VERSION ""

NS_ :

BS_:

BU_: EBOOST_HS CGM_HS BSM_HS HCP_B_HS AVM_HS PFAF_HS LVMPC_HS DCDC_HS TRCM_HS AMP_HS VICM2_HS FICM_HS ARS_HS MCP_B_HS MCP_A_HS ICCM_OBD_HS SAS_HS ACCM_HS VLBS_HS EBCM_OBD_HS HCP_T_HS EDI_HS HPCC_HS VITM_OBD_HS VICM_HS HCP_HS APPS_HS ICCM_HS EOCM_F_HS GPCM_HS VCM_HS HMIM_HS VES_HS Dummy_HS MCP_C_HS ONSTAR_HS EPS_HS TestTool_HS MCP_HS BCP_HS ALC_HS AHL_AFL_HS SADS_HS EPB_HS FCM_HS TCCM_HS RDCM_HS PTO_HS EBCM_HS ACC_HS BCM_HS TCM_HS ECM_HS

BO_ 565 Performan_Mode_Cust_Setings_1_HS: 5 EBCM_HS
 SG_ PerfMdMainMenuType : 2|3@0+ (1,0) [0|7] ""  BCM_HS
 SG_ PSPMCA_PsngStPrfMd6Avl : 24|1@0+ (1,0) [0|1] ""  BCM_HS
 SG_ PSPMCA_PsngStPrfMd5Avl : 25|1@0+ (1,0) [0|1] ""  BCM_HS
 SG_ PSPMCA_PsngStPrfMd4Avl : 26|1@0+ (1,0) [0|1] ""  BCM_HS
 SG_ PSPMCA_PsngStPrfMd3Avl : 27|1@0+ (1,0) [0|1] ""  BCM_HS
 SG_ PSPMCA_PsngStPrfMd2Avl : 28|1@0+ (1,0) [0|1] ""  BCM_HS
 SG_ PSPMCA_PsngStPrfMd1Avl : 29|1@0+ (1,0) [0|1] ""  BCM_HS
 SG_ DSPMCA_DrvStyPrfMd7Avl : 32|1@0+ (1,0) [0|1] ""  BCM_HS
 SG_ DSPMCA_DrvStyPrfMd6Avl : 33|1@0+ (1,0) [0|1] ""  BCM_HS
 SG_ DSPMCA_DrvStyPrfMd5Avl : 34|1@0+ (1,0) [0|1] ""  BCM_HS
 SG_ DSPMCA_DrvStyPrfMd4Avl : 35|1@0+ (1,0) [0|1] ""  BCM_HS
 SG_ DSPMCA_DrvStyPrfMd3Avl : 36|1@0+ (1,0) [0|1] ""  BCM_HS
 SG_ DSPMCA_DrvStyPrfMd2Avl : 37|1@0+ (1,0) [0|1] ""  BCM_HS
 SG_ DSPMCA_DrvStyPrfMd1Avl : 38|1@0+ (1,0) [0|1] ""  BCM_HS
 SG_ DSPMCA_DrvrStPrfMd6Avl : 16|1@0+ (1,0) [0|1] ""  BCM_HS
 SG_ DSPMCA_DrvrStPrfMd5Avl : 17|1@0+ (1,0) [0|1] ""  BCM_HS
 SG_ DSPMCA_DrvrStPrfMd4Avl : 18|1@0+ (1,0) [0|1] ""  BCM_HS
 SG_ DSPMCA_DrvrStPrfMd3Avl : 19|1@0+ (1,0) [0|1] ""  BCM_HS
 SG_ DSPMCA_DrvrStPrfMd2Avl : 20|1@0+ (1,0) [0|1] ""  BCM_HS
 SG_ DSPMCA_DrvrStPrfMd1Avl : 21|1@0+ (1,0) [0|1] ""  BCM_HS
 SG_ ACCPMCA_ACCPrfMd6Avl : 8|1@0+ (1,0) [0|1] ""  BCM_HS
 SG_ ACCPMCA_ACCPrfMd5Avl : 9|1@0+ (1,0) [0|1] ""  BCM_HS
 SG_ ACCPMCA_ACCPrfMd4Avl : 10|1@0+ (1,0) [0|1] ""  BCM_HS
 SG_ ACCPMCA_ACCPrfMd3Avl : 11|1@0+ (1,0) [0|1] ""  BCM_HS
 SG_ ACCPMCA_ACCPrfMd2Avl : 12|1@0+ (1,0) [0|1] ""  BCM_HS
 SG_ ACCPMCA_ACCPrfMd1Avl : 13|1@0+ (1,0) [0|1] ""  BCM_HS

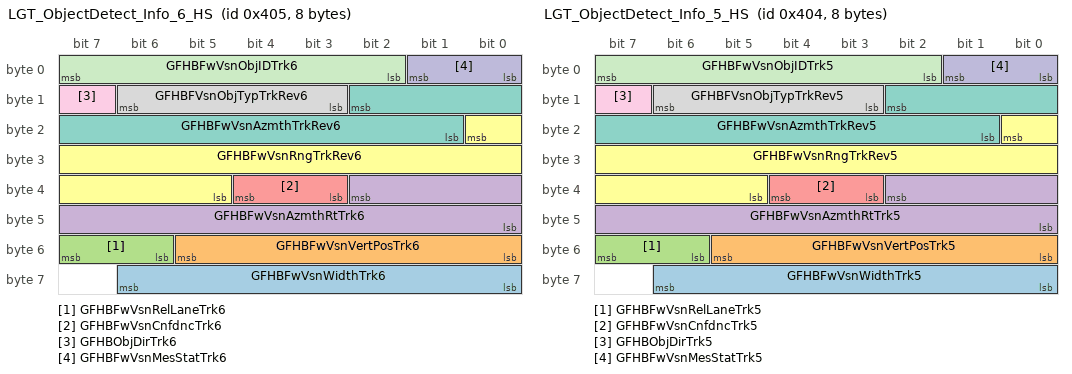
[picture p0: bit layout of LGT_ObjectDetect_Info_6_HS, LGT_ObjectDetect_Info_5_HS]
BO_ 1029 LGT_ObjectDetect_Info_6_HS: 8 EOCM_F_HS
 SG_ GFHBFwVsnWidthTrk6 : 62|7@0+ (0.1,0) [0|12.7] "deg"  AHL_AFL_HS
 SG_ GFHBFwVsnVertPosTrk6 : 53|6@0+ (0.25,-3) [-3|12.75] "deg"  AHL_AFL_HS
 SG_ GFHBFwVsnRelLaneTrk6 : 55|2@0+ (1,0) [0|3] ""  AHL_AFL_HS
 SG_ GFHBFwVsnAzmthRtTrk6 : 34|11@0- (0.125,0) [-128|127.875] "deg/s"  AHL_AFL_HS
 SG_ GFHBFwVsnCnfdncTrk6 : 36|2@0+ (1,0) [0|3] ""  AHL_AFL_HS
 SG_ GFHBFwVsnRngTrkRev6 : 16|12@0+ (0.2,0) [0|819] "m"  AHL_AFL_HS
 SG_ GFHBFwVsnAzmthTrkRev6 : 10|10@0- (0.05,0) [-25.6|25.55] "deg"  AHL_AFL_HS
 SG_ GFHBFVsnObjTypTrkRev6 : 14|4@0+ (1,0) [0|15] ""  AHL_AFL_HS
 SG_ GFHBObjDirTrk6 : 15|1@0+ (1,0) [0|1] ""  AHL_AFL_HS
 SG_ GFHBFwVsnMesStatTrk6 : 1|2@0+ (1,0) [0|3] ""  AHL_AFL_HS
 SG_ GFHBFwVsnObjIDTrk6 : 7|6@0+ (1,0) [0|63] ""  AHL_AFL_HS

BO_ 1028 LGT_ObjectDetect_Info_5_HS: 8 EOCM_F_HS
 SG_ GFHBFwVsnWidthTrk5 : 62|7@0+ (0.1,0) [0|12.7] "deg"  AHL_AFL_HS
 SG_ GFHBFwVsnVertPosTrk5 : 53|6@0+ (0.25,-3) [-3|12.75] "deg"  AHL_AFL_HS
 SG_ GFHBFwVsnRelLaneTrk5 : 55|2@0+ (1,0) [0|3] ""  AHL_AFL_HS
 SG_ GFHBFwVsnAzmthRtTrk5 : 34|11@0- (0.125,0) [-128|127.875] "deg/s"  AHL_AFL_HS
 SG_ GFHBFwVsnCnfdncTrk5 : 36|2@0+ (1,0) [0|3] ""  AHL_AFL_HS
 SG_ GFHBFwVsnRngTrkRev5 : 16|12@0+ (0.2,0) [0|819] "m"  AHL_AFL_HS
 SG_ GFHBFwVsnAzmthTrkRev5 : 10|10@0- (0.05,0) [-25.6|25.55] "deg"  AHL_AFL_HS
 SG_ GFHBFVsnObjTypTrkRev5 : 14|4@0+ (1,0) [0|15] ""  AHL_AFL_HS
 SG_ GFHBObjDirTrk5 : 15|1@0+ (1,0) [0|1] ""  AHL_AFL_HS
 SG_ GFHBFwVsnMesStatTrk5 : 1|2@0+ (1,0) [0|3] ""  AHL_AFL_HS
 SG_ GFHBFwVsnObjIDTrk5 : 7|6@0+ (1,0) [0|63] ""  AHL_AFL_HS

BO_ 500 PPEI_Drv_Pref_Mode_Switch_Status: 6 ECM_HS
 SG_ EnhDrvMdSwChUseAct : 40|1@0+ (1,0) [0|1] ""  EBCM_OBD_HS,EBCM_HS
 SG_ EnhDrvSelMdSwStat : 42|2@0+ (1,0) [0|3] ""  EBCM_OBD_HS,EBCM_HS
 SG_ DrvSelMd8Stat : 17|1@0+ (1,0) [0|1] ""  EBCM_OBD_HS,EBCM_HS,RDCM_HS,SADS_HS,BCM_HS
 SG_ DrvSelMd8ReqDnd : 16|1@0+ (1,0) [0|1] ""  RDCM_HS,BCM_HS
 SG_ DrvSelMd7Stat : 19|1@0+ (1,0) [0|1] ""  RDCM_HS,EBCM_OBD_HS,EBCM_HS,SADS_HS,BCM_HS
 SG_ DrvSelMd7ReqDnd : 18|1@0+ (1,0) [0|1] ""  RDCM_HS,BCM_HS
 SG_ DrvSelMd6Stat : 21|1@0+ (1,0) [0|1] ""  RDCM_HS,SADS_HS,EBCM_OBD_HS,EBCM_HS,BCM_HS
 SG_ DrvSelMd6ReqDnd : 20|1@0+ (1,0) [0|1] ""  RDCM_HS,BCM_HS
 SG_ DrvSelMd5Stat : 23|1@0+ (1,0) [0|1] ""  RDCM_HS,SADS_HS,EBCM_OBD_HS,EBCM_HS,BCM_HS
 SG_ DrvSelMd5ReqDnd : 22|1@0+ (1,0) [0|1] ""  RDCM_HS,BCM_HS
 SG_ DrvSelMd4Stat : 9|1@0+ (1,0) [0|1] ""  RDCM_HS,SADS_HS,EBCM_OBD_HS,EBCM_HS,BCM_HS
 SG_ DrvSelMd4ReqDnd : 8|1@0+ (1,0) [0|1] ""  RDCM_HS,BCM_HS
 SG_ DrvSelMd3Stat : 11|1@0+ (1,0) [0|1] ""  RDCM_HS,SADS_HS,EBCM_OBD_HS,EBCM_HS,BCM_HS
 SG_ DrvSelMd3ReqDnd : 10|1@0+ (1,0) [0|1] ""  RDCM_HS,BCM_HS
 SG_ DrvSelMd2Stat : 13|1@0+ (1,0) [0|1] ""  RDCM_HS,SADS_HS,EBCM_OBD_HS,EBCM_HS,BCM_HS
 SG_ DrvSelMd2ReqDnd : 12|1@0+ (1,0) [0|1] ""  RDCM_HS,BCM_HS
 SG_ DSMSS_DrvSelMd0Pn : 47|1@0+ (1,0) [0|1] ""  EBCM_OBD_HS,EBCM_HS,RDCM_HS,BCM_HS
 SG_ DSMSS_DrvSelMd8Pn : 32|1@0+ (1,0) [0|1] ""  EBCM_OBD_HS,EBCM_HS,RDCM_HS,BCM_HS
 SG_ DSMSS_DrvSelMd7Pn : 33|1@0+ (1,0) [0|1] ""  EBCM_OBD_HS,EBCM_HS,RDCM_HS,BCM_HS
 SG_ DSMSS_DrvSelMd6Pn : 34|1@0+ (1,0) [0|1] ""  EBCM_OBD_HS,EBCM_HS,RDCM_HS,BCM_HS
 SG_ DSMSS_DrvSelMd5Pn : 35|1@0+ (1,0) [0|1] ""  EBCM_OBD_HS,EBCM_HS,RDCM_HS,BCM_HS
 SG_ DSMSS_DrvSelMd4Pn : 36|1@0+ (1,0) [0|1] ""  EBCM_OBD_HS,EBCM_HS,RDCM_HS,BCM_HS
 SG_ DSMSS_DrvSelMd3Pn : 37|1@0+ (1,0) [0|1] ""  EBCM_OBD_HS,EBCM_HS,RDCM_HS,BCM_HS
 SG_ DSMSS_DrvSelMd2Pn : 38|1@0+ (1,0) [0|1] ""  EBCM_OBD_HS,EBCM_HS,RDCM_HS,BCM_HS
 SG_ DSMSS_DrvSelMd1Pn : 39|1@0+ (1,0) [0|1] ""  EBCM_OBD_HS,EBCM_HS,RDCM_HS,BCM_HS
 SG_ DSMSS_DrvSelMd8Un : 24|1@0+ (1,0) [0|1] ""  EBCM_OBD_HS,EBCM_HS,RDCM_HS,BCM_HS
 SG_ DSMSS_DrvSelMd7Un : 25|1@0+ (1,0) [0|1] ""  EBCM_OBD_HS,EBCM_HS,RDCM_HS,BCM_HS
 SG_ DSMSS_DrvSelMd6Un : 26|1@0+ (1,0) [0|1] ""  EBCM_OBD_HS,EBCM_HS,RDCM_HS,BCM_HS
 SG_ DSMSS_DrvSelMd5Un : 27|1@0+ (1,0) [0|1] ""  EBCM_OBD_HS,EBCM_HS,RDCM_HS,BCM_HS
 SG_ DSMSS_DrvSelMd4Un : 28|1@0+ (1,0) [0|1] ""  EBCM_OBD_HS,EBCM_HS,RDCM_HS,BCM_HS
 SG_ DSMSS_DrvSelMd3Un : 29|1@0+ (1,0) [0|1] ""  EBCM_OBD_HS,EBCM_HS,RDCM_HS,BCM_HS
 SG_ DSMSS_DrvSelMd2Un : 30|1@0+ (1,0) [0|1] ""  EBCM_OBD_HS,EBCM_HS,RDCM_HS,BCM_HS
 SG_ DSMSS_DrvSelMd1Un : 31|1@0+ (1,0) [0|1] ""  EBCM_OBD_HS,EBCM_HS,RDCM_HS,BCM_HS
 SG_ DrvSelMd1ReqDnd : 14|1@0+ (1,0) [0|1] ""  RDCM_HS,VICM_HS,BCM_HS
 SG_ DrvSelMd1Stat : 15|1@0+ (1,0) [0|1] ""  RDCM_HS,SADS_HS,EBCM_OBD_HS,EBCM_HS,BCM_HS

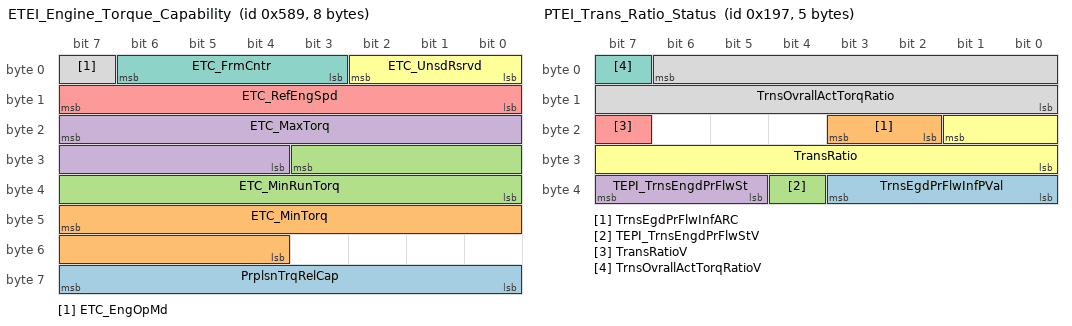
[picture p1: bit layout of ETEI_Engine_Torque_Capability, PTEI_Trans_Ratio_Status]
BO_ 1417 ETEI_Engine_Torque_Capability: 8 ECM_HS
 SG_ PrplsnTrqRelCap : 63|8@0+ (0.5,0) [0|127.5] "%"  TCM_HS
 SG_ ETC_MinTorq : 47|12@0+ (0.5,-848) [-848|1199.5] "Nm"  HCP_B_HS,HCP_T_HS,TCM_HS,HCP_HS,BCP_HS
 SG_ ETC_MinRunTorq : 27|12@0+ (0.5,-848) [-848|1199.5] "Nm"  HCP_B_HS,HCP_T_HS,TCM_HS,HCP_HS,BCP_HS
 SG_ ETC_MaxTorq : 23|12@0+ (0.5,-848) [-848|1199.5] "Nm"  HCP_B_HS,HCP_T_HS,TCM_HS,HCP_HS,BCP_HS
 SG_ ETC_RefEngSpd : 15|8@0+ (32,0) [0|8160] "rpm"  HCP_B_HS,HCP_T_HS,TCM_HS,HCP_HS,BCP_HS
 SG_ ETC_UnsdRsrvd : 2|3@0+ (1,0) [0|7] ""  HCP_B_HS,HCP_T_HS,TCM_HS,HCP_HS,BCP_HS
 SG_ ETC_FrmCntr : 6|4@0+ (1,0) [0|15] ""  HCP_B_HS,HCP_T_HS,TCM_HS,HCP_HS,BCP_HS
 SG_ ETC_EngOpMd : 7|1@0+ (1,0) [0|1] ""  HCP_B_HS,HCP_T_HS,TCM_HS,HCP_HS,BCP_HS

BO_ 407 PTEI_Trans_Ratio_Status: 5 TCM_HS
 SG_ TrnsEgdPrFlwInfPVal : 35|4@0+ (1,0) [0|15] ""  ICCM_HS
 SG_ TrnsEgdPrFlwInfARC : 19|2@0+ (1,0) [0|3] ""  ICCM_HS
 SG_ TEPI_TrnsEngdPrFlwStV : 36|1@0+ (1,0) [0|1] ""  ICCM_HS
 SG_ TEPI_TrnsEngdPrFlwSt : 39|3@0+ (1,0) [0|7] ""  ICCM_HS
 SG_ TransRatioV : 23|1@0+ (1,0) [0|1] ""  ECM_HS
 SG_ TransRatio : 17|10@0+ (0.03125,0) [0|31.96875] ""  ECM_HS
 SG_ TrnsOvrallActTorqRatioV : 7|1@0+ (1,0) [0|1] ""  ECM_HS
 SG_ TrnsOvrallActTorqRatio : 6|15@0- (0.00390625,0) [-64|63.99609375] ""  ECM_HS

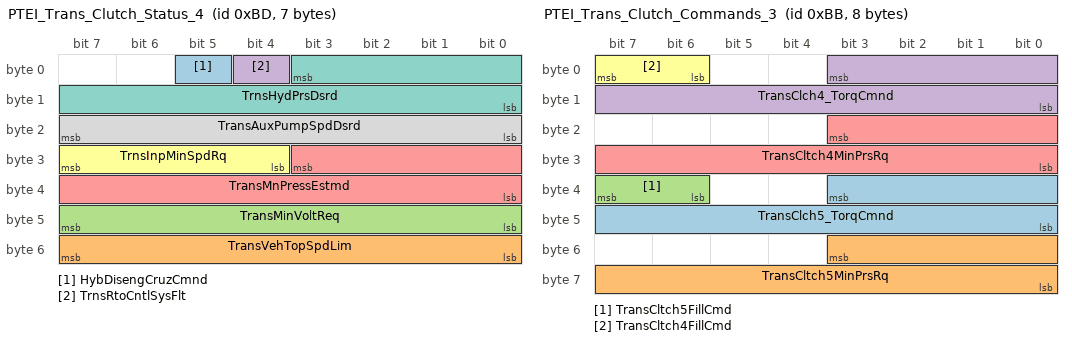
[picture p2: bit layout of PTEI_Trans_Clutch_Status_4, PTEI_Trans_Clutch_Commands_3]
BO_ 189 PTEI_Trans_Clutch_Status_4: 7 TCM_HS
 SG_ HybDisengCruzCmnd : 5|1@0+ (1,0) [0|1] ""  ECM_HS
 SG_ TransVehTopSpdLim : 55|8@0+ (2,0) [0|510] "km / h"  ECM_HS
 SG_ TransMinVoltReq : 47|8@0+ (0.07843,0) [0|19.99965] "volts"  ECM_HS
 SG_ TrnsRtoCntlSysFlt : 4|1@0+ (1,0) [0|1] ""  ECM_HS
 SG_ TransMnPressEstmd : 27|12@0+ (0.5,0) [0|2047.5] "kPa"  HCP_HS
 SG_ TrnsInpMinSpdRq : 31|4@0+ (1,0) [0|15] ""  HCP_HS
 SG_ TrnsHydPrsDsrd : 3|12@0+ (0.5,0) [0|2047.5] "kPa"  HCP_HS
 SG_ TransAuxPumpSpdDsrd : 23|8@0+ (0.392157,0) [0|100.000035] "%"  HCP_HS

BO_ 187 PTEI_Trans_Clutch_Commands_3: 8 HCP_HS
 SG_ TransClch5_TorqCmnd : 35|12@0+ (0.5,-5) [-5|2042.5] "Nm"  TCM_HS
 SG_ TransCltch5MinPrsRq : 51|12@0+ (0.5,0) [0|2047.5] "kPa"  TCM_HS
 SG_ TransCltch5FillCmd : 39|2@0+ (1,0) [0|3] ""  TCM_HS
 SG_ TransClch4_TorqCmnd : 3|12@0+ (0.5,-5) [-5|2042.5] "Nm"  TCM_HS
 SG_ TransCltch4MinPrsRq : 19|12@0+ (0.5,0) [0|2047.5] "kPa"  TCM_HS
 SG_ TransCltch4FillCmd : 7|2@0+ (1,0) [0|3] ""  TCM_HS

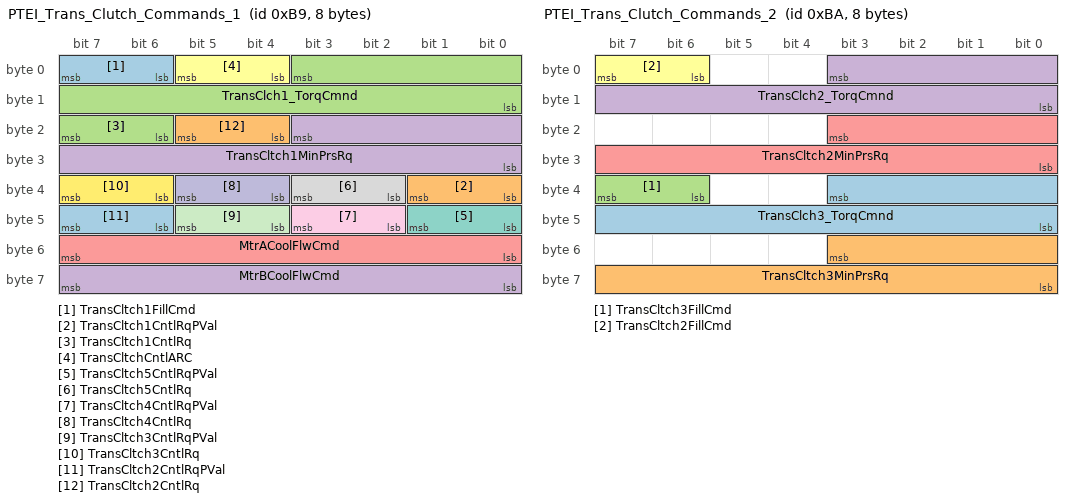
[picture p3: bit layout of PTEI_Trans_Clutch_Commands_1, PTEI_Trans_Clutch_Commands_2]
BO_ 185 PTEI_Trans_Clutch_Commands_1: 8 HCP_HS
 SG_ TransCltch1FillCmd : 7|2@0+ (1,0) [0|3] ""  TCM_HS
 SG_ TransCltch1CntlRqPVal : 33|2@0+ (1,0) [0|3] ""  TCM_HS
 SG_ TransCltch1CntlRq : 23|2@0+ (1,0) [0|3] ""  TCM_HS
 SG_ MtrBCoolFlwCmd : 63|8@0+ (0.05,0) [0|12.75] "l/min"  TCM_HS
 SG_ MtrACoolFlwCmd : 55|8@0+ (0.05,0) [0|12.75] "l/min"  TCM_HS
 SG_ TransCltchCntlARC : 5|2@0+ (1,0) [0|3] ""  TCM_HS
 SG_ TransCltch5CntlRqPVal : 41|2@0+ (1,0) [0|3] ""  TCM_HS
 SG_ TransCltch5CntlRq : 35|2@0+ (1,0) [0|3] ""  TCM_HS
 SG_ TransCltch4CntlRqPVal : 43|2@0+ (1,0) [0|3] ""  TCM_HS
 SG_ TransCltch4CntlRq : 37|2@0+ (1,0) [0|3] ""  TCM_HS
 SG_ TransCltch3CntlRqPVal : 45|2@0+ (1,0) [0|3] ""  TCM_HS
 SG_ TransCltch3CntlRq : 39|2@0+ (1,0) [0|3] ""  TCM_HS
 SG_ TransCltch2CntlRqPVal : 47|2@0+ (1,0) [0|3] ""  TCM_HS
 SG_ TransCltch2CntlRq : 21|2@0+ (1,0) [0|3] ""  TCM_HS
 SG_ TransClch1_TorqCmnd : 3|12@0+ (0.5,-5) [-5|2042.5] "Nm"  TCM_HS
 SG_ TransCltch1MinPrsRq : 19|12@0+ (0.5,0) [0|2047.5] "kPa"  TCM_HS

BO_ 186 PTEI_Trans_Clutch_Commands_2: 8 HCP_HS
 SG_ TransClch3_TorqCmnd : 35|12@0+ (0.5,-5) [-5|2042.5] "Nm"  TCM_HS
 SG_ TransCltch3MinPrsRq : 51|12@0+ (0.5,0) [0|2047.5] "kPa"  TCM_HS
 SG_ TransCltch3FillCmd : 39|2@0+ (1,0) [0|3] ""  TCM_HS
 SG_ TransClch2_TorqCmnd : 3|12@0+ (0.5,-5) [-5|2042.5] "Nm"  TCM_HS
 SG_ TransCltch2MinPrsRq : 19|12@0+ (0.5,0) [0|2047.5] "kPa"  TCM_HS
 SG_ TransCltch2FillCmd : 7|2@0+ (1,0) [0|3] ""  TCM_HS

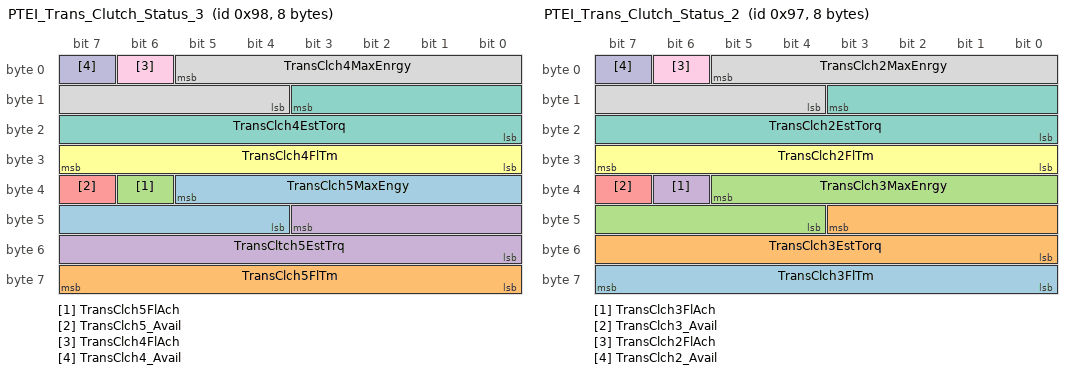
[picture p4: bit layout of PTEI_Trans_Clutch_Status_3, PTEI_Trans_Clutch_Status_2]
BO_ 152 PTEI_Trans_Clutch_Status_3: 8 TCM_HS
 SG_ TransClch5MaxEngy : 37|10@0+ (50,0) [0|51150] "J"  HCP_HS
 SG_ TransClch5FlTm : 63|8@0+ (0.0125,0) [0|3.1875] "s"  HCP_HS
 SG_ TransClch5FlAch : 38|1@0+ (1,0) [0|1] ""  HCP_HS
 SG_ TransCltch5EstTrq : 43|12@0+ (0.5,-5) [-5|2042.5] "Nm"  HCP_HS
 SG_ TransClch5_Avail : 39|1@0+ (1,0) [0|1] ""  HCP_HS
 SG_ TransClch4FlTm : 31|8@0+ (0.0125,0) [0|3.1875] "s"  HCP_HS
 SG_ TransClch4EstTorq : 11|12@0+ (0.5,-5) [-5|2042.5] "Nm"  HCP_HS
 SG_ TransClch4MaxEnrgy : 5|10@0+ (50,0) [0|51150] "J"  HCP_HS
 SG_ TransClch4FlAch : 6|1@0+ (1,0) [0|1] ""  HCP_HS
 SG_ TransClch4_Avail : 7|1@0+ (1,0) [0|1] ""  HCP_HS

BO_ 151 PTEI_Trans_Clutch_Status_2: 8 TCM_HS
 SG_ TransClch3FlTm : 63|8@0+ (0.0125,0) [0|3.1875] "s"  HCP_HS
 SG_ TransClch3EstTorq : 43|12@0+ (0.5,-5) [-5|2042.5] "Nm"  HCP_HS
 SG_ TransClch3MaxEnrgy : 37|10@0+ (50,0) [0|51150] "J"  HCP_HS
 SG_ TransClch3FlAch : 38|1@0+ (1,0) [0|1] ""  HCP_HS
 SG_ TransClch3_Avail : 39|1@0+ (1,0) [0|1] ""  HCP_HS
 SG_ TransClch2FlTm : 31|8@0+ (0.0125,0) [0|3.1875] "s"  HCP_HS
 SG_ TransClch2EstTorq : 11|12@0+ (0.5,-5) [-5|2042.5] "Nm"  HCP_HS
 SG_ TransClch2MaxEnrgy : 5|10@0+ (50,0) [0|51150] "J"  HCP_HS
 SG_ TransClch2FlAch : 6|1@0+ (1,0) [0|1] ""  HCP_HS
 SG_ TransClch2_Avail : 7|1@0+ (1,0) [0|1] ""  HCP_HS

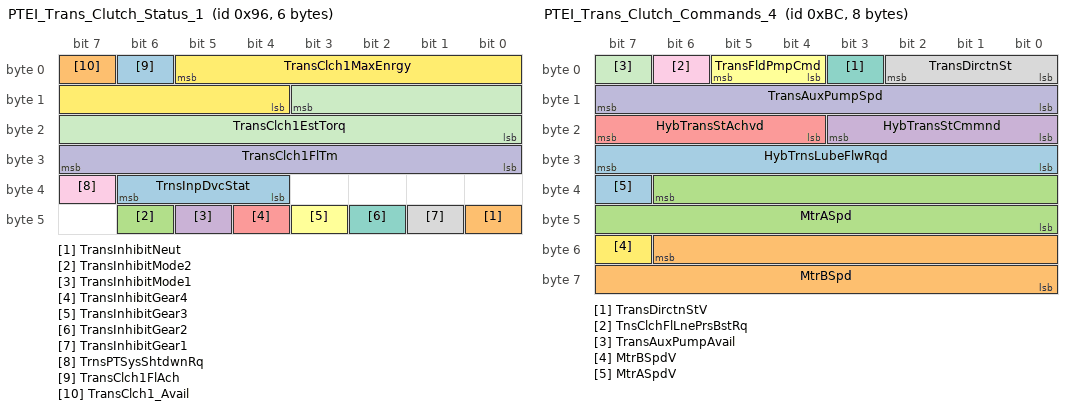
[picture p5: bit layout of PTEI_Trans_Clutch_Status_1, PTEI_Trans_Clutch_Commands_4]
BO_ 150 PTEI_Trans_Clutch_Status_1: 6 TCM_HS
 SG_ TrnsInpDvcStat : 38|3@0+ (1,0) [0|7] ""  HCP_HS
 SG_ TransInhibitNeut : 40|1@0+ (1,0) [0|1] ""  HCP_HS
 SG_ TransInhibitMode2 : 46|1@0+ (1,0) [0|1] ""  HCP_HS
 SG_ TransInhibitMode1 : 45|1@0+ (1,0) [0|1] ""  HCP_HS
 SG_ TransInhibitGear4 : 44|1@0+ (1,0) [0|1] ""  HCP_HS
 SG_ TransInhibitGear3 : 43|1@0+ (1,0) [0|1] ""  HCP_HS
 SG_ TransInhibitGear2 : 42|1@0+ (1,0) [0|1] ""  HCP_HS
 SG_ TransInhibitGear1 : 41|1@0+ (1,0) [0|1] ""  HCP_HS
 SG_ TrnsPTSysShtdwnRq : 39|1@0+ (1,0) [0|1] ""  HCP_HS
 SG_ TransClch1FlTm : 31|8@0+ (0.0125,0) [0|3.1875] "s"  HCP_HS
 SG_ TransClch1EstTorq : 11|12@0+ (0.5,-5) [-5|2042.5] "Nm"  HCP_HS
 SG_ TransClch1MaxEnrgy : 5|10@0+ (50,0) [0|51150] "J"  HCP_HS
 SG_ TransClch1FlAch : 6|1@0+ (1,0) [0|1] ""  HCP_HS
 SG_ TransClch1_Avail : 7|1@0+ (1,0) [0|1] ""  HCP_HS

BO_ 188 PTEI_Trans_Clutch_Commands_4: 8 HCP_HS
 SG_ HybTrnsLubeFlwRqd : 31|8@0+ (0.0625,0) [0|15.9375] "l/min"  TCM_HS
 SG_ MtrBSpd : 54|15@0- (1,0) [-16384|16383] "rpm"  TCM_HS
 SG_ MtrASpd : 38|15@0- (1,0) [-16384|16383] "rpm"  TCM_HS
 SG_ HybTransStCmmnd : 19|4@0+ (1,0) [0|15] ""  TCM_HS
 SG_ HybTransStAchvd : 23|4@0+ (1,0) [0|15] ""  TCM_HS
 SG_ TransFldPmpCmd : 5|2@0+ (1,0) [0|3] ""  TCM_HS
 SG_ TransDirctnStV : 3|1@0+ (1,0) [0|1] ""  TCM_HS,ECM_HS
 SG_ TransDirctnSt : 2|3@0+ (1,0) [0|7] ""  TCM_HS,ECM_HS
 SG_ TnsClchFlLnePrsBstRq : 6|1@0+ (1,0) [0|1] ""  TCM_HS
 SG_ TransAuxPumpSpd : 15|8@0+ (0.392157,0) [0|100.000035] "%"  TCM_HS
 SG_ TransAuxPumpAvail : 7|1@0+ (1,0) [0|1] ""  TCM_HS
 SG_ MtrBSpdV : 55|1@0+ (1,0) [0|1] ""  TCM_HS
 SG_ MtrASpdV : 39|1@0+ (1,0) [0|1] ""  TCM_HS

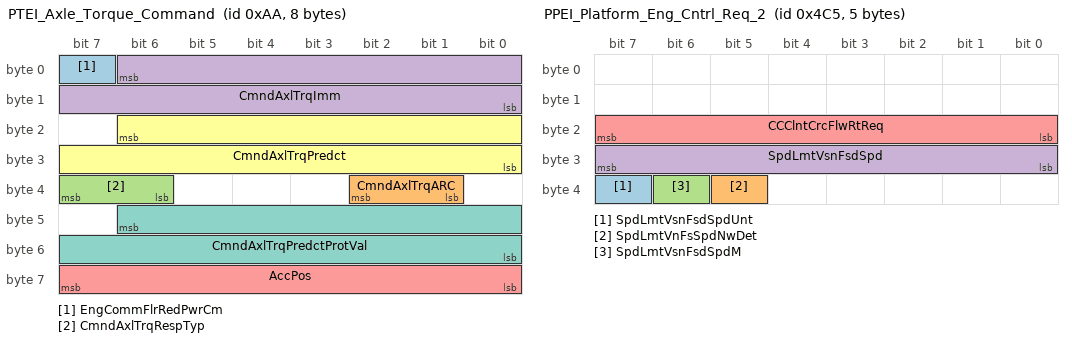
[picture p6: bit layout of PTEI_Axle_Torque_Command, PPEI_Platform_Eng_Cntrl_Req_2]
BO_ 170 PTEI_Axle_Torque_Command: 8 ECM_HS
 SG_ EngCommFlrRedPwrCm : 7|1@0+ (1,0) [0|1] ""  HCP_T_HS,HCP_HS
 SG_ CmndAxlTrqARC : 34|2@0+ (1,0) [0|3] ""  HCP_B_HS,HCP_T_HS,HCP_HS,EBCM_OBD_HS,EBCM_HS
 SG_ CmndAxlTrqRespTyp : 39|2@0+ (1,0) [0|3] ""  HCP_T_HS,HCP_HS
 SG_ CmndAxlTrqImm : 6|15@0+ (2,-22534) [-22534|43000] "Nm"  HCP_T_HS,HCP_HS
 SG_ AccPos : 63|8@0+ (0.392157,0) [0|100.000035] "%"  HCP_B_HS,HCP_T_HS,HCP_HS,TCM_HS
 SG_ CmndAxlTrqPredct : 22|15@0+ (2,-22534) [-22534|43000] "Nm"  HCP_B_HS,HCP_T_HS,EBCM_OBD_HS,EBCM_HS,HCP_HS
 SG_ CmndAxlTrqPredctProtVal : 46|15@0+ (1,0) [0|32767] ""  HCP_B_HS,HCP_T_HS,EBCM_OBD_HS,EBCM_HS,HCP_HS

BO_ 1221 PPEI_Platform_Eng_Cntrl_Req_2: 5 BCM_HS
 SG_ SpdLmtVsnFsdSpdUnt : 39|1@0+ (1,0) [0|1] ""  EOCM_F_HS,CGM_HS,ACC_HS,ECM_HS
 SG_ SpdLmtVnFsSpdNwDet : 37|1@0+ (1,0) [0|1] ""  EOCM_F_HS,CGM_HS,ACC_HS,ECM_HS
 SG_ SpdLmtVsnFsdSpdM : 38|1@0+ (1,0) [0|1] ""  EOCM_F_HS,CGM_HS,ACC_HS,ECM_HS
 SG_ SpdLmtVsnFsdSpd : 31|8@0+ (1,0) [0|255] ""  EOCM_F_HS,CGM_HS,ACC_HS,ECM_HS
 SG_ CCClntCrcFlwRtReq : 23|8@0+ (0.392157,0) [0|100.000035] "%"  CGM_HS,VICM2_HS,ECM_HS

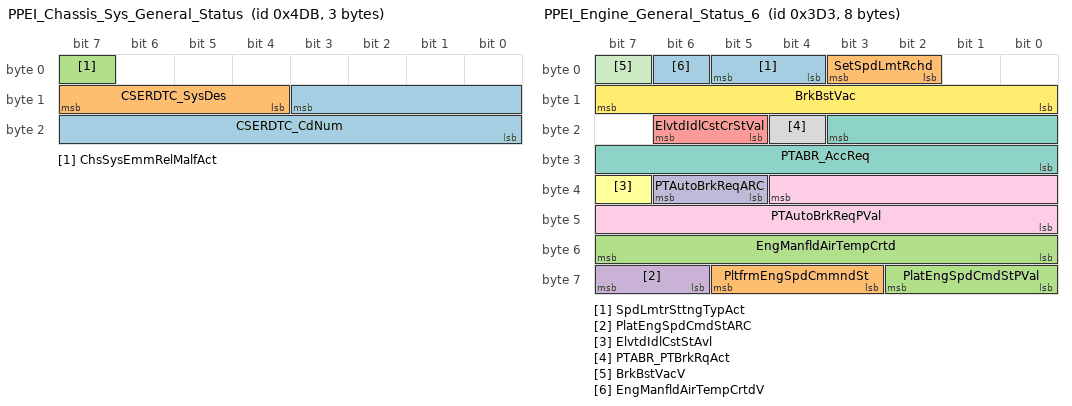
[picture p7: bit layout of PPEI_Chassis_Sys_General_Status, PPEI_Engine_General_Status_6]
BO_ 1243 PPEI_Chassis_Sys_General_Status: 3 ICCM_HS
 SG_ CSERDTC_CdNum : 11|12@0+ (1,0) [0|4095] ""  ECM_HS
 SG_ CSERDTC_SysDes : 15|4@0+ (1,0) [0|15] ""  ECM_HS
 SG_ ChsSysEmmRelMalfAct : 7|1@0+ (1,0) [0|1] ""  ECM_HS

BO_ 979 PPEI_Engine_General_Status_6: 8 ECM_HS
 SG_ SpdLmtrSttngTypAct : 5|2@0+ (1,0) [0|3] ""  BCM_HS
 SG_ SetSpdLmtRchd : 3|2@0+ (1,0) [0|3] ""  BCM_HS
 SG_ PlatEngSpdCmdStPVal : 58|3@0+ (1,0) [0|7] ""  PTO_HS
 SG_ PlatEngSpdCmdStARC : 63|2@0+ (1,0) [0|3] ""  PTO_HS
 SG_ ElvtdIdlCstCrStVal : 22|2@0+ (1,0) [0|3] ""  BCM_HS
 SG_ ElvtdIdlCstStAvl : 39|1@0+ (1,0) [0|1] ""  BCM_HS
 SG_ PTABR_AccReq : 19|12@0- (0.01,0) [-20.48|20.47] "m/s^2"  EBCM_OBD_HS,EBCM_HS
 SG_ PTABR_PTBrkRqAct : 20|1@0+ (1,0) [0|1] ""  EBCM_OBD_HS,EBCM_HS
 SG_ PTAutoBrkReqPVal : 36|13@0+ (1,0) [0|8191] ""  EBCM_OBD_HS,EBCM_HS
 SG_ PTAutoBrkReqARC : 38|2@0+ (1,0) [0|3] ""  EBCM_OBD_HS,EBCM_HS
 SG_ BrkBstVacV : 7|1@0+ (1,0) [0|1] ""  EBCM_OBD_HS,EBCM_HS
 SG_ BrkBstVac : 15|8@0+ (0.5,0) [0|127.5] "kPa"  EBCM_OBD_HS,EBCM_HS
 SG_ EngManfldAirTempCrtdV : 6|1@0+ (1,0) [0|1] ""  BCM_HS
 SG_ PltfrmEngSpdCmmndSt : 61|3@0+ (1,0) [0|7] ""  PTO_HS
 SG_ EngManfldAirTempCrtd : 55|8@0+ (1,-40) [-40|215] "deg C"  BCM_HS

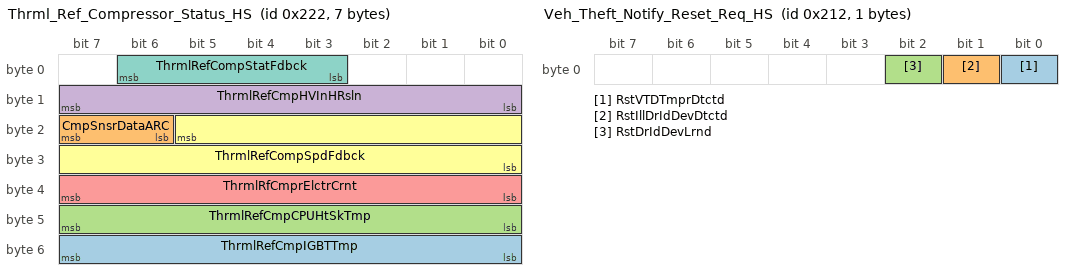
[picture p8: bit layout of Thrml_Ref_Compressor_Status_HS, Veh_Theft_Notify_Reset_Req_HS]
BO_ 546 Thrml_Ref_Compressor_Status_HS: 7 ACCM_HS
 SG_ ThrmlRefCmpIGBTTmp : 55|8@0+ (1,-40) [-40|215] "deg C"  BSM_HS,VICM_HS
 SG_ CmpSnsrDataARC : 23|2@0+ (1,0) [0|3] "N/A"  BSM_HS,VICM_HS
 SG_ ThrmlRefCmpCPUHtSkTmp : 47|8@0+ (1,-40) [-40|215] "deg C"  BSM_HS,VICM_HS
 SG_ ThrmlRefCmpHVInHRsln : 15|8@0+ (2.5,0) [0|637.5] "V"  BSM_HS,VICM_HS
 SG_ ThrmlRfCmprElctrCrnt : 39|8@0+ (0.2,0) [0|51] "A"  BSM_HS,VICM_HS
 SG_ ThrmlRefCompSpdFdbck : 21|14@0+ (1,0) [0|16383] "rpm"  BSM_HS,VICM_HS
 SG_ ThrmlRefCompStatFdbck : 6|4@0+ (1,0) [0|15] " "  BSM_HS,VICM_HS

BO_ 530 Veh_Theft_Notify_Reset_Req_HS: 1 VLBS_HS
 SG_ RstVTDTmprDtctd : 0|1@0+ (1,0) [0|1] ""  BCM_HS
 SG_ RstIllDrIdDevDtctd : 1|1@0+ (1,0) [0|1] ""  BCM_HS
 SG_ RstDrIdDevLrnd : 2|1@0+ (1,0) [0|1] ""  BCM_HS

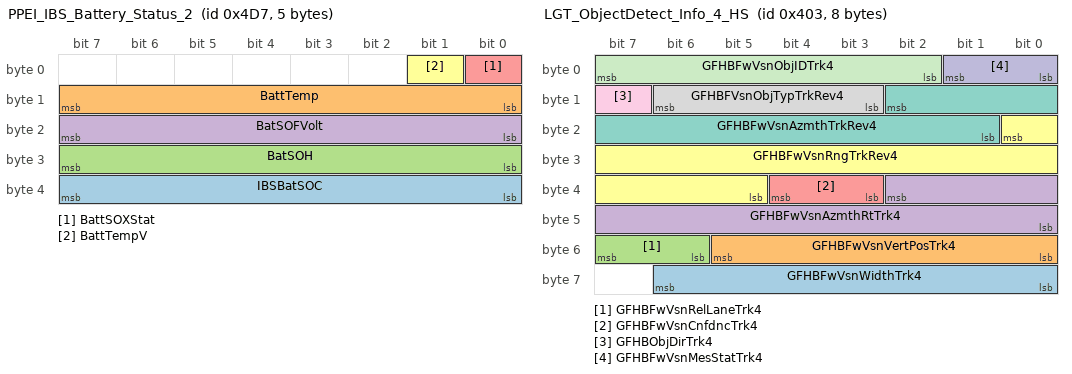
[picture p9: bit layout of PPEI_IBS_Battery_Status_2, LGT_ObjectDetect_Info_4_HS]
BO_ 1239 PPEI_IBS_Battery_Status_2: 5 BCM_HS
 SG_ IBSBatSOC : 39|8@0+ (0.392157,0) [0|100.000035] "%"  ECM_HS
 SG_ BattTemp : 15|8@0+ (1,-40) [-40|215] "deg C"  ECM_HS
 SG_ BatSOH : 31|8@0+ (0.392157,0) [0|100.000035] "%"  ECM_HS
 SG_ BatSOFVolt : 23|8@0+ (0.05,0) [0|12.75] "volts"  ECM_HS
 SG_ BattSOXStat : 0|1@0+ (1,0) [0|1] ""  ECM_HS
 SG_ BattTempV : 1|1@0+ (1,0) [0|1] ""  ECM_HS

BO_ 1610 USDT_Resp_From_SAS_HS: 8 SAS_HS
 SG_ DgnInf : 7|64@0+ (1,0) [0|1.84467440737096E+019] ""  CGM_HS,ONSTAR_HS,TestTool_HS

BO_ 1027 LGT_ObjectDetect_Info_4_HS: 8 EOCM_F_HS
 SG_ GFHBFwVsnWidthTrk4 : 62|7@0+ (0.1,0) [0|12.7] "deg"  AHL_AFL_HS
 SG_ GFHBFwVsnVertPosTrk4 : 53|6@0+ (0.25,-3) [-3|12.75] "deg"  AHL_AFL_HS
 SG_ GFHBFwVsnRelLaneTrk4 : 55|2@0+ (1,0) [0|3] ""  AHL_AFL_HS
 SG_ GFHBFwVsnAzmthRtTrk4 : 34|11@0- (0.125,0) [-128|127.875] "deg/s"  AHL_AFL_HS
 SG_ GFHBFwVsnCnfdncTrk4 : 36|2@0+ (1,0) [0|3] ""  AHL_AFL_HS
 SG_ GFHBFwVsnRngTrkRev4 : 16|12@0+ (0.2,0) [0|819] "m"  AHL_AFL_HS
 SG_ GFHBFwVsnAzmthTrkRev4 : 10|10@0- (0.05,0) [-25.6|25.55] "deg"  AHL_AFL_HS
 SG_ GFHBFVsnObjTypTrkRev4 : 14|4@0+ (1,0) [0|15] ""  AHL_AFL_HS
 SG_ GFHBObjDirTrk4 : 15|1@0+ (1,0) [0|1] ""  AHL_AFL_HS
 SG_ GFHBFwVsnMesStatTrk4 : 1|2@0+ (1,0) [0|3] ""  AHL_AFL_HS
 SG_ GFHBFwVsnObjIDTrk4 : 7|6@0+ (1,0) [0|63] ""  AHL_AFL_HS

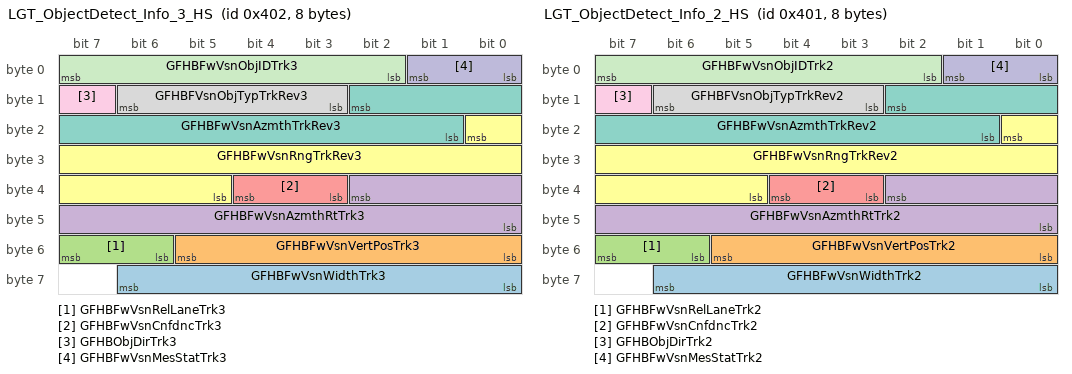
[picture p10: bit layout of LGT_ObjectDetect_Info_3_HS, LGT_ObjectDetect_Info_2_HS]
BO_ 1026 LGT_ObjectDetect_Info_3_HS: 8 EOCM_F_HS
 SG_ GFHBFwVsnWidthTrk3 : 62|7@0+ (0.1,0) [0|12.7] "deg"  AHL_AFL_HS
 SG_ GFHBFwVsnVertPosTrk3 : 53|6@0+ (0.25,-3) [-3|12.75] "deg"  AHL_AFL_HS
 SG_ GFHBFwVsnRelLaneTrk3 : 55|2@0+ (1,0) [0|3] ""  AHL_AFL_HS
 SG_ GFHBFwVsnAzmthRtTrk3 : 34|11@0- (0.125,0) [-128|127.875] "deg/s"  AHL_AFL_HS
 SG_ GFHBFwVsnCnfdncTrk3 : 36|2@0+ (1,0) [0|3] ""  AHL_AFL_HS
 SG_ GFHBFwVsnRngTrkRev3 : 16|12@0+ (0.2,0) [0|819] "m"  AHL_AFL_HS
 SG_ GFHBFwVsnAzmthTrkRev3 : 10|10@0- (0.05,0) [-25.6|25.55] "deg"  AHL_AFL_HS
 SG_ GFHBFVsnObjTypTrkRev3 : 14|4@0+ (1,0) [0|15] ""  AHL_AFL_HS
 SG_ GFHBObjDirTrk3 : 15|1@0+ (1,0) [0|1] ""  AHL_AFL_HS
 SG_ GFHBFwVsnMesStatTrk3 : 1|2@0+ (1,0) [0|3] ""  AHL_AFL_HS
 SG_ GFHBFwVsnObjIDTrk3 : 7|6@0+ (1,0) [0|63] ""  AHL_AFL_HS

BO_ 1025 LGT_ObjectDetect_Info_2_HS: 8 EOCM_F_HS
 SG_ GFHBFwVsnWidthTrk2 : 62|7@0+ (0.1,0) [0|12.7] "deg"  AHL_AFL_HS
 SG_ GFHBFwVsnVertPosTrk2 : 53|6@0+ (0.25,-3) [-3|12.75] "deg"  AHL_AFL_HS
 SG_ GFHBFwVsnRelLaneTrk2 : 55|2@0+ (1,0) [0|3] ""  AHL_AFL_HS
 SG_ GFHBFwVsnAzmthRtTrk2 : 34|11@0- (0.125,0) [-128|127.875] "deg/s"  AHL_AFL_HS
 SG_ GFHBFwVsnCnfdncTrk2 : 36|2@0+ (1,0) [0|3] ""  AHL_AFL_HS
 SG_ GFHBFwVsnRngTrkRev2 : 16|12@0+ (0.2,0) [0|819] "m"  AHL_AFL_HS
 SG_ GFHBFwVsnAzmthTrkRev2 : 10|10@0- (0.05,0) [-25.6|25.55] "deg"  AHL_AFL_HS
 SG_ GFHBFVsnObjTypTrkRev2 : 14|4@0+ (1,0) [0|15] ""  AHL_AFL_HS
 SG_ GFHBObjDirTrk2 : 15|1@0+ (1,0) [0|1] ""  AHL_AFL_HS
 SG_ GFHBFwVsnMesStatTrk2 : 1|2@0+ (1,0) [0|3] ""  AHL_AFL_HS
 SG_ GFHBFwVsnObjIDTrk2 : 7|6@0+ (1,0) [0|63] ""  AHL_AFL_HS

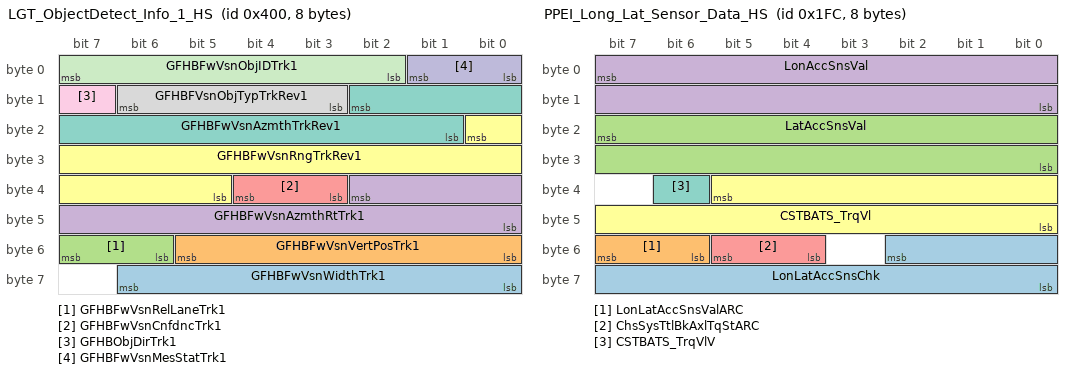
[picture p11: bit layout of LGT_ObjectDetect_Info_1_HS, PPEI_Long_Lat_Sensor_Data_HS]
BO_ 1024 LGT_ObjectDetect_Info_1_HS: 8 EOCM_F_HS
 SG_ GFHBFwVsnWidthTrk1 : 62|7@0+ (0.1,0) [0|12.7] "deg"  AHL_AFL_HS
 SG_ GFHBFwVsnVertPosTrk1 : 53|6@0+ (0.25,-3) [-3|12.75] "deg"  AHL_AFL_HS
 SG_ GFHBFwVsnRelLaneTrk1 : 55|2@0+ (1,0) [0|3] ""  AHL_AFL_HS
 SG_ GFHBFwVsnAzmthRtTrk1 : 34|11@0- (0.125,0) [-128|127.875] "deg/s"  AHL_AFL_HS
 SG_ GFHBFwVsnCnfdncTrk1 : 36|2@0+ (1,0) [0|3] ""  AHL_AFL_HS
 SG_ GFHBFwVsnRngTrkRev1 : 16|12@0+ (0.2,0) [0|819] "m"  AHL_AFL_HS
 SG_ GFHBFwVsnAzmthTrkRev1 : 10|10@0- (0.05,0) [-25.6|25.55] "deg"  AHL_AFL_HS
 SG_ GFHBFVsnObjTypTrkRev1 : 14|4@0+ (1,0) [0|15] ""  AHL_AFL_HS
 SG_ GFHBObjDirTrk1 : 15|1@0+ (1,0) [0|1] ""  AHL_AFL_HS
 SG_ GFHBFwVsnMesStatTrk1 : 1|2@0+ (1,0) [0|3] ""  AHL_AFL_HS
 SG_ GFHBFwVsnObjIDTrk1 : 7|6@0+ (1,0) [0|63] ""  AHL_AFL_HS

BO_ 508 PPEI_Long_Lat_Sensor_Data_HS: 8 EBCM_HS
 SG_ LonLatAccSnsChk : 50|11@0+ (1,0) [0|2047] ""  ECM_HS,ICCM_OBD_HS,ICCM_HS,TCM_HS
 SG_ LonLatAccSnsValARC : 55|2@0+ (1,0) [0|3] ""  ECM_HS,ICCM_OBD_HS,ICCM_HS,TCM_HS
 SG_ LatAccSnsVal : 23|16@0- (0.00012207,0) [-3.99998976|3.99986769] "g's"  ECM_HS,ICCM_OBD_HS,ICCM_HS,TCM_HS
 SG_ LonAccSnsVal : 7|16@0- (0.00012207,0) [-3.99998976|3.99986769] "g's"  ECM_HS,ICCM_OBD_HS,ICCM_HS,TCM_HS
 SG_ ChsSysTtlBkAxlTqStARC : 53|2@0+ (1,0) [0|3] ""  ECM_HS
 SG_ CSTBATS_TrqVl : 37|14@0+ (2,0) [0|32766] "Nm"  HCP_B_HS,SADS_HS,ECM_HS,ICCM_OBD_HS,ICCM_HS,HCP_T_HS,TCM_HS
 SG_ CSTBATS_TrqVlV : 38|1@0+ (1,0) [0|1] ""  HCP_B_HS,SADS_HS,ECM_HS,ICCM_OBD_HS,ICCM_HS,HCP_T_HS,TCM_HS

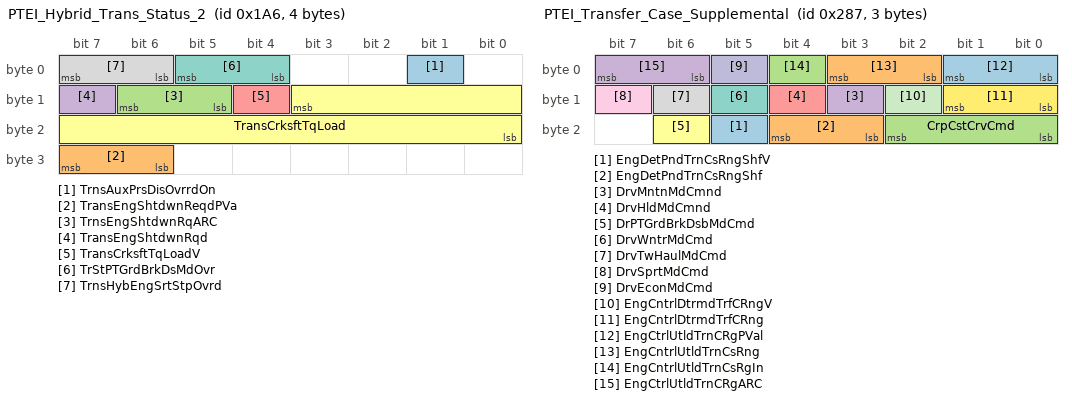
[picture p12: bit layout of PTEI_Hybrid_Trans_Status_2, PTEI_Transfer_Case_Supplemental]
BO_ 422 PTEI_Hybrid_Trans_Status_2: 4 TCM_HS
 SG_ TrnsAuxPrsDisOvrrdOn : 1|1@0+ (1,0) [0|1] ""  HCP_B_HS,ECM_HS
 SG_ TransEngShtdwnReqdPVa : 31|2@0+ (1,0) [0|3] ""  ECM_HS
 SG_ TrnsEngShtdwnRqARC : 14|2@0+ (1,0) [0|3] ""  ECM_HS
 SG_ TransEngShtdwnRqd : 15|1@0+ (1,0) [0|1] ""  ECM_HS
 SG_ TransCrksftTqLoadV : 12|1@0+ (1,0) [0|1] ""  ECM_HS
 SG_ TransCrksftTqLoad : 11|12@0+ (0.5,-848) [-848|1199.5] "Nm"  ECM_HS
 SG_ TrStPTGrdBrkDsMdOvr : 5|2@0+ (1,0) [0|3] ""  ECM_HS
 SG_ TrnsHybEngSrtStpOvrd : 7|2@0+ (1,0) [0|3] ""  HCP_B_HS,ECM_HS,BCP_HS

BO_ 647 PTEI_Transfer_Case_Supplemental: 3 ECM_HS
 SG_ EngDetPndTrnCsRngShfV : 21|1@0+ (1,0) [0|1] ""  TCM_HS
 SG_ EngDetPndTrnCsRngShf : 20|2@0+ (1,0) [0|3] ""  TCM_HS
 SG_ CrpCstCrvCmd : 18|3@0+ (1,0) [0|7] ""  TCM_HS,HCP_T_HS
 SG_ DrvMntnMdCmnd : 11|1@0+ (1,0) [0|1] ""  HCP_T_HS,HCP_HS
 SG_ DrvHldMdCmnd : 12|1@0+ (1,0) [0|1] ""  HCP_T_HS,HCP_HS
 SG_ DrPTGrdBrkDsbMdCmd : 22|1@0+ (1,0) [0|1] ""  HCP_T_HS,TCM_HS,HCP_HS
 SG_ DrvWntrMdCmd : 13|1@0+ (1,0) [0|1] ""  TCM_HS
 SG_ DrvTwHaulMdCmd : 14|1@0+ (1,0) [0|1] ""  HCP_T_HS,HCP_HS,TCM_HS,HCP_B_HS
 SG_ DrvSprtMdCmd : 15|1@0+ (1,0) [0|1] ""  HCP_T_HS,TCM_HS,HCP_HS
 SG_ DrvEconMdCmd : 5|1@0+ (1,0) [0|1] ""  TCM_HS
 SG_ EngCntrlDtrmdTrfCRngV : 10|1@0+ (1,0) [0|1] ""  ICCM_OBD_HS,ICCM_HS,TCM_HS,FICM_HS
 SG_ EngCntrlDtrmdTrfCRng : 9|2@0+ (1,0) [0|3] ""  ICCM_OBD_HS,ICCM_HS,TCM_HS,FICM_HS
 SG_ EngCtrlUtldTrnCRgPVal : 1|2@0+ (1,0) [0|3] ""  HCP_T_HS,EBCM_OBD_HS,EBCM_HS,HCP_HS
 SG_ EngCntrlUtldTrnCsRng : 3|2@0+ (1,0) [0|3] ""  HCP_T_HS,EBCM_OBD_HS,EBCM_HS,BCP_HS,HCP_HS
 SG_ EngCntrlUtldTrnCsRgIn : 4|1@0+ (1,0) [0|1] ""  HCP_T_HS,EBCM_OBD_HS,EBCM_HS,HCP_HS
 SG_ EngCtrlUtldTrnCRgARC : 7|2@0+ (1,0) [0|3] ""  HCP_T_HS,EBCM_OBD_HS,EBCM_HS,HCP_HS

BO_ 368 Environment_Id_Resp_5_HS: 3 ONSTAR_HS
 SG_ EnvIdRspSt5 : 17|2@0+ (1,0) [0|3] ""  BCM_HS
 SG_ EnvIdRsp5 : 7|16@0+ (1,0) [0|65535] ""  BCM_HS

BO_TX_BU_ 565 : EBCM_OBD_HS,EBCM_HS;
BO_TX_BU_ 1029 : FCM_HS,EOCM_F_HS;
BO_TX_BU_ 1028 : FCM_HS,EOCM_F_HS;
BO_TX_BU_ 189 : HCP_T_HS,TCM_HS;
BO_TX_BU_ 1243 : ICCM_OBD_HS,ICCM_HS;
BO_TX_BU_ 530 : CGM_HS,VLBS_HS;
BO_TX_BU_ 1027 : FCM_HS,EOCM_F_HS;
BO_TX_BU_ 1026 : FCM_HS,EOCM_F_HS;
BO_TX_BU_ 1025 : FCM_HS,EOCM_F_HS;
BO_TX_BU_ 1024 : FCM_HS,EOCM_F_HS;
BO_TX_BU_ 508 : EBCM_OBD_HS,EBCM_HS;
BO_TX_BU_ 368 : CGM_HS,VLBS_HS,ONSTAR_HS;
CM_ SG_ 979 BrkBstVac "0 kPA represents the sensor reading atmospheric pressure";
CM_ SG_ 1239 BatSOH "State of Health = the aging state of the Battery";
BA_DEF_ SG_  "VNSigSLHS_VNReq" ENUM  "No","Yes";
BA_DEF_ SG_  "VNSigSLHSSharedDiagnostic" ENUM  "No","Yes";
BA_DEF_ SG_  "SignalType" STRING ;
BA_DEF_ SG_  "PacketOrder" INT 0 65535;
BA_DEF_ SG_  "SignalLongName" STRING ;
BA_DEF_ SG_  "GenSigStartValue" INT 0 65535;
BA_DEF_ SG_  "VNSigAllNodes" ENUM  "No","Yes";
BA_DEF_ SG_  "GenSigDeltaValue" INT 0 0;
BA_DEF_ SG_  "GenSigSendType" ENUM  "not used","not used","not used","not used","not used","not used","not used","NoSigSendType","not used","not used","OnAnyChange","OnChangeIfActive","OnDelta";
BA_DEF_ SG_  "GenSigSendOnInit" ENUM  "Not Initialized","Application","Handler";
BA_DEF_ BO_  "AppGenMsgCycleTime" INT 0 0;
BA_DEF_ BO_  "TpTxIndex" INT 0 99;
BA_DEF_ BO_  "GenMsgILSupport" ENUM  "No","Yes";
BA_DEF_ BO_  "TpApplType" STRING ;
BA_DEF_ BO_  "Prio" INT 0 7;
BA_DEF_ BO_  "MessageSubnet" ENUM  "LS","MS","HS","CE","PE","HV","FO","S1","HE","LE","HE2";
BA_DEF_ BO_  "DiagState" ENUM  "No","Yes";
BA_DEF_ BO_  "GenMsgStartDelayTime" INT 0 100000;
BA_DEF_ BO_  "GenMsgDelayTime" INT 0 100000;
BA_DEF_ BO_  "GenMsgCycleTime" INT 0 100000;
BA_DEF_ BO_  "GenMsgSendType" ENUM  "cyclicX","spontanX","cyclicIfActiveX","spontanWithDelay","cyclicAndSpontanX","cyclicAndSpontanWithDelay","spontanWithRepitition","cyclicIfActiveAndSpontanWD";
BA_DEF_ BO_  "DiagResponse" ENUM  "No","Yes";
BA_DEF_ BO_  "DiagRequest" ENUM  "No","Yes";
BA_DEF_ BO_  "NmMessage" ENUM  "No","Yes";
BA_DEF_REL_ BU_SG_REL_  "GenSigSuprvRespComment" STRING ;
BA_DEF_REL_ BU_SG_REL_  "GenSigVBitResp" ENUM  "No","Yes";
BA_DEF_REL_ BU_SG_REL_  "GenSigVBitRespComment" STRING ;
BA_DEF_REL_ BU_SG_REL_  "GenSigVDAFailComment" STRING ;
BA_DEF_REL_ BU_SG_REL_  "GenSigVDAFailResp" ENUM  "No","Yes";
BA_DEF_REL_ BU_SG_REL_  "GenSigRxStartValue" STRING ;
BA_DEF_REL_ BU_SG_REL_  "GenSigSuprvRespSubValue" INT 0 65535;
BA_DEF_REL_ BU_SG_REL_  "GenSigSuprvResp" ENUM  "None","Notify App","Substitute Default";
BA_DEF_REL_ BU_SG_REL_  "GenSigTimeoutMsg" HEX -2147483648 268435455;
BA_DEF_REL_ BU_SG_REL_  "GenSigTimeoutTime" INT 0 15000;
BA_DEF_DEF_  "VNSigSLHS_VNReq" "No";
BA_DEF_DEF_  "VNSigSLHSSharedDiagnostic" "No";
BA_DEF_DEF_  "SignalType" "";
BA_DEF_DEF_  "PacketOrder" 0;
BA_DEF_DEF_  "SignalLongName" "";
BA_DEF_DEF_  "GenSigStartValue" 0;
BA_DEF_DEF_  "VNSigAllNodes" "No";
BA_DEF_DEF_  "GenSigDeltaValue" 0;
BA_DEF_DEF_  "GenSigSendType" "NoSigSendType";
BA_DEF_DEF_  "GenSigSendOnInit" "Not Initialized";
BA_DEF_DEF_  "AppGenMsgCycleTime" 0;
BA_DEF_DEF_  "TpTxIndex" 0;
BA_DEF_DEF_  "GenMsgILSupport" "Yes";
BA_DEF_DEF_  "TpApplType" "";
BA_DEF_DEF_  "Prio" 4;
BA_DEF_DEF_  "MessageSubnet" "FO";
BA_DEF_DEF_  "DiagState" "No";
BA_DEF_DEF_  "GenMsgStartDelayTime" 0;
BA_DEF_DEF_  "GenMsgDelayTime" 0;
BA_DEF_DEF_  "GenMsgCycleTime" 0;
BA_DEF_DEF_  "GenMsgSendType" "spontanX";
BA_DEF_DEF_  "DiagResponse" "No";
BA_DEF_DEF_  "DiagRequest" "No";
BA_DEF_DEF_  "NmMessage" "No";
BA_DEF_DEF_REL_ "GenSigSuprvRespComment" "";
BA_DEF_DEF_REL_ "GenSigVBitResp" "No";
BA_DEF_DEF_REL_ "GenSigVBitRespComment" "";
BA_DEF_DEF_REL_ "GenSigVDAFailComment" "";
BA_DEF_DEF_REL_ "GenSigVDAFailResp" "No";
BA_DEF_DEF_REL_ "GenSigRxStartValue" "";
BA_DEF_DEF_REL_ "GenSigSuprvRespSubValue" 0;
BA_DEF_DEF_REL_ "GenSigSuprvResp" "None";
BA_DEF_DEF_REL_ "GenSigTimeoutMsg" 0;
BA_DEF_DEF_REL_ "GenSigTimeoutTime" 0;
BA_ "Prio" BO_ 565 0;
BA_ "MessageSubnet" BO_ 565 2;
BA_ "GenMsgCycleTime" BO_ 565 2000;
BA_ "GenMsgSendType" BO_ 565 0;
BA_ "Prio" BO_ 1029 0;
BA_ "MessageSubnet" BO_ 1029 2;
BA_ "GenMsgCycleTime" BO_ 1029 100;
BA_ "GenMsgSendType" BO_ 1029 0;
BA_ "Prio" BO_ 1028 0;
BA_ "MessageSubnet" BO_ 1028 2;
BA_ "GenMsgCycleTime" BO_ 1028 100;
BA_ "GenMsgSendType" BO_ 1028 0;
BA_ "Prio" BO_ 500 0;
BA_ "MessageSubnet" BO_ 500 2;
BA_ "GenMsgCycleTime" BO_ 500 25;
BA_ "GenMsgSendType" BO_ 500 0;
BA_ "Prio" BO_ 1417 0;
BA_ "MessageSubnet" BO_ 1417 2;
BA_ "GenMsgCycleTime" BO_ 1417 500;
BA_ "GenMsgSendType" BO_ 1417 0;
BA_ "Prio" BO_ 407 0;
BA_ "MessageSubnet" BO_ 407 2;
BA_ "GenMsgCycleTime" BO_ 407 25;
BA_ "GenMsgSendType" BO_ 407 0;
BA_ "Prio" BO_ 189 0;
BA_ "MessageSubnet" BO_ 189 2;
BA_ "GenMsgCycleTime" BO_ 189 25;
BA_ "GenMsgSendType" BO_ 189 0;
BA_ "Prio" BO_ 187 0;
BA_ "MessageSubnet" BO_ 187 2;
BA_ "GenMsgCycleTime" BO_ 187 25;
BA_ "GenMsgSendType" BO_ 187 0;
BA_ "Prio" BO_ 185 0;
BA_ "MessageSubnet" BO_ 185 2;
BA_ "GenMsgCycleTime" BO_ 185 25;
BA_ "GenMsgSendType" BO_ 185 0;
BA_ "Prio" BO_ 186 0;
BA_ "MessageSubnet" BO_ 186 2;
BA_ "GenMsgCycleTime" BO_ 186 25;
BA_ "GenMsgSendType" BO_ 186 0;
BA_ "Prio" BO_ 152 0;
BA_ "MessageSubnet" BO_ 152 2;
BA_ "GenMsgCycleTime" BO_ 152 12;
BA_ "GenMsgSendType" BO_ 152 0;
BA_ "Prio" BO_ 151 0;
BA_ "MessageSubnet" BO_ 151 2;
BA_ "GenMsgCycleTime" BO_ 151 12;
BA_ "GenMsgSendType" BO_ 151 0;
BA_ "Prio" BO_ 150 0;
BA_ "MessageSubnet" BO_ 150 2;
BA_ "GenMsgCycleTime" BO_ 150 12;
BA_ "GenMsgSendType" BO_ 150 0;
BA_ "Prio" BO_ 188 0;
BA_ "MessageSubnet" BO_ 188 2;
BA_ "GenMsgCycleTime" BO_ 188 12;
BA_ "GenMsgSendType" BO_ 188 0;
BA_ "Prio" BO_ 170 0;
BA_ "MessageSubnet" BO_ 170 2;
BA_ "GenMsgCycleTime" BO_ 170 12;
BA_ "GenMsgSendType" BO_ 170 0;
BA_ "Prio" BO_ 1221 0;
BA_ "MessageSubnet" BO_ 1221 2;
BA_ "GenMsgStartDelayTime" BO_ 1221 10;
BA_ "GenMsgCycleTime" BO_ 1221 500;
BA_ "GenMsgSendType" BO_ 1221 0;
BA_ "Prio" BO_ 1243 0;
BA_ "MessageSubnet" BO_ 1243 2;
BA_ "GenMsgCycleTime" BO_ 1243 500;
BA_ "GenMsgSendType" BO_ 1243 0;
BA_ "Prio" BO_ 979 0;
BA_ "MessageSubnet" BO_ 979 2;
BA_ "GenMsgCycleTime" BO_ 979 100;
BA_ "GenMsgSendType" BO_ 979 0;
BA_ "Prio" BO_ 546 0;
BA_ "MessageSubnet" BO_ 546 2;
BA_ "GenMsgCycleTime" BO_ 546 100;
BA_ "GenMsgSendType" BO_ 546 0;
BA_ "Prio" BO_ 530 0;
BA_ "MessageSubnet" BO_ 530 2;
BA_ "GenMsgCycleTime" BO_ 530 1000;
BA_ "GenMsgSendType" BO_ 530 0;
BA_ "Prio" BO_ 1239 0;
BA_ "MessageSubnet" BO_ 1239 2;
BA_ "GenMsgStartDelayTime" BO_ 1239 20;
BA_ "GenMsgCycleTime" BO_ 1239 500;
BA_ "GenMsgSendType" BO_ 1239 0;
BA_ "Prio" BO_ 1610 0;
BA_ "MessageSubnet" BO_ 1610 2;
BA_ "DiagResponse" BO_ 1610 1;
BA_ "Prio" BO_ 1027 0;
BA_ "MessageSubnet" BO_ 1027 2;
BA_ "GenMsgCycleTime" BO_ 1027 100;
BA_ "GenMsgSendType" BO_ 1027 0;
BA_ "Prio" BO_ 1026 0;
BA_ "MessageSubnet" BO_ 1026 2;
BA_ "GenMsgCycleTime" BO_ 1026 100;
BA_ "GenMsgSendType" BO_ 1026 0;
BA_ "Prio" BO_ 1025 0;
BA_ "MessageSubnet" BO_ 1025 2;
BA_ "GenMsgCycleTime" BO_ 1025 100;
BA_ "GenMsgSendType" BO_ 1025 0;
BA_ "Prio" BO_ 1024 0;
BA_ "MessageSubnet" BO_ 1024 2;
BA_ "GenMsgCycleTime" BO_ 1024 100;
BA_ "GenMsgSendType" BO_ 1024 0;
BA_ "Prio" BO_ 508 0;
BA_ "MessageSubnet" BO_ 508 2;
BA_ "GenMsgCycleTime" BO_ 508 50;
BA_ "GenMsgSendType" BO_ 508 0;
BA_ "Prio" BO_ 422 0;
BA_ "MessageSubnet" BO_ 422 2;
BA_ "GenMsgCycleTime" BO_ 422 25;
BA_ "GenMsgSendType" BO_ 422 0;
BA_ "Prio" BO_ 647 0;
BA_ "MessageSubnet" BO_ 647 2;
BA_ "GenMsgCycleTime" BO_ 647 25;
BA_ "GenMsgSendType" BO_ 647 0;
BA_ "Prio" BO_ 368 0;
BA_ "MessageSubnet" BO_ 368 2;
BA_ "GenMsgCycleTime" BO_ 368 100;
BA_ "GenMsgSendType" BO_ 368 0;
BA_ "SignalType" SG_ 565 PerfMdMainMenuType "ENM";
BA_ "SignalLongName" SG_ 565 PerfMdMainMenuType "Performance Mode Main Menu Type";
BA_ "VNSigAllNodes" SG_ 565 PerfMdMainMenuType 1;
BA_ "SignalType" SG_ 565 PSPMCA_PsngStPrfMd6Avl "BLN";
BA_ "PacketOrder" SG_ 565 PSPMCA_PsngStPrfMd6Avl 6;
BA_ "SignalLongName" SG_ 565 PSPMCA_PsngStPrfMd6Avl "Passenger Seat Performance Mode Customization Available : Passenger Seat Performance Mode 6 Available";
BA_ "VNSigAllNodes" SG_ 565 PSPMCA_PsngStPrfMd6Avl 1;
BA_ "SignalType" SG_ 565 PSPMCA_PsngStPrfMd5Avl "BLN";
BA_ "PacketOrder" SG_ 565 PSPMCA_PsngStPrfMd5Avl 5;
BA_ "SignalLongName" SG_ 565 PSPMCA_PsngStPrfMd5Avl "Passenger Seat Performance Mode Customization Available : Passenger Seat Performance Mode 5 Available";
BA_ "VNSigAllNodes" SG_ 565 PSPMCA_PsngStPrfMd5Avl 1;
BA_ "SignalType" SG_ 565 PSPMCA_PsngStPrfMd4Avl "BLN";
BA_ "PacketOrder" SG_ 565 PSPMCA_PsngStPrfMd4Avl 4;
BA_ "SignalLongName" SG_ 565 PSPMCA_PsngStPrfMd4Avl "Passenger Seat Performance Mode Customization Available : Passenger Seat Performance Mode 4 Available";
BA_ "VNSigAllNodes" SG_ 565 PSPMCA_PsngStPrfMd4Avl 1;
BA_ "SignalType" SG_ 565 PSPMCA_PsngStPrfMd3Avl "BLN";
BA_ "PacketOrder" SG_ 565 PSPMCA_PsngStPrfMd3Avl 3;
BA_ "SignalLongName" SG_ 565 PSPMCA_PsngStPrfMd3Avl "Passenger Seat Performance Mode Customization Available : Passenger Seat Performance Mode 3 Available";
BA_ "VNSigAllNodes" SG_ 565 PSPMCA_PsngStPrfMd3Avl 1;
BA_ "SignalType" SG_ 565 PSPMCA_PsngStPrfMd2Avl "BLN";
BA_ "PacketOrder" SG_ 565 PSPMCA_PsngStPrfMd2Avl 2;
BA_ "SignalLongName" SG_ 565 PSPMCA_PsngStPrfMd2Avl "Passenger Seat Performance Mode Customization Available : Passenger Seat Performance Mode 2 Available";
BA_ "VNSigAllNodes" SG_ 565 PSPMCA_PsngStPrfMd2Avl 1;
BA_ "SignalType" SG_ 565 PSPMCA_PsngStPrfMd1Avl "BLN";
BA_ "PacketOrder" SG_ 565 PSPMCA_PsngStPrfMd1Avl 1;
BA_ "SignalLongName" SG_ 565 PSPMCA_PsngStPrfMd1Avl "Passenger Seat Performance Mode Customization Available : Passenger Seat Performance Mode 1 Available";
BA_ "VNSigAllNodes" SG_ 565 PSPMCA_PsngStPrfMd1Avl 1;
BA_ "SignalType" SG_ 565 DSPMCA_DrvStyPrfMd7Avl "BLN";
BA_ "PacketOrder" SG_ 565 DSPMCA_DrvStyPrfMd7Avl 7;
BA_ "SignalLongName" SG_ 565 DSPMCA_DrvStyPrfMd7Avl "Driving Style Performance Mode Customization Available : Driving Style Performance Mode 7 Available";
BA_ "VNSigAllNodes" SG_ 565 DSPMCA_DrvStyPrfMd7Avl 1;
BA_ "SignalType" SG_ 565 DSPMCA_DrvStyPrfMd6Avl "BLN";
BA_ "PacketOrder" SG_ 565 DSPMCA_DrvStyPrfMd6Avl 6;
BA_ "SignalLongName" SG_ 565 DSPMCA_DrvStyPrfMd6Avl "Driving Style Performance Mode Customization Available : Driving Style Performance Mode 6 Available";
BA_ "VNSigAllNodes" SG_ 565 DSPMCA_DrvStyPrfMd6Avl 1;
BA_ "SignalType" SG_ 565 DSPMCA_DrvStyPrfMd5Avl "BLN";
BA_ "PacketOrder" SG_ 565 DSPMCA_DrvStyPrfMd5Avl 5;
BA_ "SignalLongName" SG_ 565 DSPMCA_DrvStyPrfMd5Avl "Driving Style Performance Mode Customization Available : Driving Style Performance Mode 5 Available";
BA_ "VNSigAllNodes" SG_ 565 DSPMCA_DrvStyPrfMd5Avl 1;
BA_ "SignalType" SG_ 565 DSPMCA_DrvStyPrfMd4Avl "BLN";
BA_ "PacketOrder" SG_ 565 DSPMCA_DrvStyPrfMd4Avl 4;
BA_ "SignalLongName" SG_ 565 DSPMCA_DrvStyPrfMd4Avl "Driving Style Performance Mode Customization Available : Driving Style Performance Mode 4 Available";
BA_ "VNSigAllNodes" SG_ 565 DSPMCA_DrvStyPrfMd4Avl 1;
BA_ "SignalType" SG_ 565 DSPMCA_DrvStyPrfMd3Avl "BLN";
BA_ "PacketOrder" SG_ 565 DSPMCA_DrvStyPrfMd3Avl 3;
BA_ "SignalLongName" SG_ 565 DSPMCA_DrvStyPrfMd3Avl "Driving Style Performance Mode Customization Available : Driving Style Performance Mode 3 Available";
BA_ "VNSigAllNodes" SG_ 565 DSPMCA_DrvStyPrfMd3Avl 1;
BA_ "SignalType" SG_ 565 DSPMCA_DrvStyPrfMd2Avl "BLN";
BA_ "PacketOrder" SG_ 565 DSPMCA_DrvStyPrfMd2Avl 2;
BA_ "SignalLongName" SG_ 565 DSPMCA_DrvStyPrfMd2Avl "Driving Style Performance Mode Customization Available : Driving Style Performance Mode 2 Available";
BA_ "VNSigAllNodes" SG_ 565 DSPMCA_DrvStyPrfMd2Avl 1;
BA_ "SignalType" SG_ 565 DSPMCA_DrvStyPrfMd1Avl "BLN";
BA_ "PacketOrder" SG_ 565 DSPMCA_DrvStyPrfMd1Avl 1;
BA_ "SignalLongName" SG_ 565 DSPMCA_DrvStyPrfMd1Avl "Driving Style Performance Mode Customization Available : Driving Style Performance Mode 1 Available";
BA_ "VNSigAllNodes" SG_ 565 DSPMCA_DrvStyPrfMd1Avl 1;
BA_ "SignalType" SG_ 565 DSPMCA_DrvrStPrfMd6Avl "BLN";
BA_ "PacketOrder" SG_ 565 DSPMCA_DrvrStPrfMd6Avl 6;
BA_ "SignalLongName" SG_ 565 DSPMCA_DrvrStPrfMd6Avl "Driver Seat Performance Mode Customization Available : Driver Seat Performance Mode 6 Available";
BA_ "VNSigAllNodes" SG_ 565 DSPMCA_DrvrStPrfMd6Avl 1;
BA_ "SignalType" SG_ 565 DSPMCA_DrvrStPrfMd5Avl "BLN";
BA_ "PacketOrder" SG_ 565 DSPMCA_DrvrStPrfMd5Avl 5;
BA_ "SignalLongName" SG_ 565 DSPMCA_DrvrStPrfMd5Avl "Driver Seat Performance Mode Customization Available : Driver Seat Performance Mode 5 Available";
BA_ "VNSigAllNodes" SG_ 565 DSPMCA_DrvrStPrfMd5Avl 1;
BA_ "SignalType" SG_ 565 DSPMCA_DrvrStPrfMd4Avl "BLN";
BA_ "PacketOrder" SG_ 565 DSPMCA_DrvrStPrfMd4Avl 4;
BA_ "SignalLongName" SG_ 565 DSPMCA_DrvrStPrfMd4Avl "Driver Seat Performance Mode Customization Available : Driver Seat Performance Mode 4 Available";
BA_ "VNSigAllNodes" SG_ 565 DSPMCA_DrvrStPrfMd4Avl 1;
BA_ "SignalType" SG_ 565 DSPMCA_DrvrStPrfMd3Avl "BLN";
BA_ "PacketOrder" SG_ 565 DSPMCA_DrvrStPrfMd3Avl 3;
BA_ "SignalLongName" SG_ 565 DSPMCA_DrvrStPrfMd3Avl "Driver Seat Performance Mode Customization Available : Driver Seat Performance Mode 3 Available";
BA_ "VNSigAllNodes" SG_ 565 DSPMCA_DrvrStPrfMd3Avl 1;
BA_ "SignalType" SG_ 565 DSPMCA_DrvrStPrfMd2Avl "BLN";
BA_ "PacketOrder" SG_ 565 DSPMCA_DrvrStPrfMd2Avl 2;
BA_ "SignalLongName" SG_ 565 DSPMCA_DrvrStPrfMd2Avl "Driver Seat Performance Mode Customization Available : Driver Seat Performance Mode 2 Available";
BA_ "VNSigAllNodes" SG_ 565 DSPMCA_DrvrStPrfMd2Avl 1;
BA_ "SignalType" SG_ 565 DSPMCA_DrvrStPrfMd1Avl "BLN";
BA_ "PacketOrder" SG_ 565 DSPMCA_DrvrStPrfMd1Avl 1;
BA_ "SignalLongName" SG_ 565 DSPMCA_DrvrStPrfMd1Avl "Driver Seat Performance Mode Customization Available : Driver Seat Performance Mode 1 Available";
BA_ "VNSigAllNodes" SG_ 565 DSPMCA_DrvrStPrfMd1Avl 1;
BA_ "SignalType" SG_ 565 ACCPMCA_ACCPrfMd6Avl "BLN";
BA_ "PacketOrder" SG_ 565 ACCPMCA_ACCPrfMd6Avl 6;
BA_ "SignalLongName" SG_ 565 ACCPMCA_ACCPrfMd6Avl "Adaptive Cruise Control Performance Mode Customization Available : Adaptive Cruise Control Performance Mode 6 Available";
BA_ "VNSigAllNodes" SG_ 565 ACCPMCA_ACCPrfMd6Avl 1;
BA_ "SignalType" SG_ 565 ACCPMCA_ACCPrfMd5Avl "BLN";
BA_ "PacketOrder" SG_ 565 ACCPMCA_ACCPrfMd5Avl 5;
BA_ "SignalLongName" SG_ 565 ACCPMCA_ACCPrfMd5Avl "Adaptive Cruise Control Performance Mode Customization Available : Adaptive Cruise Control Performance Mode 5 Available";
BA_ "VNSigAllNodes" SG_ 565 ACCPMCA_ACCPrfMd5Avl 1;
BA_ "SignalType" SG_ 565 ACCPMCA_ACCPrfMd4Avl "BLN";
BA_ "PacketOrder" SG_ 565 ACCPMCA_ACCPrfMd4Avl 4;
BA_ "SignalLongName" SG_ 565 ACCPMCA_ACCPrfMd4Avl "Adaptive Cruise Control Performance Mode Customization Available : Adaptive Cruise Control Performance Mode 4 Available";
BA_ "VNSigAllNodes" SG_ 565 ACCPMCA_ACCPrfMd4Avl 1;
BA_ "SignalType" SG_ 565 ACCPMCA_ACCPrfMd3Avl "BLN";
BA_ "PacketOrder" SG_ 565 ACCPMCA_ACCPrfMd3Avl 3;
BA_ "SignalLongName" SG_ 565 ACCPMCA_ACCPrfMd3Avl "Adaptive Cruise Control Performance Mode Customization Available : Adaptive Cruise Control Performance Mode 3 Available";
BA_ "VNSigAllNodes" SG_ 565 ACCPMCA_ACCPrfMd3Avl 1;
BA_ "SignalType" SG_ 565 ACCPMCA_ACCPrfMd2Avl "BLN";
BA_ "PacketOrder" SG_ 565 ACCPMCA_ACCPrfMd2Avl 2;
BA_ "SignalLongName" SG_ 565 ACCPMCA_ACCPrfMd2Avl "Adaptive Cruise Control Performance Mode Customization Available : Adaptive Cruise Control Performance Mode 2 Available";
BA_ "VNSigAllNodes" SG_ 565 ACCPMCA_ACCPrfMd2Avl 1;
BA_ "SignalType" SG_ 565 ACCPMCA_ACCPrfMd1Avl "BLN";
BA_ "PacketOrder" SG_ 565 ACCPMCA_ACCPrfMd1Avl 1;
BA_ "SignalLongName" SG_ 565 ACCPMCA_ACCPrfMd1Avl "Adaptive Cruise Control Performance Mode Customization Available : Adaptive Cruise Control Performance Mode 1 Available";
BA_ "VNSigAllNodes" SG_ 565 ACCPMCA_ACCPrfMd1Avl 1;
BA_ "SignalType" SG_ 1029 GFHBFwVsnWidthTrk6 "UNM";
BA_ "SignalLongName" SG_ 1029 GFHBFwVsnWidthTrk6 "GFHB Forward Vision Width Track 6";
BA_ "VNSigAllNodes" SG_ 1029 GFHBFwVsnWidthTrk6 1;
BA_ "SignalType" SG_ 1029 GFHBFwVsnVertPosTrk6 "UNM";
BA_ "SignalLongName" SG_ 1029 GFHBFwVsnVertPosTrk6 "GFHB Forward Vision Vertical Position Track 6";
BA_ "VNSigAllNodes" SG_ 1029 GFHBFwVsnVertPosTrk6 1;
BA_ "SignalType" SG_ 1029 GFHBFwVsnRelLaneTrk6 "ENM";
BA_ "SignalLongName" SG_ 1029 GFHBFwVsnRelLaneTrk6 "GFHB Forward Vision Relative Lane Track 6";
BA_ "VNSigAllNodes" SG_ 1029 GFHBFwVsnRelLaneTrk6 1;
BA_ "SignalType" SG_ 1029 GFHBFwVsnAzmthRtTrk6 "SNM";
BA_ "SignalLongName" SG_ 1029 GFHBFwVsnAzmthRtTrk6 "GFHB Forward Vision Azimuth Rate Track 6";
BA_ "VNSigAllNodes" SG_ 1029 GFHBFwVsnAzmthRtTrk6 1;
BA_ "SignalType" SG_ 1029 GFHBFwVsnCnfdncTrk6 "ENM";
BA_ "SignalLongName" SG_ 1029 GFHBFwVsnCnfdncTrk6 "GFHB Forward Vision Confidence Track 6";
BA_ "VNSigAllNodes" SG_ 1029 GFHBFwVsnCnfdncTrk6 1;
BA_ "SignalType" SG_ 1029 GFHBFwVsnRngTrkRev6 "UNM";
BA_ "SignalLongName" SG_ 1029 GFHBFwVsnRngTrkRev6 "GFHB Forward Vision Range Track Revised 6";
BA_ "VNSigAllNodes" SG_ 1029 GFHBFwVsnRngTrkRev6 1;
BA_ "SignalType" SG_ 1029 GFHBFwVsnAzmthTrkRev6 "SNM";
BA_ "SignalLongName" SG_ 1029 GFHBFwVsnAzmthTrkRev6 "GFHB Forward Vision Azimuth Track Revised 6";
BA_ "VNSigAllNodes" SG_ 1029 GFHBFwVsnAzmthTrkRev6 1;
BA_ "SignalType" SG_ 1029 GFHBFVsnObjTypTrkRev6 "ENM";
BA_ "SignalLongName" SG_ 1029 GFHBFVsnObjTypTrkRev6 "GFHB Forward Vision Object Type Track Revised 6";
BA_ "VNSigAllNodes" SG_ 1029 GFHBFVsnObjTypTrkRev6 1;
BA_ "SignalType" SG_ 1029 GFHBObjDirTrk6 "ENM";
BA_ "SignalLongName" SG_ 1029 GFHBObjDirTrk6 "GFHB Object Direction Track 6";
BA_ "VNSigAllNodes" SG_ 1029 GFHBObjDirTrk6 1;
BA_ "SignalType" SG_ 1029 GFHBFwVsnMesStatTrk6 "ENM";
BA_ "SignalLongName" SG_ 1029 GFHBFwVsnMesStatTrk6 "GFHB Forward Vision Measurement Status Track 6";
BA_ "VNSigAllNodes" SG_ 1029 GFHBFwVsnMesStatTrk6 1;
BA_ "SignalType" SG_ 1029 GFHBFwVsnObjIDTrk6 "UNM";
BA_ "SignalLongName" SG_ 1029 GFHBFwVsnObjIDTrk6 "GFHB Forward Vision Object ID Track 6";
BA_ "VNSigAllNodes" SG_ 1029 GFHBFwVsnObjIDTrk6 1;
BA_ "SignalType" SG_ 1028 GFHBFwVsnWidthTrk5 "UNM";
BA_ "SignalLongName" SG_ 1028 GFHBFwVsnWidthTrk5 "GFHB Forward Vision Width Track 5";
BA_ "VNSigAllNodes" SG_ 1028 GFHBFwVsnWidthTrk5 1;
BA_ "SignalType" SG_ 1028 GFHBFwVsnVertPosTrk5 "UNM";
BA_ "SignalLongName" SG_ 1028 GFHBFwVsnVertPosTrk5 "GFHB Forward Vision Vertical Position Track 5";
BA_ "VNSigAllNodes" SG_ 1028 GFHBFwVsnVertPosTrk5 1;
BA_ "SignalType" SG_ 1028 GFHBFwVsnRelLaneTrk5 "ENM";
BA_ "SignalLongName" SG_ 1028 GFHBFwVsnRelLaneTrk5 "GFHB Forward Vision Relative Lane Track 5";
BA_ "VNSigAllNodes" SG_ 1028 GFHBFwVsnRelLaneTrk5 1;
BA_ "SignalType" SG_ 1028 GFHBFwVsnAzmthRtTrk5 "SNM";
BA_ "SignalLongName" SG_ 1028 GFHBFwVsnAzmthRtTrk5 "GFHB Forward Vision Azimuth Rate Track 5";
BA_ "VNSigAllNodes" SG_ 1028 GFHBFwVsnAzmthRtTrk5 1;
BA_ "SignalType" SG_ 1028 GFHBFwVsnCnfdncTrk5 "ENM";
BA_ "SignalLongName" SG_ 1028 GFHBFwVsnCnfdncTrk5 "GFHB Forward Vision Confidence Track 5";
BA_ "VNSigAllNodes" SG_ 1028 GFHBFwVsnCnfdncTrk5 1;
BA_ "SignalType" SG_ 1028 GFHBFwVsnRngTrkRev5 "UNM";
BA_ "SignalLongName" SG_ 1028 GFHBFwVsnRngTrkRev5 "GFHB Forward Vision Range Track Revised 5";
BA_ "VNSigAllNodes" SG_ 1028 GFHBFwVsnRngTrkRev5 1;
BA_ "SignalType" SG_ 1028 GFHBFwVsnAzmthTrkRev5 "SNM";
BA_ "SignalLongName" SG_ 1028 GFHBFwVsnAzmthTrkRev5 "GFHB Forward Vision Azimuth Track Revised 5";
BA_ "VNSigAllNodes" SG_ 1028 GFHBFwVsnAzmthTrkRev5 1;
BA_ "SignalType" SG_ 1028 GFHBFVsnObjTypTrkRev5 "ENM";
BA_ "SignalLongName" SG_ 1028 GFHBFVsnObjTypTrkRev5 "GFHB Forward Vision Object Type Track Revised 5";
BA_ "VNSigAllNodes" SG_ 1028 GFHBFVsnObjTypTrkRev5 1;
BA_ "SignalType" SG_ 1028 GFHBObjDirTrk5 "ENM";
BA_ "SignalLongName" SG_ 1028 GFHBObjDirTrk5 "GFHB Object Direction Track 5";
BA_ "VNSigAllNodes" SG_ 1028 GFHBObjDirTrk5 1;
BA_ "SignalType" SG_ 1028 GFHBFwVsnMesStatTrk5 "ENM";
BA_ "SignalLongName" SG_ 1028 GFHBFwVsnMesStatTrk5 "GFHB Forward Vision Measurement Status Track 5";
BA_ "VNSigAllNodes" SG_ 1028 GFHBFwVsnMesStatTrk5 1;
BA_ "SignalType" SG_ 1028 GFHBFwVsnObjIDTrk5 "UNM";
BA_ "SignalLongName" SG_ 1028 GFHBFwVsnObjIDTrk5 "GFHB Forward Vision Object ID Track 5";
BA_ "VNSigAllNodes" SG_ 1028 GFHBFwVsnObjIDTrk5 1;
BA_ "SignalType" SG_ 500 EnhDrvMdSwChUseAct "BLN";
BA_ "SignalLongName" SG_ 500 EnhDrvMdSwChUseAct "Enhanced Driver Selected Mode Switch Chassis Use Active";
BA_ "VNSigAllNodes" SG_ 500 EnhDrvMdSwChUseAct 1;
BA_ "SignalType" SG_ 500 EnhDrvSelMdSwStat "ENM";
BA_ "SignalLongName" SG_ 500 EnhDrvSelMdSwStat "Enhanced Driver Selected Mode Switch Status";
BA_ "VNSigAllNodes" SG_ 500 EnhDrvSelMdSwStat 1;
BA_ "GenSigSendType" SG_ 500 DrvSelMd8Stat 10;
BA_ "SignalType" SG_ 500 DrvSelMd8Stat "ENM";
BA_ "SignalLongName" SG_ 500 DrvSelMd8Stat "Driver Selected Mode 8 Status";
BA_ "VNSigAllNodes" SG_ 500 DrvSelMd8Stat 1;
BA_ "GenSigSendType" SG_ 500 DrvSelMd8ReqDnd 10;
BA_ "SignalType" SG_ 500 DrvSelMd8ReqDnd "BLN";
BA_ "SignalLongName" SG_ 500 DrvSelMd8ReqDnd "Driver Selected Mode 8 Request Denied";
BA_ "VNSigAllNodes" SG_ 500 DrvSelMd8ReqDnd 1;
BA_ "GenSigSendType" SG_ 500 DrvSelMd7Stat 10;
BA_ "SignalType" SG_ 500 DrvSelMd7Stat "ENM";
BA_ "SignalLongName" SG_ 500 DrvSelMd7Stat "Driver Selected Mode 7 Status";
BA_ "VNSigAllNodes" SG_ 500 DrvSelMd7Stat 1;
BA_ "GenSigSendType" SG_ 500 DrvSelMd7ReqDnd 10;
BA_ "SignalType" SG_ 500 DrvSelMd7ReqDnd "BLN";
BA_ "SignalLongName" SG_ 500 DrvSelMd7ReqDnd "Driver Selected Mode 7 Request Denied";
BA_ "VNSigAllNodes" SG_ 500 DrvSelMd7ReqDnd 1;
BA_ "GenSigSendType" SG_ 500 DrvSelMd6Stat 10;
BA_ "SignalType" SG_ 500 DrvSelMd6Stat "ENM";
BA_ "SignalLongName" SG_ 500 DrvSelMd6Stat "Driver Selected Mode 6 Status";
BA_ "VNSigAllNodes" SG_ 500 DrvSelMd6Stat 1;
BA_ "GenSigSendType" SG_ 500 DrvSelMd6ReqDnd 10;
BA_ "SignalType" SG_ 500 DrvSelMd6ReqDnd "BLN";
BA_ "SignalLongName" SG_ 500 DrvSelMd6ReqDnd "Driver Selected Mode 6 Request Denied";
BA_ "VNSigAllNodes" SG_ 500 DrvSelMd6ReqDnd 1;
BA_ "GenSigSendType" SG_ 500 DrvSelMd5Stat 10;
BA_ "SignalType" SG_ 500 DrvSelMd5Stat "ENM";
BA_ "SignalLongName" SG_ 500 DrvSelMd5Stat "Driver Selected Mode 5 Status";
BA_ "VNSigAllNodes" SG_ 500 DrvSelMd5Stat 1;
BA_ "GenSigSendType" SG_ 500 DrvSelMd5ReqDnd 10;
BA_ "SignalType" SG_ 500 DrvSelMd5ReqDnd "BLN";
BA_ "SignalLongName" SG_ 500 DrvSelMd5ReqDnd "Driver Selected Mode 5 Request Denied";
BA_ "VNSigAllNodes" SG_ 500 DrvSelMd5ReqDnd 1;
BA_ "GenSigSendType" SG_ 500 DrvSelMd4Stat 10;
BA_ "SignalType" SG_ 500 DrvSelMd4Stat "ENM";
BA_ "SignalLongName" SG_ 500 DrvSelMd4Stat "Driver Selected Mode 4 Status";
BA_ "VNSigAllNodes" SG_ 500 DrvSelMd4Stat 1;
BA_ "GenSigSendType" SG_ 500 DrvSelMd4ReqDnd 10;
BA_ "SignalType" SG_ 500 DrvSelMd4ReqDnd "BLN";
BA_ "SignalLongName" SG_ 500 DrvSelMd4ReqDnd "Driver Selected Mode 4 Request Denied";
BA_ "VNSigAllNodes" SG_ 500 DrvSelMd4ReqDnd 1;
BA_ "GenSigSendType" SG_ 500 DrvSelMd3Stat 10;
BA_ "SignalType" SG_ 500 DrvSelMd3Stat "ENM";
BA_ "SignalLongName" SG_ 500 DrvSelMd3Stat "Driver Selected Mode 3 Status";
BA_ "VNSigAllNodes" SG_ 500 DrvSelMd3Stat 1;
BA_ "GenSigSendType" SG_ 500 DrvSelMd3ReqDnd 10;
BA_ "SignalType" SG_ 500 DrvSelMd3ReqDnd "BLN";
BA_ "SignalLongName" SG_ 500 DrvSelMd3ReqDnd "Driver Selected Mode 3 Request Denied";
BA_ "VNSigAllNodes" SG_ 500 DrvSelMd3ReqDnd 1;
BA_ "GenSigSendType" SG_ 500 DrvSelMd2Stat 10;
BA_ "SignalType" SG_ 500 DrvSelMd2Stat "ENM";
BA_ "SignalLongName" SG_ 500 DrvSelMd2Stat "Driver Selected Mode 2 Status";
BA_ "VNSigAllNodes" SG_ 500 DrvSelMd2Stat 1;
BA_ "GenSigSendType" SG_ 500 DrvSelMd2ReqDnd 10;
BA_ "SignalType" SG_ 500 DrvSelMd2ReqDnd "BLN";
BA_ "SignalLongName" SG_ 500 DrvSelMd2ReqDnd "Driver Selected Mode 2 Request Denied";
BA_ "VNSigAllNodes" SG_ 500 DrvSelMd2ReqDnd 1;
BA_ "GenSigSendType" SG_ 500 DSMSS_DrvSelMd0Pn 10;
BA_ "SignalType" SG_ 500 DSMSS_DrvSelMd0Pn "BLN";
BA_ "PacketOrder" SG_ 500 DSMSS_DrvSelMd0Pn 17;
BA_ "SignalLongName" SG_ 500 DSMSS_DrvSelMd0Pn "Driver Selected Mode Selection Status : Driver Selected Mode 0 Pending";
BA_ "VNSigAllNodes" SG_ 500 DSMSS_DrvSelMd0Pn 1;
BA_ "GenSigSendType" SG_ 500 DSMSS_DrvSelMd8Pn 10;
BA_ "SignalType" SG_ 500 DSMSS_DrvSelMd8Pn "BLN";
BA_ "PacketOrder" SG_ 500 DSMSS_DrvSelMd8Pn 16;
BA_ "SignalLongName" SG_ 500 DSMSS_DrvSelMd8Pn "Driver Selected Mode Selection Status : Driver Selected Mode 8 Pending";
BA_ "VNSigAllNodes" SG_ 500 DSMSS_DrvSelMd8Pn 1;
BA_ "GenSigSendType" SG_ 500 DSMSS_DrvSelMd7Pn 10;
BA_ "SignalType" SG_ 500 DSMSS_DrvSelMd7Pn "BLN";
BA_ "PacketOrder" SG_ 500 DSMSS_DrvSelMd7Pn 15;
BA_ "SignalLongName" SG_ 500 DSMSS_DrvSelMd7Pn "Driver Selected Mode Selection Status : Driver Selected Mode 7 Pending";
BA_ "VNSigAllNodes" SG_ 500 DSMSS_DrvSelMd7Pn 1;
BA_ "GenSigSendType" SG_ 500 DSMSS_DrvSelMd6Pn 10;
BA_ "SignalType" SG_ 500 DSMSS_DrvSelMd6Pn "BLN";
BA_ "PacketOrder" SG_ 500 DSMSS_DrvSelMd6Pn 14;
BA_ "SignalLongName" SG_ 500 DSMSS_DrvSelMd6Pn "Driver Selected Mode Selection Status : Driver Selected Mode 6 Pending";
BA_ "VNSigAllNodes" SG_ 500 DSMSS_DrvSelMd6Pn 1;
BA_ "GenSigSendType" SG_ 500 DSMSS_DrvSelMd5Pn 10;
BA_ "SignalType" SG_ 500 DSMSS_DrvSelMd5Pn "BLN";
BA_ "PacketOrder" SG_ 500 DSMSS_DrvSelMd5Pn 13;
BA_ "SignalLongName" SG_ 500 DSMSS_DrvSelMd5Pn "Driver Selected Mode Selection Status : Driver Selected Mode 5 Pending";
BA_ "VNSigAllNodes" SG_ 500 DSMSS_DrvSelMd5Pn 1;
BA_ "GenSigSendType" SG_ 500 DSMSS_DrvSelMd4Pn 10;
BA_ "SignalType" SG_ 500 DSMSS_DrvSelMd4Pn "BLN";
BA_ "PacketOrder" SG_ 500 DSMSS_DrvSelMd4Pn 12;
BA_ "SignalLongName" SG_ 500 DSMSS_DrvSelMd4Pn "Driver Selected Mode Selection Status : Driver Selected Mode 4 Pending";
BA_ "VNSigAllNodes" SG_ 500 DSMSS_DrvSelMd4Pn 1;
BA_ "GenSigSendType" SG_ 500 DSMSS_DrvSelMd3Pn 10;
BA_ "SignalType" SG_ 500 DSMSS_DrvSelMd3Pn "BLN";
BA_ "PacketOrder" SG_ 500 DSMSS_DrvSelMd3Pn 11;
BA_ "SignalLongName" SG_ 500 DSMSS_DrvSelMd3Pn "Driver Selected Mode Selection Status : Driver Selected Mode 3 Pending";
BA_ "VNSigAllNodes" SG_ 500 DSMSS_DrvSelMd3Pn 1;
BA_ "GenSigSendType" SG_ 500 DSMSS_DrvSelMd2Pn 10;
BA_ "SignalType" SG_ 500 DSMSS_DrvSelMd2Pn "BLN";
BA_ "PacketOrder" SG_ 500 DSMSS_DrvSelMd2Pn 10;
BA_ "SignalLongName" SG_ 500 DSMSS_DrvSelMd2Pn "Driver Selected Mode Selection Status : Driver Selected Mode 2 Pending";
BA_ "VNSigAllNodes" SG_ 500 DSMSS_DrvSelMd2Pn 1;
BA_ "GenSigSendType" SG_ 500 DSMSS_DrvSelMd1Pn 10;
BA_ "SignalType" SG_ 500 DSMSS_DrvSelMd1Pn "BLN";
BA_ "PacketOrder" SG_ 500 DSMSS_DrvSelMd1Pn 9;
BA_ "SignalLongName" SG_ 500 DSMSS_DrvSelMd1Pn "Driver Selected Mode Selection Status : Driver Selected Mode 1 Pending";
BA_ "VNSigAllNodes" SG_ 500 DSMSS_DrvSelMd1Pn 1;
BA_ "GenSigSendType" SG_ 500 DSMSS_DrvSelMd8Un 10;
BA_ "SignalType" SG_ 500 DSMSS_DrvSelMd8Un "BLN";
BA_ "PacketOrder" SG_ 500 DSMSS_DrvSelMd8Un 8;
BA_ "SignalLongName" SG_ 500 DSMSS_DrvSelMd8Un "Driver Selected Mode Selection Status : Driver Selected Mode 8 Unavailable";
BA_ "VNSigAllNodes" SG_ 500 DSMSS_DrvSelMd8Un 1;
BA_ "GenSigSendType" SG_ 500 DSMSS_DrvSelMd7Un 10;
BA_ "SignalType" SG_ 500 DSMSS_DrvSelMd7Un "BLN";
BA_ "PacketOrder" SG_ 500 DSMSS_DrvSelMd7Un 7;
BA_ "SignalLongName" SG_ 500 DSMSS_DrvSelMd7Un "Driver Selected Mode Selection Status : Driver Selected Mode 7 Unavailable";
BA_ "VNSigAllNodes" SG_ 500 DSMSS_DrvSelMd7Un 1;
BA_ "GenSigSendType" SG_ 500 DSMSS_DrvSelMd6Un 10;
BA_ "SignalType" SG_ 500 DSMSS_DrvSelMd6Un "BLN";
BA_ "PacketOrder" SG_ 500 DSMSS_DrvSelMd6Un 6;
BA_ "SignalLongName" SG_ 500 DSMSS_DrvSelMd6Un "Driver Selected Mode Selection Status : Driver Selected Mode 6 Unavailable";
BA_ "VNSigAllNodes" SG_ 500 DSMSS_DrvSelMd6Un 1;
BA_ "GenSigSendType" SG_ 500 DSMSS_DrvSelMd5Un 10;
BA_ "SignalType" SG_ 500 DSMSS_DrvSelMd5Un "BLN";
BA_ "PacketOrder" SG_ 500 DSMSS_DrvSelMd5Un 5;
BA_ "SignalLongName" SG_ 500 DSMSS_DrvSelMd5Un "Driver Selected Mode Selection Status : Driver Selected Mode 5 Unavailable";
BA_ "VNSigAllNodes" SG_ 500 DSMSS_DrvSelMd5Un 1;
BA_ "GenSigSendType" SG_ 500 DSMSS_DrvSelMd4Un 10;
BA_ "SignalType" SG_ 500 DSMSS_DrvSelMd4Un "BLN";
BA_ "PacketOrder" SG_ 500 DSMSS_DrvSelMd4Un 4;
BA_ "SignalLongName" SG_ 500 DSMSS_DrvSelMd4Un "Driver Selected Mode Selection Status : Driver Selected Mode 4 Unavailable";
BA_ "VNSigAllNodes" SG_ 500 DSMSS_DrvSelMd4Un 1;
BA_ "GenSigSendType" SG_ 500 DSMSS_DrvSelMd3Un 10;
BA_ "SignalType" SG_ 500 DSMSS_DrvSelMd3Un "BLN";
BA_ "PacketOrder" SG_ 500 DSMSS_DrvSelMd3Un 3;
BA_ "SignalLongName" SG_ 500 DSMSS_DrvSelMd3Un "Driver Selected Mode Selection Status : Driver Selected Mode 3 Unavailable";
BA_ "VNSigAllNodes" SG_ 500 DSMSS_DrvSelMd3Un 1;
BA_ "GenSigSendType" SG_ 500 DSMSS_DrvSelMd2Un 10;
BA_ "SignalType" SG_ 500 DSMSS_DrvSelMd2Un "BLN";
BA_ "PacketOrder" SG_ 500 DSMSS_DrvSelMd2Un 2;
BA_ "SignalLongName" SG_ 500 DSMSS_DrvSelMd2Un "Driver Selected Mode Selection Status : Driver Selected Mode 2 Unavailable";
BA_ "VNSigAllNodes" SG_ 500 DSMSS_DrvSelMd2Un 1;
BA_ "GenSigSendType" SG_ 500 DSMSS_DrvSelMd1Un 10;
BA_ "SignalType" SG_ 500 DSMSS_DrvSelMd1Un "BLN";
BA_ "PacketOrder" SG_ 500 DSMSS_DrvSelMd1Un 1;
BA_ "SignalLongName" SG_ 500 DSMSS_DrvSelMd1Un "Driver Selected Mode Selection Status : Driver Selected Mode 1 Unavailable";
BA_ "VNSigAllNodes" SG_ 500 DSMSS_DrvSelMd1Un 1;
BA_ "GenSigSendType" SG_ 500 DrvSelMd1ReqDnd 10;
BA_ "SignalType" SG_ 500 DrvSelMd1ReqDnd "BLN";
BA_ "SignalLongName" SG_ 500 DrvSelMd1ReqDnd "Driver Selected Mode 1 Request Denied";
BA_ "VNSigAllNodes" SG_ 500 DrvSelMd1ReqDnd 1;
BA_ "GenSigSendType" SG_ 500 DrvSelMd1Stat 10;
BA_ "SignalType" SG_ 500 DrvSelMd1Stat "ENM";
BA_ "SignalLongName" SG_ 500 DrvSelMd1Stat "Driver Selected Mode 1 Status";
BA_ "VNSigAllNodes" SG_ 500 DrvSelMd1Stat 1;
BA_ "SignalType" SG_ 1417 PrplsnTrqRelCap "UNM";
BA_ "SignalLongName" SG_ 1417 PrplsnTrqRelCap "Propulsion Torque Relative Capability";
BA_ "VNSigAllNodes" SG_ 1417 PrplsnTrqRelCap 1;
BA_ "SignalType" SG_ 1417 ETC_MinTorq "UNM";
BA_ "PacketOrder" SG_ 1417 ETC_MinTorq 7;
BA_ "SignalLongName" SG_ 1417 ETC_MinTorq "Engine Torque Capability : Minimum Torque";
BA_ "VNSigAllNodes" SG_ 1417 ETC_MinTorq 1;
BA_ "SignalType" SG_ 1417 ETC_MinRunTorq "UNM";
BA_ "PacketOrder" SG_ 1417 ETC_MinRunTorq 6;
BA_ "SignalLongName" SG_ 1417 ETC_MinRunTorq "Engine Torque Capability : Minimum Run Torque";
BA_ "VNSigAllNodes" SG_ 1417 ETC_MinRunTorq 1;
BA_ "SignalType" SG_ 1417 ETC_MaxTorq "UNM";
BA_ "PacketOrder" SG_ 1417 ETC_MaxTorq 5;
BA_ "SignalLongName" SG_ 1417 ETC_MaxTorq "Engine Torque Capability : Maximum Torque";
BA_ "VNSigAllNodes" SG_ 1417 ETC_MaxTorq 1;
BA_ "SignalType" SG_ 1417 ETC_RefEngSpd "UNM";
BA_ "PacketOrder" SG_ 1417 ETC_RefEngSpd 4;
BA_ "SignalLongName" SG_ 1417 ETC_RefEngSpd "Engine Torque Capability : Reference Engine Speed";
BA_ "VNSigAllNodes" SG_ 1417 ETC_RefEngSpd 1;
BA_ "SignalType" SG_ 1417 ETC_UnsdRsrvd "UNM";
BA_ "PacketOrder" SG_ 1417 ETC_UnsdRsrvd 3;
BA_ "SignalLongName" SG_ 1417 ETC_UnsdRsrvd "Engine Torque Capability : Unused and Reserved";
BA_ "VNSigAllNodes" SG_ 1417 ETC_UnsdRsrvd 1;
BA_ "SignalType" SG_ 1417 ETC_FrmCntr "UNM";
BA_ "PacketOrder" SG_ 1417 ETC_FrmCntr 2;
BA_ "SignalLongName" SG_ 1417 ETC_FrmCntr "Engine Torque Capability : Frame Counter";
BA_ "VNSigAllNodes" SG_ 1417 ETC_FrmCntr 1;
BA_ "SignalType" SG_ 1417 ETC_EngOpMd "ENM";
BA_ "PacketOrder" SG_ 1417 ETC_EngOpMd 1;
BA_ "SignalLongName" SG_ 1417 ETC_EngOpMd "Engine Torque Capability : Engine Operating Mode";
BA_ "VNSigAllNodes" SG_ 1417 ETC_EngOpMd 1;
BA_ "SignalType" SG_ 407 TrnsEgdPrFlwInfPVal "UNM";
BA_ "SignalLongName" SG_ 407 TrnsEgdPrFlwInfPVal "Transmission Engaged Powerflow Information Protection Value";
BA_ "VNSigAllNodes" SG_ 407 TrnsEgdPrFlwInfPVal 1;
BA_ "SignalType" SG_ 407 TrnsEgdPrFlwInfARC "UNM";
BA_ "SignalLongName" SG_ 407 TrnsEgdPrFlwInfARC "Transmission Engaged Powerflow Information Alive Rolling Count";
BA_ "VNSigAllNodes" SG_ 407 TrnsEgdPrFlwInfARC 1;
BA_ "PacketOrder" SG_ 407 TEPI_TrnsEngdPrFlwStV 2;
BA_ "SignalType" SG_ 407 TEPI_TrnsEngdPrFlwStV "ENM";
BA_ "SignalLongName" SG_ 407 TEPI_TrnsEngdPrFlwStV "Transmission Engaged Powerflow Information : Transmission Engaged Powerflow State Validity";
BA_ "VNSigAllNodes" SG_ 407 TEPI_TrnsEngdPrFlwStV 1;
BA_ "PacketOrder" SG_ 407 TEPI_TrnsEngdPrFlwSt 1;
BA_ "SignalType" SG_ 407 TEPI_TrnsEngdPrFlwSt "ENM";
BA_ "SignalLongName" SG_ 407 TEPI_TrnsEngdPrFlwSt "Transmission Engaged Powerflow Information : Transmission Engaged Powerflow State";
BA_ "VNSigAllNodes" SG_ 407 TEPI_TrnsEngdPrFlwSt 1;
BA_ "SignalType" SG_ 407 TransRatioV "ENM";
BA_ "SignalLongName" SG_ 407 TransRatioV "Transmission Ratio Validity";
BA_ "VNSigAllNodes" SG_ 407 TransRatioV 1;
BA_ "SignalType" SG_ 407 TransRatio "UNM";
BA_ "SignalLongName" SG_ 407 TransRatio "Transmission Ratio";
BA_ "VNSigAllNodes" SG_ 407 TransRatio 1;
BA_ "SignalType" SG_ 407 TrnsOvrallActTorqRatioV "ENM";
BA_ "SignalLongName" SG_ 407 TrnsOvrallActTorqRatioV "Transmission Overall Actual Torque Ratio Validity";
BA_ "VNSigAllNodes" SG_ 407 TrnsOvrallActTorqRatioV 1;
BA_ "SignalType" SG_ 407 TrnsOvrallActTorqRatio "SNM";
BA_ "SignalLongName" SG_ 407 TrnsOvrallActTorqRatio "Transmission Overall Actual Torque Ratio";
BA_ "VNSigAllNodes" SG_ 407 TrnsOvrallActTorqRatio 1;
BA_ "SignalType" SG_ 189 HybDisengCruzCmnd "BLN";
BA_ "SignalLongName" SG_ 189 HybDisengCruzCmnd "Hybrid Disengage Cruise Commanded";
BA_ "VNSigAllNodes" SG_ 189 HybDisengCruzCmnd 1;
BA_ "SignalType" SG_ 189 TransVehTopSpdLim "UNM";
BA_ "SignalLongName" SG_ 189 TransVehTopSpdLim "Transmission Vehicle Top Speed Limit Value";
BA_ "GenSigStartValue" SG_ 189 TransVehTopSpdLim 255;
BA_ "VNSigAllNodes" SG_ 189 TransVehTopSpdLim 1;
BA_ "SignalType" SG_ 189 TransMinVoltReq "UNM";
BA_ "SignalLongName" SG_ 189 TransMinVoltReq "Transmission Minimum Voltage Request";
BA_ "VNSigAllNodes" SG_ 189 TransMinVoltReq 1;
BA_ "SignalType" SG_ 189 TrnsRtoCntlSysFlt "BLN";
BA_ "SignalLongName" SG_ 189 TrnsRtoCntlSysFlt "Transmission Ratio Control System Fault";
BA_ "VNSigAllNodes" SG_ 189 TrnsRtoCntlSysFlt 1;
BA_ "SignalType" SG_ 189 TransMnPressEstmd "UNM";
BA_ "SignalLongName" SG_ 189 TransMnPressEstmd "Transmission Main Pressure Estimated";
BA_ "VNSigAllNodes" SG_ 189 TransMnPressEstmd 1;
BA_ "SignalType" SG_ 189 TrnsInpMinSpdRq "ENM";
BA_ "SignalLongName" SG_ 189 TrnsInpMinSpdRq "Transmission Input Minimum Speed Request";
BA_ "VNSigAllNodes" SG_ 189 TrnsInpMinSpdRq 1;
BA_ "SignalType" SG_ 189 TrnsHydPrsDsrd "UNM";
BA_ "SignalLongName" SG_ 189 TrnsHydPrsDsrd "Transmission Hydraulic Pressure Desired";
BA_ "VNSigAllNodes" SG_ 189 TrnsHydPrsDsrd 1;
BA_ "SignalType" SG_ 189 TransAuxPumpSpdDsrd "UNM";
BA_ "SignalLongName" SG_ 189 TransAuxPumpSpdDsrd "Transmission Auxiliary Pump Speed Desired";
BA_ "VNSigAllNodes" SG_ 189 TransAuxPumpSpdDsrd 1;
BA_ "SignalType" SG_ 187 TransClch5_TorqCmnd "UNM";
BA_ "SignalLongName" SG_ 187 TransClch5_TorqCmnd "Transmission Clutch 5 Torque Command";
BA_ "VNSigAllNodes" SG_ 187 TransClch5_TorqCmnd 1;
BA_ "SignalType" SG_ 187 TransCltch5MinPrsRq "UNM";
BA_ "SignalLongName" SG_ 187 TransCltch5MinPrsRq "Transmission Clutch 5 Minimum Pressure Required";
BA_ "VNSigAllNodes" SG_ 187 TransCltch5MinPrsRq 1;
BA_ "SignalType" SG_ 187 TransCltch5FillCmd "ENM";
BA_ "SignalLongName" SG_ 187 TransCltch5FillCmd "Transmission Clutch 5 Fill Commanded";
BA_ "VNSigAllNodes" SG_ 187 TransCltch5FillCmd 1;
BA_ "SignalType" SG_ 187 TransClch4_TorqCmnd "UNM";
BA_ "SignalLongName" SG_ 187 TransClch4_TorqCmnd "Transmission Clutch 4 Torque Command";
BA_ "VNSigAllNodes" SG_ 187 TransClch4_TorqCmnd 1;
BA_ "SignalType" SG_ 187 TransCltch4MinPrsRq "UNM";
BA_ "SignalLongName" SG_ 187 TransCltch4MinPrsRq "Transmission Clutch 4 Minimum Pressure Required";
BA_ "VNSigAllNodes" SG_ 187 TransCltch4MinPrsRq 1;
BA_ "SignalType" SG_ 187 TransCltch4FillCmd "ENM";
BA_ "SignalLongName" SG_ 187 TransCltch4FillCmd "Transmission Clutch 4 Fill Commanded";
BA_ "VNSigAllNodes" SG_ 187 TransCltch4FillCmd 1;
BA_ "SignalType" SG_ 185 TransCltch1FillCmd "ENM";
BA_ "SignalLongName" SG_ 185 TransCltch1FillCmd "Transmission Clutch 1 Fill Commanded";
BA_ "VNSigAllNodes" SG_ 185 TransCltch1FillCmd 1;
BA_ "SignalType" SG_ 185 TransCltch1CntlRqPVal "UNM";
BA_ "SignalLongName" SG_ 185 TransCltch1CntlRqPVal "Transmission Clutch 1 Control Requested Protection Value";
BA_ "VNSigAllNodes" SG_ 185 TransCltch1CntlRqPVal 1;
BA_ "SignalType" SG_ 185 TransCltch1CntlRq "ENM";
BA_ "SignalLongName" SG_ 185 TransCltch1CntlRq "Transmission Clutch 1 Control Requested";
BA_ "VNSigAllNodes" SG_ 185 TransCltch1CntlRq 1;
BA_ "SignalType" SG_ 185 MtrBCoolFlwCmd "UNM";
BA_ "SignalLongName" SG_ 185 MtrBCoolFlwCmd "Motor B Cooling Flow Command";
BA_ "VNSigAllNodes" SG_ 185 MtrBCoolFlwCmd 1;
BA_ "SignalType" SG_ 185 MtrACoolFlwCmd "UNM";
BA_ "SignalLongName" SG_ 185 MtrACoolFlwCmd "Motor A Cooling Flow Command";
BA_ "VNSigAllNodes" SG_ 185 MtrACoolFlwCmd 1;
BA_ "SignalType" SG_ 185 TransCltchCntlARC "UNM";
BA_ "SignalLongName" SG_ 185 TransCltchCntlARC "Transmission Clutch Control Alive Rolling Count";
BA_ "VNSigAllNodes" SG_ 185 TransCltchCntlARC 1;
BA_ "SignalType" SG_ 185 TransCltch5CntlRqPVal "UNM";
BA_ "SignalLongName" SG_ 185 TransCltch5CntlRqPVal "Transmission Clutch 5 Control Requested Protection Value";
BA_ "VNSigAllNodes" SG_ 185 TransCltch5CntlRqPVal 1;
BA_ "SignalType" SG_ 185 TransCltch5CntlRq "ENM";
BA_ "SignalLongName" SG_ 185 TransCltch5CntlRq "Transmission Clutch 5 Control Requested";
BA_ "VNSigAllNodes" SG_ 185 TransCltch5CntlRq 1;
BA_ "SignalType" SG_ 185 TransCltch4CntlRqPVal "UNM";
BA_ "SignalLongName" SG_ 185 TransCltch4CntlRqPVal "Transmission Clutch 4 Control Requested Protection Value";
BA_ "VNSigAllNodes" SG_ 185 TransCltch4CntlRqPVal 1;
BA_ "SignalType" SG_ 185 TransCltch4CntlRq "ENM";
BA_ "SignalLongName" SG_ 185 TransCltch4CntlRq "Transmission Clutch 4 Control Requested";
BA_ "VNSigAllNodes" SG_ 185 TransCltch4CntlRq 1;
BA_ "SignalType" SG_ 185 TransCltch3CntlRqPVal "UNM";
BA_ "SignalLongName" SG_ 185 TransCltch3CntlRqPVal "Transmission Clutch 3 Control Requested Protection Value";
BA_ "VNSigAllNodes" SG_ 185 TransCltch3CntlRqPVal 1;
BA_ "SignalType" SG_ 185 TransCltch3CntlRq "ENM";
BA_ "SignalLongName" SG_ 185 TransCltch3CntlRq "Transmission Clutch 3 Control Requested";
BA_ "VNSigAllNodes" SG_ 185 TransCltch3CntlRq 1;
BA_ "SignalType" SG_ 185 TransCltch2CntlRqPVal "UNM";
BA_ "SignalLongName" SG_ 185 TransCltch2CntlRqPVal "Transmission Clutch 2 Control Requested Protection Value";
BA_ "VNSigAllNodes" SG_ 185 TransCltch2CntlRqPVal 1;
BA_ "SignalType" SG_ 185 TransCltch2CntlRq "ENM";
BA_ "SignalLongName" SG_ 185 TransCltch2CntlRq "Transmission Clutch 2 Control Requested";
BA_ "VNSigAllNodes" SG_ 185 TransCltch2CntlRq 1;
BA_ "SignalType" SG_ 185 TransClch1_TorqCmnd "UNM";
BA_ "SignalLongName" SG_ 185 TransClch1_TorqCmnd "Transmission Clutch 1 Torque Command";
BA_ "VNSigAllNodes" SG_ 185 TransClch1_TorqCmnd 1;
BA_ "SignalType" SG_ 185 TransCltch1MinPrsRq "UNM";
BA_ "SignalLongName" SG_ 185 TransCltch1MinPrsRq "Transmission Clutch 1 Minimum Pressure Required";
BA_ "VNSigAllNodes" SG_ 185 TransCltch1MinPrsRq 1;
BA_ "SignalType" SG_ 186 TransClch3_TorqCmnd "UNM";
BA_ "SignalLongName" SG_ 186 TransClch3_TorqCmnd "Transmission Clutch 3 Torque Command";
BA_ "VNSigAllNodes" SG_ 186 TransClch3_TorqCmnd 1;
BA_ "SignalType" SG_ 186 TransCltch3MinPrsRq "UNM";
BA_ "SignalLongName" SG_ 186 TransCltch3MinPrsRq "Transmission Clutch 3 Minimum Pressure Required";
BA_ "VNSigAllNodes" SG_ 186 TransCltch3MinPrsRq 1;
BA_ "SignalType" SG_ 186 TransCltch3FillCmd "ENM";
BA_ "SignalLongName" SG_ 186 TransCltch3FillCmd "Transmission Clutch 3 Fill Commanded";
BA_ "VNSigAllNodes" SG_ 186 TransCltch3FillCmd 1;
BA_ "SignalType" SG_ 186 TransClch2_TorqCmnd "UNM";
BA_ "SignalLongName" SG_ 186 TransClch2_TorqCmnd "Transmission Clutch 2 Torque Command";
BA_ "VNSigAllNodes" SG_ 186 TransClch2_TorqCmnd 1;
BA_ "SignalType" SG_ 186 TransCltch2MinPrsRq "UNM";
BA_ "SignalLongName" SG_ 186 TransCltch2MinPrsRq "Transmission Clutch 2 Minimum Pressure Required";
BA_ "VNSigAllNodes" SG_ 186 TransCltch2MinPrsRq 1;
BA_ "SignalType" SG_ 186 TransCltch2FillCmd "ENM";
BA_ "SignalLongName" SG_ 186 TransCltch2FillCmd "Transmission Clutch 2 Fill Commanded";
BA_ "VNSigAllNodes" SG_ 186 TransCltch2FillCmd 1;
BA_ "SignalType" SG_ 152 TransClch5MaxEngy "UNM";
BA_ "SignalLongName" SG_ 152 TransClch5MaxEngy "Transmission Clutch 5 Maximum Energy";
BA_ "VNSigAllNodes" SG_ 152 TransClch5MaxEngy 1;
BA_ "SignalType" SG_ 152 TransClch5FlTm "UNM";
BA_ "SignalLongName" SG_ 152 TransClch5FlTm "Transmission Clutch 5 Fill Time";
BA_ "VNSigAllNodes" SG_ 152 TransClch5FlTm 1;
BA_ "SignalType" SG_ 152 TransClch5FlAch "BLN";
BA_ "SignalLongName" SG_ 152 TransClch5FlAch "Transmission Clutch 5 Fill Achieved";
BA_ "VNSigAllNodes" SG_ 152 TransClch5FlAch 1;
BA_ "SignalType" SG_ 152 TransCltch5EstTrq "UNM";
BA_ "SignalLongName" SG_ 152 TransCltch5EstTrq "Transmission Clutch 5 Estimated Torque";
BA_ "VNSigAllNodes" SG_ 152 TransCltch5EstTrq 1;
BA_ "SignalType" SG_ 152 TransClch5_Avail "BLN";
BA_ "SignalLongName" SG_ 152 TransClch5_Avail "Transmission Clutch 5 Available";
BA_ "VNSigAllNodes" SG_ 152 TransClch5_Avail 1;
BA_ "SignalType" SG_ 152 TransClch4FlTm "UNM";
BA_ "SignalLongName" SG_ 152 TransClch4FlTm "Transmission Clutch 4 Fill Time";
BA_ "VNSigAllNodes" SG_ 152 TransClch4FlTm 1;
BA_ "SignalType" SG_ 152 TransClch4EstTorq "UNM";
BA_ "SignalLongName" SG_ 152 TransClch4EstTorq "Transmission Clutch 4 Estimated Torque";
BA_ "VNSigAllNodes" SG_ 152 TransClch4EstTorq 1;
BA_ "SignalType" SG_ 152 TransClch4MaxEnrgy "UNM";
BA_ "SignalLongName" SG_ 152 TransClch4MaxEnrgy "Transmission Clutch 4 Maximum Energy";
BA_ "VNSigAllNodes" SG_ 152 TransClch4MaxEnrgy 1;
BA_ "SignalType" SG_ 152 TransClch4FlAch "BLN";
BA_ "SignalLongName" SG_ 152 TransClch4FlAch "Transmission Clutch 4 Fill Achieved";
BA_ "VNSigAllNodes" SG_ 152 TransClch4FlAch 1;
BA_ "SignalType" SG_ 152 TransClch4_Avail "BLN";
BA_ "SignalLongName" SG_ 152 TransClch4_Avail "Transmission Clutch 4 Available";
BA_ "VNSigAllNodes" SG_ 152 TransClch4_Avail 1;
BA_ "SignalType" SG_ 151 TransClch3FlTm "UNM";
BA_ "SignalLongName" SG_ 151 TransClch3FlTm "Transmission Clutch 3 Fill Time";
BA_ "VNSigAllNodes" SG_ 151 TransClch3FlTm 1;
BA_ "SignalType" SG_ 151 TransClch3EstTorq "UNM";
BA_ "SignalLongName" SG_ 151 TransClch3EstTorq "Transmission Clutch 3 Estimated Torque";
BA_ "VNSigAllNodes" SG_ 151 TransClch3EstTorq 1;
BA_ "SignalType" SG_ 151 TransClch3MaxEnrgy "UNM";
BA_ "SignalLongName" SG_ 151 TransClch3MaxEnrgy "Transmission Clutch 3 Maximum Energy";
BA_ "VNSigAllNodes" SG_ 151 TransClch3MaxEnrgy 1;
BA_ "SignalType" SG_ 151 TransClch3FlAch "BLN";
BA_ "SignalLongName" SG_ 151 TransClch3FlAch "Transmission Clutch 3 Fill Achieved";
BA_ "VNSigAllNodes" SG_ 151 TransClch3FlAch 1;
BA_ "SignalType" SG_ 151 TransClch3_Avail "BLN";
BA_ "SignalLongName" SG_ 151 TransClch3_Avail "Transmission Clutch 3 Available";
BA_ "VNSigAllNodes" SG_ 151 TransClch3_Avail 1;
BA_ "SignalType" SG_ 151 TransClch2FlTm "UNM";
BA_ "SignalLongName" SG_ 151 TransClch2FlTm "Transmission Clutch 2 Fill Time";
BA_ "VNSigAllNodes" SG_ 151 TransClch2FlTm 1;
BA_ "SignalType" SG_ 151 TransClch2EstTorq "UNM";
BA_ "SignalLongName" SG_ 151 TransClch2EstTorq "Transmission Clutch 2 Estimated Torque";
BA_ "VNSigAllNodes" SG_ 151 TransClch2EstTorq 1;
BA_ "SignalType" SG_ 151 TransClch2MaxEnrgy "UNM";
BA_ "SignalLongName" SG_ 151 TransClch2MaxEnrgy "Transmission Clutch 2 Maximum Energy";
BA_ "VNSigAllNodes" SG_ 151 TransClch2MaxEnrgy 1;
BA_ "SignalType" SG_ 151 TransClch2FlAch "BLN";
BA_ "SignalLongName" SG_ 151 TransClch2FlAch "Transmission Clutch 2 Fill Achieved";
BA_ "VNSigAllNodes" SG_ 151 TransClch2FlAch 1;
BA_ "SignalType" SG_ 151 TransClch2_Avail "BLN";
BA_ "SignalLongName" SG_ 151 TransClch2_Avail "Transmission Clutch 2 Available";
BA_ "VNSigAllNodes" SG_ 151 TransClch2_Avail 1;
BA_ "SignalType" SG_ 150 TrnsInpDvcStat "ENM";
BA_ "SignalLongName" SG_ 150 TrnsInpDvcStat "Transmission Input Device Status";
BA_ "VNSigAllNodes" SG_ 150 TrnsInpDvcStat 1;
BA_ "SignalType" SG_ 150 TransInhibitNeut "BLN";
BA_ "SignalLongName" SG_ 150 TransInhibitNeut "Transmission Default Action Inhibit Neutral";
BA_ "VNSigAllNodes" SG_ 150 TransInhibitNeut 1;
BA_ "SignalType" SG_ 150 TransInhibitMode2 "BLN";
BA_ "SignalLongName" SG_ 150 TransInhibitMode2 "Transmission Default Action Inhibit Mode 2";
BA_ "VNSigAllNodes" SG_ 150 TransInhibitMode2 1;
BA_ "SignalType" SG_ 150 TransInhibitMode1 "BLN";
BA_ "SignalLongName" SG_ 150 TransInhibitMode1 "Transmission Default Action Inhibit Mode 1";
BA_ "VNSigAllNodes" SG_ 150 TransInhibitMode1 1;
BA_ "SignalType" SG_ 150 TransInhibitGear4 "BLN";
BA_ "SignalLongName" SG_ 150 TransInhibitGear4 "Transmission Default Action Inhibit Gear 4";
BA_ "VNSigAllNodes" SG_ 150 TransInhibitGear4 1;
BA_ "SignalType" SG_ 150 TransInhibitGear3 "BLN";
BA_ "SignalLongName" SG_ 150 TransInhibitGear3 "Transmission Default Action Inhibit Gear 3";
BA_ "VNSigAllNodes" SG_ 150 TransInhibitGear3 1;
BA_ "SignalType" SG_ 150 TransInhibitGear2 "BLN";
BA_ "SignalLongName" SG_ 150 TransInhibitGear2 "Transmission Default Action Inhibit Gear 2";
BA_ "VNSigAllNodes" SG_ 150 TransInhibitGear2 1;
BA_ "SignalType" SG_ 150 TransInhibitGear1 "BLN";
BA_ "SignalLongName" SG_ 150 TransInhibitGear1 "Transmission Default Action Inhibit Gear 1";
BA_ "VNSigAllNodes" SG_ 150 TransInhibitGear1 1;
BA_ "SignalType" SG_ 150 TrnsPTSysShtdwnRq "BLN";
BA_ "SignalLongName" SG_ 150 TrnsPTSysShtdwnRq "Transmission Powertrain System Shutdown Requested";
BA_ "VNSigAllNodes" SG_ 150 TrnsPTSysShtdwnRq 1;
BA_ "SignalType" SG_ 150 TransClch1FlTm "UNM";
BA_ "SignalLongName" SG_ 150 TransClch1FlTm "Transmission Clutch 1 Fill Time";
BA_ "VNSigAllNodes" SG_ 150 TransClch1FlTm 1;
BA_ "SignalType" SG_ 150 TransClch1EstTorq "UNM";
BA_ "SignalLongName" SG_ 150 TransClch1EstTorq "Transmission Clutch 1 Estimated Torque";
BA_ "VNSigAllNodes" SG_ 150 TransClch1EstTorq 1;
BA_ "SignalType" SG_ 150 TransClch1MaxEnrgy "UNM";
BA_ "SignalLongName" SG_ 150 TransClch1MaxEnrgy "Transmission Clutch 1 Maximum Energy";
BA_ "VNSigAllNodes" SG_ 150 TransClch1MaxEnrgy 1;
BA_ "SignalType" SG_ 150 TransClch1FlAch "BLN";
BA_ "SignalLongName" SG_ 150 TransClch1FlAch "Transmission Clutch 1 Fill Achieved";
BA_ "VNSigAllNodes" SG_ 150 TransClch1FlAch 1;
BA_ "SignalType" SG_ 150 TransClch1_Avail "BLN";
BA_ "SignalLongName" SG_ 150 TransClch1_Avail "Transmission Clutch 1 Available";
BA_ "VNSigAllNodes" SG_ 150 TransClch1_Avail 1;
BA_ "SignalType" SG_ 188 HybTrnsLubeFlwRqd "UNM";
BA_ "SignalLongName" SG_ 188 HybTrnsLubeFlwRqd "Hybrid Transmission Lube Flow Requested";
BA_ "VNSigAllNodes" SG_ 188 HybTrnsLubeFlwRqd 1;
BA_ "SignalType" SG_ 188 MtrBSpd "SNM";
BA_ "SignalLongName" SG_ 188 MtrBSpd "Motor B Speed";
BA_ "VNSigAllNodes" SG_ 188 MtrBSpd 1;
BA_ "SignalType" SG_ 188 MtrASpd "SNM";
BA_ "SignalLongName" SG_ 188 MtrASpd "Motor A Speed";
BA_ "VNSigAllNodes" SG_ 188 MtrASpd 1;
BA_ "SignalType" SG_ 188 HybTransStCmmnd "ENM";
BA_ "SignalLongName" SG_ 188 HybTransStCmmnd "Hybrid Transmission State Commanded";
BA_ "VNSigAllNodes" SG_ 188 HybTransStCmmnd 1;
BA_ "SignalType" SG_ 188 HybTransStAchvd "ENM";
BA_ "SignalLongName" SG_ 188 HybTransStAchvd "Hybrid Transmission State Achieved";
BA_ "VNSigAllNodes" SG_ 188 HybTransStAchvd 1;
BA_ "SignalType" SG_ 188 TransFldPmpCmd "ENM";
BA_ "SignalLongName" SG_ 188 TransFldPmpCmd "Transmission Fluid Pump Command";
BA_ "VNSigAllNodes" SG_ 188 TransFldPmpCmd 1;
BA_ "SignalType" SG_ 188 TransDirctnStV "ENM";
BA_ "SignalLongName" SG_ 188 TransDirctnStV "Transmission Direction State Validity";
BA_ "VNSigAllNodes" SG_ 188 TransDirctnStV 1;
BA_ "SignalType" SG_ 188 TransDirctnSt "ENM";
BA_ "SignalLongName" SG_ 188 TransDirctnSt "Transmission Direction State";
BA_ "VNSigAllNodes" SG_ 188 TransDirctnSt 1;
BA_ "SignalType" SG_ 188 TnsClchFlLnePrsBstRq "BLN";
BA_ "SignalLongName" SG_ 188 TnsClchFlLnePrsBstRq "Transmission Clutch Fill Line Pressure Boost Requested";
BA_ "VNSigAllNodes" SG_ 188 TnsClchFlLnePrsBstRq 1;
BA_ "SignalType" SG_ 188 TransAuxPumpSpd "UNM";
BA_ "SignalLongName" SG_ 188 TransAuxPumpSpd "Transmission Auxiliary Pump Speed";
BA_ "VNSigAllNodes" SG_ 188 TransAuxPumpSpd 1;
BA_ "SignalType" SG_ 188 TransAuxPumpAvail "BLN";
BA_ "SignalLongName" SG_ 188 TransAuxPumpAvail "Transmission Auxiliary Pump Available";
BA_ "VNSigAllNodes" SG_ 188 TransAuxPumpAvail 1;
BA_ "SignalType" SG_ 188 MtrBSpdV "ENM";
BA_ "SignalLongName" SG_ 188 MtrBSpdV "Motor B Speed Validity";
BA_ "VNSigAllNodes" SG_ 188 MtrBSpdV 1;
BA_ "SignalType" SG_ 188 MtrASpdV "ENM";
BA_ "SignalLongName" SG_ 188 MtrASpdV "Motor A Speed Validity";
BA_ "VNSigAllNodes" SG_ 188 MtrASpdV 1;
BA_ "SignalType" SG_ 170 EngCommFlrRedPwrCm "BLN";
BA_ "SignalLongName" SG_ 170 EngCommFlrRedPwrCm "Engine Communication Failure Reduced Power Commanded";
BA_ "VNSigAllNodes" SG_ 170 EngCommFlrRedPwrCm 1;
BA_ "SignalType" SG_ 170 CmndAxlTrqARC "UNM";
BA_ "SignalLongName" SG_ 170 CmndAxlTrqARC "Commanded Axle Torque Alive Rolling Count";
BA_ "VNSigAllNodes" SG_ 170 CmndAxlTrqARC 1;
BA_ "SignalType" SG_ 170 CmndAxlTrqRespTyp "ENM";
BA_ "SignalLongName" SG_ 170 CmndAxlTrqRespTyp "Commanded Axle Torque Response Type";
BA_ "VNSigAllNodes" SG_ 170 CmndAxlTrqRespTyp 1;
BA_ "SignalType" SG_ 170 CmndAxlTrqImm "UNM";
BA_ "SignalLongName" SG_ 170 CmndAxlTrqImm "Commanded Axle Torque Immediate";
BA_ "VNSigAllNodes" SG_ 170 CmndAxlTrqImm 1;
BA_ "SignalType" SG_ 170 AccPos "UNM";
BA_ "SignalLongName" SG_ 170 AccPos "Accelerator Effective Position";
BA_ "VNSigAllNodes" SG_ 170 AccPos 1;
BA_ "SignalType" SG_ 170 CmndAxlTrqPredct "UNM";
BA_ "SignalLongName" SG_ 170 CmndAxlTrqPredct "Commanded Axle Torque Predicted";
BA_ "VNSigAllNodes" SG_ 170 CmndAxlTrqPredct 1;
BA_ "SignalType" SG_ 170 CmndAxlTrqPredctProtVal "UNM";
BA_ "SignalLongName" SG_ 170 CmndAxlTrqPredctProtVal "Commanded Axle Torque Predicted Protection Value";
BA_ "VNSigAllNodes" SG_ 170 CmndAxlTrqPredctProtVal 1;
BA_ "SignalType" SG_ 1221 SpdLmtVsnFsdSpdUnt "ENM";
BA_ "SignalLongName" SG_ 1221 SpdLmtVsnFsdSpdUnt "Speed Limit Vision Fused Speed Unit";
BA_ "VNSigAllNodes" SG_ 1221 SpdLmtVsnFsdSpdUnt 1;
BA_ "SignalType" SG_ 1221 SpdLmtVnFsSpdNwDet "BLN";
BA_ "SignalLongName" SG_ 1221 SpdLmtVnFsSpdNwDet "Speed Limit Vision Fused Speed New Detected";
BA_ "VNSigAllNodes" SG_ 1221 SpdLmtVnFsSpdNwDet 1;
BA_ "SignalType" SG_ 1221 SpdLmtVsnFsdSpdM "ENM";
BA_ "SignalLongName" SG_ 1221 SpdLmtVsnFsdSpdM "Speed Limit Vision Fused Speed Mask";
BA_ "VNSigAllNodes" SG_ 1221 SpdLmtVsnFsdSpdM 1;
BA_ "SignalType" SG_ 1221 SpdLmtVsnFsdSpd "UNM";
BA_ "SignalLongName" SG_ 1221 SpdLmtVsnFsdSpd "Speed Limit Vision Fused Speed";
BA_ "VNSigAllNodes" SG_ 1221 SpdLmtVsnFsdSpd 1;
BA_ "SignalType" SG_ 1221 CCClntCrcFlwRtReq "UNM";
BA_ "SignalLongName" SG_ 1221 CCClntCrcFlwRtReq "Climate Control Coolant Circulation Flow Rate Request";
BA_ "VNSigAllNodes" SG_ 1221 CCClntCrcFlwRtReq 1;
BA_ "SignalType" SG_ 1243 CSERDTC_CdNum "UNM";
BA_ "PacketOrder" SG_ 1243 CSERDTC_CdNum 2;
BA_ "SignalLongName" SG_ 1243 CSERDTC_CdNum "Chassis System Emissions Related DTC : Code Number";
BA_ "VNSigAllNodes" SG_ 1243 CSERDTC_CdNum 1;
BA_ "SignalType" SG_ 1243 CSERDTC_SysDes "ENM";
BA_ "PacketOrder" SG_ 1243 CSERDTC_SysDes 1;
BA_ "SignalLongName" SG_ 1243 CSERDTC_SysDes "Chassis System Emissions Related DTC : System Designator";
BA_ "VNSigAllNodes" SG_ 1243 CSERDTC_SysDes 1;
BA_ "SignalType" SG_ 1243 ChsSysEmmRelMalfAct "BLN";
BA_ "SignalLongName" SG_ 1243 ChsSysEmmRelMalfAct "Chassis System Emissions Related Malfunction Active";
BA_ "VNSigAllNodes" SG_ 1243 ChsSysEmmRelMalfAct 1;
BA_ "SignalType" SG_ 979 SpdLmtrSttngTypAct "ENM";
BA_ "SignalLongName" SG_ 979 SpdLmtrSttngTypAct "Speed Limiter Setting Type Active";
BA_ "VNSigAllNodes" SG_ 979 SpdLmtrSttngTypAct 1;
BA_ "SignalType" SG_ 979 SetSpdLmtRchd "ENM";
BA_ "SignalLongName" SG_ 979 SetSpdLmtRchd "Set Speed Limit Reached";
BA_ "VNSigAllNodes" SG_ 979 SetSpdLmtRchd 1;
BA_ "SignalType" SG_ 979 PlatEngSpdCmdStPVal "UNM";
BA_ "SignalLongName" SG_ 979 PlatEngSpdCmdStPVal "Platform Engine Speed Command Status Protection Value";
BA_ "VNSigAllNodes" SG_ 979 PlatEngSpdCmdStPVal 1;
BA_ "SignalType" SG_ 979 PlatEngSpdCmdStARC "UNM";
BA_ "SignalLongName" SG_ 979 PlatEngSpdCmdStARC "Platform Engine Speed Command Status Alive Rolling Count";
BA_ "VNSigAllNodes" SG_ 979 PlatEngSpdCmdStARC 1;
BA_ "SignalType" SG_ 979 ElvtdIdlCstCrStVal "ENM";
BA_ "SignalLongName" SG_ 979 ElvtdIdlCstCrStVal "Elevated Idle Customization Current Setting Value";
BA_ "VNSigAllNodes" SG_ 979 ElvtdIdlCstCrStVal 1;
BA_ "SignalType" SG_ 979 ElvtdIdlCstStAvl "BLN";
BA_ "SignalLongName" SG_ 979 ElvtdIdlCstStAvl "Elevated Idle Customization Setting Available";
BA_ "VNSigAllNodes" SG_ 979 ElvtdIdlCstStAvl 1;
BA_ "SignalType" SG_ 979 PTABR_AccReq "SNM";
BA_ "PacketOrder" SG_ 979 PTABR_AccReq 2;
BA_ "SignalLongName" SG_ 979 PTABR_AccReq "Powertrain Automatic Braking Request : Acceleration Request";
BA_ "VNSigAllNodes" SG_ 979 PTABR_AccReq 1;
BA_ "SignalType" SG_ 979 PTABR_PTBrkRqAct "BLN";
BA_ "PacketOrder" SG_ 979 PTABR_PTBrkRqAct 1;
BA_ "SignalLongName" SG_ 979 PTABR_PTBrkRqAct "Powertrain Automatic Braking Request : Powertrain Brake Request Active";
BA_ "VNSigAllNodes" SG_ 979 PTABR_PTBrkRqAct 1;
BA_ "SignalType" SG_ 979 PTAutoBrkReqPVal "UNM";
BA_ "SignalLongName" SG_ 979 PTAutoBrkReqPVal "Powertrain Automatic Braking Request Protection Value";
BA_ "VNSigAllNodes" SG_ 979 PTAutoBrkReqPVal 1;
BA_ "SignalType" SG_ 979 PTAutoBrkReqARC "UNM";
BA_ "SignalLongName" SG_ 979 PTAutoBrkReqARC "Powertrain Automatic Braking Request Alive Rolling Count";
BA_ "VNSigAllNodes" SG_ 979 PTAutoBrkReqARC 1;
BA_ "SignalType" SG_ 979 BrkBstVacV "ENM";
BA_ "SignalLongName" SG_ 979 BrkBstVacV "Brake Boost Vacuum Validity";
BA_ "VNSigAllNodes" SG_ 979 BrkBstVacV 1;
BA_ "SignalType" SG_ 979 BrkBstVac "UNM";
BA_ "SignalLongName" SG_ 979 BrkBstVac "Brake Boost Vacuum";
BA_ "VNSigAllNodes" SG_ 979 BrkBstVac 1;
BA_ "SignalType" SG_ 979 EngManfldAirTempCrtdV "ENM";
BA_ "SignalLongName" SG_ 979 EngManfldAirTempCrtdV "Engine Manifold Air Temperature Corrected Validity";
BA_ "VNSigAllNodes" SG_ 979 EngManfldAirTempCrtdV 1;
BA_ "SignalType" SG_ 979 PltfrmEngSpdCmmndSt "ENM";
BA_ "SignalLongName" SG_ 979 PltfrmEngSpdCmmndSt "Platform Engine Speed Command Status";
BA_ "VNSigAllNodes" SG_ 979 PltfrmEngSpdCmmndSt 1;
BA_ "SignalType" SG_ 979 EngManfldAirTempCrtd "UNM";
BA_ "SignalLongName" SG_ 979 EngManfldAirTempCrtd "Engine Manifold Air Temperature Corrected";
BA_ "VNSigAllNodes" SG_ 979 EngManfldAirTempCrtd 1;
BA_ "SignalType" SG_ 546 ThrmlRefCmpIGBTTmp "UNM";
BA_ "SignalLongName" SG_ 546 ThrmlRefCmpIGBTTmp "Thermal Refrigerant Compressor Insulated Gate Bipolar Transistor Temperature";
BA_ "VNSigAllNodes" SG_ 546 ThrmlRefCmpIGBTTmp 1;
BA_ "SignalType" SG_ 546 CmpSnsrDataARC "UNM";
BA_ "SignalLongName" SG_ 546 CmpSnsrDataARC "Compressor Sensor Data Alive Rolling Count";
BA_ "VNSigAllNodes" SG_ 546 CmpSnsrDataARC 1;
BA_ "SignalType" SG_ 546 ThrmlRefCmpCPUHtSkTmp "UNM";
BA_ "SignalLongName" SG_ 546 ThrmlRefCmpCPUHtSkTmp "Thermal Refrigerant Compressor Central Processing Unit Heat Sink Temperature";
BA_ "VNSigAllNodes" SG_ 546 ThrmlRefCmpCPUHtSkTmp 1;
BA_ "SignalType" SG_ 546 ThrmlRefCmpHVInHRsln "UNM";
BA_ "SignalLongName" SG_ 546 ThrmlRefCmpHVInHRsln "Thermal Refrigerant Compressor High Voltage Input High Resolution";
BA_ "VNSigAllNodes" SG_ 546 ThrmlRefCmpHVInHRsln 1;
BA_ "SignalType" SG_ 546 ThrmlRfCmprElctrCrnt "UNM";
BA_ "SignalLongName" SG_ 546 ThrmlRfCmprElctrCrnt "Thermal Refrigerant Compressor Electrical Current";
BA_ "VNSigAllNodes" SG_ 546 ThrmlRfCmprElctrCrnt 1;
BA_ "SignalType" SG_ 546 ThrmlRefCompSpdFdbck "UNM";
BA_ "SignalLongName" SG_ 546 ThrmlRefCompSpdFdbck "Thermal Refrigerant Compressor Speed Feedback";
BA_ "VNSigAllNodes" SG_ 546 ThrmlRefCompSpdFdbck 1;
BA_ "SignalType" SG_ 546 ThrmlRefCompStatFdbck "ENM";
BA_ "SignalLongName" SG_ 546 ThrmlRefCompStatFdbck "Thermal Refrigerant Compressor Status Feedback";
BA_ "VNSigAllNodes" SG_ 546 ThrmlRefCompStatFdbck 1;
BA_ "SignalType" SG_ 530 RstVTDTmprDtctd "ENM";
BA_ "SignalLongName" SG_ 530 RstVTDTmprDtctd "Reset Vehicle Theft Deterrent Tamper Detected";
BA_ "VNSigAllNodes" SG_ 530 RstVTDTmprDtctd 1;
BA_ "SignalType" SG_ 530 RstIllDrIdDevDtctd "ENM";
BA_ "SignalLongName" SG_ 530 RstIllDrIdDevDtctd "Reset Illegitimate Driver Identification Device Detected";
BA_ "VNSigAllNodes" SG_ 530 RstIllDrIdDevDtctd 1;
BA_ "SignalType" SG_ 530 RstDrIdDevLrnd "ENM";
BA_ "SignalLongName" SG_ 530 RstDrIdDevLrnd "Reset Driver Identification Device Learned";
BA_ "VNSigAllNodes" SG_ 530 RstDrIdDevLrnd 1;
BA_ "SignalType" SG_ 1239 IBSBatSOC "UNM";
BA_ "SignalLongName" SG_ 1239 IBSBatSOC "Intelligent Battery Sensor Battery State of Charge";
BA_ "GenSigStartValue" SG_ 1239 IBSBatSOC 196;
BA_ "VNSigAllNodes" SG_ 1239 IBSBatSOC 1;
BA_ "SignalType" SG_ 1239 BattTemp "UNM";
BA_ "SignalLongName" SG_ 1239 BattTemp "Battery Temperature";
BA_ "GenSigStartValue" SG_ 1239 BattTemp 65;
BA_ "VNSigAllNodes" SG_ 1239 BattTemp 1;
BA_ "SignalType" SG_ 1239 BatSOH "UNM";
BA_ "SignalLongName" SG_ 1239 BatSOH "Battery State Of Health";
BA_ "GenSigStartValue" SG_ 1239 BatSOH 203.999928600025;
BA_ "VNSigAllNodes" SG_ 1239 BatSOH 1;
BA_ "SignalType" SG_ 1239 BatSOFVolt "UNM";
BA_ "SignalLongName" SG_ 1239 BatSOFVolt "Battery State Of Function Voltage";
BA_ "GenSigStartValue" SG_ 1239 BatSOFVolt 200;
BA_ "VNSigAllNodes" SG_ 1239 BatSOFVolt 1;
BA_ "SignalType" SG_ 1239 BattSOXStat "ENM";
BA_ "SignalLongName" SG_ 1239 BattSOXStat "Battery SOX Status";
BA_ "VNSigAllNodes" SG_ 1239 BattSOXStat 1;
BA_ "SignalType" SG_ 1239 BattTempV "ENM";
BA_ "SignalLongName" SG_ 1239 BattTempV "Battery Temperature Validity";
BA_ "VNSigAllNodes" SG_ 1239 BattTempV 1;
BA_ "VNSigSLHSSharedDiagnostic" SG_ 1610 DgnInf 1;
BA_ "SignalType" SG_ 1610 DgnInf "UNM";
BA_ "SignalLongName" SG_ 1610 DgnInf "Diagnostic Information";
BA_ "VNSigAllNodes" SG_ 1610 DgnInf 1;
BA_ "SignalType" SG_ 1027 GFHBFwVsnWidthTrk4 "UNM";
BA_ "SignalLongName" SG_ 1027 GFHBFwVsnWidthTrk4 "GFHB Forward Vision Width Track 4";
BA_ "VNSigAllNodes" SG_ 1027 GFHBFwVsnWidthTrk4 1;
BA_ "SignalType" SG_ 1027 GFHBFwVsnVertPosTrk4 "UNM";
BA_ "SignalLongName" SG_ 1027 GFHBFwVsnVertPosTrk4 "GFHB Forward Vision Vertical Position Track 4";
BA_ "VNSigAllNodes" SG_ 1027 GFHBFwVsnVertPosTrk4 1;
BA_ "SignalType" SG_ 1027 GFHBFwVsnRelLaneTrk4 "ENM";
BA_ "SignalLongName" SG_ 1027 GFHBFwVsnRelLaneTrk4 "GFHB Forward Vision Relative Lane Track 4";
BA_ "VNSigAllNodes" SG_ 1027 GFHBFwVsnRelLaneTrk4 1;
BA_ "SignalType" SG_ 1027 GFHBFwVsnAzmthRtTrk4 "SNM";
BA_ "SignalLongName" SG_ 1027 GFHBFwVsnAzmthRtTrk4 "GFHB Forward Vision Azimuth Rate Track 4";
BA_ "VNSigAllNodes" SG_ 1027 GFHBFwVsnAzmthRtTrk4 1;
BA_ "SignalType" SG_ 1027 GFHBFwVsnCnfdncTrk4 "ENM";
BA_ "SignalLongName" SG_ 1027 GFHBFwVsnCnfdncTrk4 "GFHB Forward Vision Confidence Track 4";
BA_ "VNSigAllNodes" SG_ 1027 GFHBFwVsnCnfdncTrk4 1;
BA_ "SignalType" SG_ 1027 GFHBFwVsnRngTrkRev4 "UNM";
BA_ "SignalLongName" SG_ 1027 GFHBFwVsnRngTrkRev4 "GFHB Forward Vision Range Track Revised 4";
BA_ "VNSigAllNodes" SG_ 1027 GFHBFwVsnRngTrkRev4 1;
BA_ "SignalType" SG_ 1027 GFHBFwVsnAzmthTrkRev4 "SNM";
BA_ "SignalLongName" SG_ 1027 GFHBFwVsnAzmthTrkRev4 "GFHB Forward Vision Azimuth Track Revised 4";
BA_ "VNSigAllNodes" SG_ 1027 GFHBFwVsnAzmthTrkRev4 1;
BA_ "SignalType" SG_ 1027 GFHBFVsnObjTypTrkRev4 "ENM";
BA_ "SignalLongName" SG_ 1027 GFHBFVsnObjTypTrkRev4 "GFHB Forward Vision Object Type Track Revised 4";
BA_ "VNSigAllNodes" SG_ 1027 GFHBFVsnObjTypTrkRev4 1;
BA_ "SignalType" SG_ 1027 GFHBObjDirTrk4 "ENM";
BA_ "SignalLongName" SG_ 1027 GFHBObjDirTrk4 "GFHB Object Direction Track 4";
BA_ "VNSigAllNodes" SG_ 1027 GFHBObjDirTrk4 1;
BA_ "SignalType" SG_ 1027 GFHBFwVsnMesStatTrk4 "ENM";
BA_ "SignalLongName" SG_ 1027 GFHBFwVsnMesStatTrk4 "GFHB Forward Vision Measurement Status Track 4";
BA_ "VNSigAllNodes" SG_ 1027 GFHBFwVsnMesStatTrk4 1;
BA_ "SignalType" SG_ 1027 GFHBFwVsnObjIDTrk4 "UNM";
BA_ "SignalLongName" SG_ 1027 GFHBFwVsnObjIDTrk4 "GFHB Forward Vision Object ID Track 4";
BA_ "VNSigAllNodes" SG_ 1027 GFHBFwVsnObjIDTrk4 1;
BA_ "SignalType" SG_ 1026 GFHBFwVsnWidthTrk3 "UNM";
BA_ "SignalLongName" SG_ 1026 GFHBFwVsnWidthTrk3 "GFHB Forward Vision Width Track 3";
BA_ "VNSigAllNodes" SG_ 1026 GFHBFwVsnWidthTrk3 1;
BA_ "SignalType" SG_ 1026 GFHBFwVsnVertPosTrk3 "UNM";
BA_ "SignalLongName" SG_ 1026 GFHBFwVsnVertPosTrk3 "GFHB Forward Vision Vertical Position Track 3";
BA_ "VNSigAllNodes" SG_ 1026 GFHBFwVsnVertPosTrk3 1;
BA_ "SignalType" SG_ 1026 GFHBFwVsnRelLaneTrk3 "ENM";
BA_ "SignalLongName" SG_ 1026 GFHBFwVsnRelLaneTrk3 "GFHB Forward Vision Relative Lane Track 3";
BA_ "VNSigAllNodes" SG_ 1026 GFHBFwVsnRelLaneTrk3 1;
BA_ "SignalType" SG_ 1026 GFHBFwVsnAzmthRtTrk3 "SNM";
BA_ "SignalLongName" SG_ 1026 GFHBFwVsnAzmthRtTrk3 "GFHB Forward Vision Azimuth Rate Track 3";
BA_ "VNSigAllNodes" SG_ 1026 GFHBFwVsnAzmthRtTrk3 1;
BA_ "SignalType" SG_ 1026 GFHBFwVsnCnfdncTrk3 "ENM";
BA_ "SignalLongName" SG_ 1026 GFHBFwVsnCnfdncTrk3 "GFHB Forward Vision Confidence Track 3";
BA_ "VNSigAllNodes" SG_ 1026 GFHBFwVsnCnfdncTrk3 1;
BA_ "SignalType" SG_ 1026 GFHBFwVsnRngTrkRev3 "UNM";
BA_ "SignalLongName" SG_ 1026 GFHBFwVsnRngTrkRev3 "GFHB Forward Vision Range Track Revised 3";
BA_ "VNSigAllNodes" SG_ 1026 GFHBFwVsnRngTrkRev3 1;
BA_ "SignalType" SG_ 1026 GFHBFwVsnAzmthTrkRev3 "SNM";
BA_ "SignalLongName" SG_ 1026 GFHBFwVsnAzmthTrkRev3 "GFHB Forward Vision Azimuth Track Revised 3";
BA_ "VNSigAllNodes" SG_ 1026 GFHBFwVsnAzmthTrkRev3 1;
BA_ "SignalType" SG_ 1026 GFHBFVsnObjTypTrkRev3 "ENM";
BA_ "SignalLongName" SG_ 1026 GFHBFVsnObjTypTrkRev3 "GFHB Forward Vision Object Type Track Revised 3";
BA_ "VNSigAllNodes" SG_ 1026 GFHBFVsnObjTypTrkRev3 1;
BA_ "SignalType" SG_ 1026 GFHBObjDirTrk3 "ENM";
BA_ "SignalLongName" SG_ 1026 GFHBObjDirTrk3 "GFHB Object Direction Track 3";
BA_ "VNSigAllNodes" SG_ 1026 GFHBObjDirTrk3 1;
BA_ "SignalType" SG_ 1026 GFHBFwVsnMesStatTrk3 "ENM";
BA_ "SignalLongName" SG_ 1026 GFHBFwVsnMesStatTrk3 "GFHB Forward Vision Measurement Status Track 3";
BA_ "VNSigAllNodes" SG_ 1026 GFHBFwVsnMesStatTrk3 1;
BA_ "SignalType" SG_ 1026 GFHBFwVsnObjIDTrk3 "UNM";
BA_ "SignalLongName" SG_ 1026 GFHBFwVsnObjIDTrk3 "GFHB Forward Vision Object ID Track 3";
BA_ "VNSigAllNodes" SG_ 1026 GFHBFwVsnObjIDTrk3 1;
BA_ "SignalType" SG_ 1025 GFHBFwVsnWidthTrk2 "UNM";
BA_ "SignalLongName" SG_ 1025 GFHBFwVsnWidthTrk2 "GFHB Forward Vision Width Track 2";
BA_ "VNSigAllNodes" SG_ 1025 GFHBFwVsnWidthTrk2 1;
BA_ "SignalType" SG_ 1025 GFHBFwVsnVertPosTrk2 "UNM";
BA_ "SignalLongName" SG_ 1025 GFHBFwVsnVertPosTrk2 "GFHB Forward Vision Vertical Position Track 2";
BA_ "VNSigAllNodes" SG_ 1025 GFHBFwVsnVertPosTrk2 1;
BA_ "SignalType" SG_ 1025 GFHBFwVsnRelLaneTrk2 "ENM";
BA_ "SignalLongName" SG_ 1025 GFHBFwVsnRelLaneTrk2 "GFHB Forward Vision Relative Lane Track 2";
BA_ "VNSigAllNodes" SG_ 1025 GFHBFwVsnRelLaneTrk2 1;
BA_ "SignalType" SG_ 1025 GFHBFwVsnAzmthRtTrk2 "SNM";
BA_ "SignalLongName" SG_ 1025 GFHBFwVsnAzmthRtTrk2 "GFHB Forward Vision Azimuth Rate Track 2";
BA_ "VNSigAllNodes" SG_ 1025 GFHBFwVsnAzmthRtTrk2 1;
BA_ "SignalType" SG_ 1025 GFHBFwVsnCnfdncTrk2 "ENM";
BA_ "SignalLongName" SG_ 1025 GFHBFwVsnCnfdncTrk2 "GFHB Forward Vision Confidence Track 2";
BA_ "VNSigAllNodes" SG_ 1025 GFHBFwVsnCnfdncTrk2 1;
BA_ "SignalType" SG_ 1025 GFHBFwVsnRngTrkRev2 "UNM";
BA_ "SignalLongName" SG_ 1025 GFHBFwVsnRngTrkRev2 "GFHB Forward Vision Range Track Revised 2";
BA_ "VNSigAllNodes" SG_ 1025 GFHBFwVsnRngTrkRev2 1;
BA_ "SignalType" SG_ 1025 GFHBFwVsnAzmthTrkRev2 "SNM";
BA_ "SignalLongName" SG_ 1025 GFHBFwVsnAzmthTrkRev2 "GFHB Forward Vision Azimuth Track Revised 2";
BA_ "VNSigAllNodes" SG_ 1025 GFHBFwVsnAzmthTrkRev2 1;
BA_ "SignalType" SG_ 1025 GFHBFVsnObjTypTrkRev2 "ENM";
BA_ "SignalLongName" SG_ 1025 GFHBFVsnObjTypTrkRev2 "GFHB Forward Vision Object Type Track Revised 2";
BA_ "VNSigAllNodes" SG_ 1025 GFHBFVsnObjTypTrkRev2 1;
BA_ "SignalType" SG_ 1025 GFHBObjDirTrk2 "ENM";
BA_ "SignalLongName" SG_ 1025 GFHBObjDirTrk2 "GFHB Object Direction Track 2";
BA_ "VNSigAllNodes" SG_ 1025 GFHBObjDirTrk2 1;
BA_ "SignalType" SG_ 1025 GFHBFwVsnMesStatTrk2 "ENM";
BA_ "SignalLongName" SG_ 1025 GFHBFwVsnMesStatTrk2 "GFHB Forward Vision Measurement Status Track 2";
BA_ "VNSigAllNodes" SG_ 1025 GFHBFwVsnMesStatTrk2 1;
BA_ "SignalType" SG_ 1025 GFHBFwVsnObjIDTrk2 "UNM";
BA_ "SignalLongName" SG_ 1025 GFHBFwVsnObjIDTrk2 "GFHB Forward Vision Object ID Track 2";
BA_ "VNSigAllNodes" SG_ 1025 GFHBFwVsnObjIDTrk2 1;
BA_ "SignalType" SG_ 1024 GFHBFwVsnWidthTrk1 "UNM";
BA_ "SignalLongName" SG_ 1024 GFHBFwVsnWidthTrk1 "GFHB Forward Vision Width Track 1";
BA_ "VNSigAllNodes" SG_ 1024 GFHBFwVsnWidthTrk1 1;
BA_ "SignalType" SG_ 1024 GFHBFwVsnVertPosTrk1 "UNM";
BA_ "SignalLongName" SG_ 1024 GFHBFwVsnVertPosTrk1 "GFHB Forward Vision Vertical Position Track 1";
BA_ "VNSigAllNodes" SG_ 1024 GFHBFwVsnVertPosTrk1 1;
BA_ "SignalType" SG_ 1024 GFHBFwVsnRelLaneTrk1 "ENM";
BA_ "SignalLongName" SG_ 1024 GFHBFwVsnRelLaneTrk1 "GFHB Forward Vision Relative Lane Track 1";
BA_ "VNSigAllNodes" SG_ 1024 GFHBFwVsnRelLaneTrk1 1;
BA_ "SignalType" SG_ 1024 GFHBFwVsnAzmthRtTrk1 "SNM";
BA_ "SignalLongName" SG_ 1024 GFHBFwVsnAzmthRtTrk1 "GFHB Forward Vision Azimuth Rate Track 1";
BA_ "VNSigAllNodes" SG_ 1024 GFHBFwVsnAzmthRtTrk1 1;
BA_ "SignalType" SG_ 1024 GFHBFwVsnCnfdncTrk1 "ENM";
BA_ "SignalLongName" SG_ 1024 GFHBFwVsnCnfdncTrk1 "GFHB Forward Vision Confidence Track 1";
BA_ "VNSigAllNodes" SG_ 1024 GFHBFwVsnCnfdncTrk1 1;
BA_ "SignalType" SG_ 1024 GFHBFwVsnRngTrkRev1 "UNM";
BA_ "SignalLongName" SG_ 1024 GFHBFwVsnRngTrkRev1 "GFHB Forward Vision Range Track Revised 1";
BA_ "VNSigAllNodes" SG_ 1024 GFHBFwVsnRngTrkRev1 1;
BA_ "SignalType" SG_ 1024 GFHBFwVsnAzmthTrkRev1 "SNM";
BA_ "SignalLongName" SG_ 1024 GFHBFwVsnAzmthTrkRev1 "GFHB Forward Vision Azimuth Track Revised 1";
BA_ "VNSigAllNodes" SG_ 1024 GFHBFwVsnAzmthTrkRev1 1;
BA_ "SignalType" SG_ 1024 GFHBFVsnObjTypTrkRev1 "ENM";
BA_ "SignalLongName" SG_ 1024 GFHBFVsnObjTypTrkRev1 "GFHB Forward Vision Object Type Track Revised 1";
BA_ "VNSigAllNodes" SG_ 1024 GFHBFVsnObjTypTrkRev1 1;
BA_ "SignalType" SG_ 1024 GFHBObjDirTrk1 "ENM";
BA_ "SignalLongName" SG_ 1024 GFHBObjDirTrk1 "GFHB Object Direction Track 1";
BA_ "VNSigAllNodes" SG_ 1024 GFHBObjDirTrk1 1;
BA_ "SignalType" SG_ 1024 GFHBFwVsnMesStatTrk1 "ENM";
BA_ "SignalLongName" SG_ 1024 GFHBFwVsnMesStatTrk1 "GFHB Forward Vision Measurement Status Track 1";
BA_ "VNSigAllNodes" SG_ 1024 GFHBFwVsnMesStatTrk1 1;
BA_ "SignalType" SG_ 1024 GFHBFwVsnObjIDTrk1 "UNM";
BA_ "SignalLongName" SG_ 1024 GFHBFwVsnObjIDTrk1 "GFHB Forward Vision Object ID Track 1";
BA_ "VNSigAllNodes" SG_ 1024 GFHBFwVsnObjIDTrk1 1;
BA_ "SignalType" SG_ 508 LonLatAccSnsChk "UNM";
BA_ "SignalLongName" SG_ 508 LonLatAccSnsChk "Longitudinal/Lateral Acceleration Sensor Checksum";
BA_ "VNSigAllNodes" SG_ 508 LonLatAccSnsChk 1;
BA_ "SignalType" SG_ 508 LonLatAccSnsValARC "UNM";
BA_ "SignalLongName" SG_ 508 LonLatAccSnsValARC "Longitudinal/Lateral Acceleration Sensor Value Alive Rolling Count";
BA_ "VNSigAllNodes" SG_ 508 LonLatAccSnsValARC 1;
BA_ "SignalType" SG_ 508 LatAccSnsVal "SNM";
BA_ "SignalLongName" SG_ 508 LatAccSnsVal "Lateral Acceleration Sensor Value";
BA_ "VNSigAllNodes" SG_ 508 LatAccSnsVal 1;
BA_ "SignalType" SG_ 508 LonAccSnsVal "SNM";
BA_ "SignalLongName" SG_ 508 LonAccSnsVal "Longitudinal Acceleration Sensor Value";
BA_ "VNSigAllNodes" SG_ 508 LonAccSnsVal 1;
BA_ "SignalType" SG_ 508 ChsSysTtlBkAxlTqStARC "UNM";
BA_ "SignalLongName" SG_ 508 ChsSysTtlBkAxlTqStARC "Chassis System Total Brake Axle Torque Status Alive Rolling Count";
BA_ "VNSigAllNodes" SG_ 508 ChsSysTtlBkAxlTqStARC 1;
BA_ "SignalType" SG_ 508 CSTBATS_TrqVl "UNM";
BA_ "PacketOrder" SG_ 508 CSTBATS_TrqVl 2;
BA_ "SignalLongName" SG_ 508 CSTBATS_TrqVl "Chassis System Total Brake Axle Torque Status : Torque Value";
BA_ "VNSigAllNodes" SG_ 508 CSTBATS_TrqVl 1;
BA_ "SignalType" SG_ 508 CSTBATS_TrqVlV "ENM";
BA_ "PacketOrder" SG_ 508 CSTBATS_TrqVlV 1;
BA_ "SignalLongName" SG_ 508 CSTBATS_TrqVlV "Chassis System Total Brake Axle Torque Status : Torque Value Validity";
BA_ "VNSigAllNodes" SG_ 508 CSTBATS_TrqVlV 1;
BA_ "SignalType" SG_ 422 TrnsAuxPrsDisOvrrdOn "BLN";
BA_ "SignalLongName" SG_ 422 TrnsAuxPrsDisOvrrdOn "Transmission Auxiliary Pressure Discharge Override On";
BA_ "VNSigAllNodes" SG_ 422 TrnsAuxPrsDisOvrrdOn 1;
BA_ "SignalType" SG_ 422 TransEngShtdwnReqdPVa "UNM";
BA_ "SignalLongName" SG_ 422 TransEngShtdwnReqdPVa "Transmission Engine Shutdown Requested Protection Value";
BA_ "VNSigAllNodes" SG_ 422 TransEngShtdwnReqdPVa 1;
BA_ "SignalType" SG_ 422 TrnsEngShtdwnRqARC "UNM";
BA_ "SignalLongName" SG_ 422 TrnsEngShtdwnRqARC "Transmission Engine Shutdown Requested Alive Rolling Count";
BA_ "VNSigAllNodes" SG_ 422 TrnsEngShtdwnRqARC 1;
BA_ "SignalType" SG_ 422 TransEngShtdwnRqd "BLN";
BA_ "SignalLongName" SG_ 422 TransEngShtdwnRqd "Transmission Engine Shutdown Requested";
BA_ "VNSigAllNodes" SG_ 422 TransEngShtdwnRqd 1;
BA_ "SignalType" SG_ 422 TransCrksftTqLoadV "ENM";
BA_ "SignalLongName" SG_ 422 TransCrksftTqLoadV "Transmission Crankshaft Torque Load Validity";
BA_ "VNSigAllNodes" SG_ 422 TransCrksftTqLoadV 1;
BA_ "SignalType" SG_ 422 TransCrksftTqLoad "UNM";
BA_ "SignalLongName" SG_ 422 TransCrksftTqLoad "Transmission Crankshaft Torque Load";
BA_ "VNSigAllNodes" SG_ 422 TransCrksftTqLoad 1;
BA_ "SignalType" SG_ 422 TrStPTGrdBrkDsMdOvr "ENM";
BA_ "SignalLongName" SG_ 422 TrStPTGrdBrkDsMdOvr "Transmission State Powertrain Grade Braking  Disable Mode Override";
BA_ "VNSigAllNodes" SG_ 422 TrStPTGrdBrkDsMdOvr 1;
BA_ "SignalType" SG_ 422 TrnsHybEngSrtStpOvrd "ENM";
BA_ "SignalLongName" SG_ 422 TrnsHybEngSrtStpOvrd "Transmission Hybrid Engine Start Stop Override";
BA_ "VNSigAllNodes" SG_ 422 TrnsHybEngSrtStpOvrd 1;
BA_ "SignalType" SG_ 647 EngDetPndTrnCsRngShfV "ENM";
BA_ "SignalLongName" SG_ 647 EngDetPndTrnCsRngShfV "Engine Determined Pending Transfer Case Range Shift Validity";
BA_ "VNSigAllNodes" SG_ 647 EngDetPndTrnCsRngShfV 1;
BA_ "SignalType" SG_ 647 EngDetPndTrnCsRngShf "ENM";
BA_ "SignalLongName" SG_ 647 EngDetPndTrnCsRngShf "Engine Determined Pending Transfer Case Range Shift";
BA_ "VNSigAllNodes" SG_ 647 EngDetPndTrnCsRngShf 1;
BA_ "SignalType" SG_ 647 CrpCstCrvCmd "ENM";
BA_ "SignalLongName" SG_ 647 CrpCstCrvCmd "Creep Coast Curve Commanded";
BA_ "VNSigAllNodes" SG_ 647 CrpCstCrvCmd 1;
BA_ "SignalType" SG_ 647 DrvMntnMdCmnd "BLN";
BA_ "SignalLongName" SG_ 647 DrvMntnMdCmnd "Driver Mountain Mode Commanded";
BA_ "VNSigAllNodes" SG_ 647 DrvMntnMdCmnd 1;
BA_ "SignalType" SG_ 647 DrvHldMdCmnd "BLN";
BA_ "SignalLongName" SG_ 647 DrvHldMdCmnd "Driver Hold Mode Commanded";
BA_ "VNSigAllNodes" SG_ 647 DrvHldMdCmnd 1;
BA_ "SignalType" SG_ 647 DrPTGrdBrkDsbMdCmd "BLN";
BA_ "SignalLongName" SG_ 647 DrPTGrdBrkDsbMdCmd "Driver Powertrain Grade Braking Disable Mode Commanded";
BA_ "VNSigAllNodes" SG_ 647 DrPTGrdBrkDsbMdCmd 1;
BA_ "SignalType" SG_ 647 DrvWntrMdCmd "BLN";
BA_ "SignalLongName" SG_ 647 DrvWntrMdCmd "Driver Winter Mode Commanded";
BA_ "VNSigAllNodes" SG_ 647 DrvWntrMdCmd 1;
BA_ "SignalType" SG_ 647 DrvTwHaulMdCmd "BLN";
BA_ "SignalLongName" SG_ 647 DrvTwHaulMdCmd "Driver Tow Haul Mode Commanded";
BA_ "VNSigAllNodes" SG_ 647 DrvTwHaulMdCmd 1;
BA_ "SignalType" SG_ 647 DrvSprtMdCmd "BLN";
BA_ "SignalLongName" SG_ 647 DrvSprtMdCmd "Driver Sport Mode Commanded";
BA_ "VNSigAllNodes" SG_ 647 DrvSprtMdCmd 1;
BA_ "SignalType" SG_ 647 DrvEconMdCmd "BLN";
BA_ "SignalLongName" SG_ 647 DrvEconMdCmd "Driver Economy Mode Commanded";
BA_ "VNSigAllNodes" SG_ 647 DrvEconMdCmd 1;
BA_ "SignalType" SG_ 647 EngCntrlDtrmdTrfCRngV "ENM";
BA_ "SignalLongName" SG_ 647 EngCntrlDtrmdTrfCRngV "Engine Controller Determined Transfer Case Range Validity";
BA_ "VNSigAllNodes" SG_ 647 EngCntrlDtrmdTrfCRngV 1;
BA_ "SignalType" SG_ 647 EngCntrlDtrmdTrfCRng "ENM";
BA_ "SignalLongName" SG_ 647 EngCntrlDtrmdTrfCRng "Engine Controller Determined Transfer Case Range";
BA_ "VNSigAllNodes" SG_ 647 EngCntrlDtrmdTrfCRng 1;
BA_ "SignalType" SG_ 647 EngCtrlUtldTrnCRgPVal "UNM";
BA_ "SignalLongName" SG_ 647 EngCtrlUtldTrnCRgPVal "Engine Controller Utilized Transfer Case Range Protection Value";
BA_ "VNSigAllNodes" SG_ 647 EngCtrlUtldTrnCRgPVal 1;
BA_ "SignalType" SG_ 647 EngCntrlUtldTrnCsRng "ENM";
BA_ "SignalLongName" SG_ 647 EngCntrlUtldTrnCsRng "Engine Controller Utilized Transfer Case Range";
BA_ "VNSigAllNodes" SG_ 647 EngCntrlUtldTrnCsRng 1;
BA_ "SignalType" SG_ 647 EngCntrlUtldTrnCsRgIn "BLN";
BA_ "SignalLongName" SG_ 647 EngCntrlUtldTrnCsRgIn "Engine Controller Utilized Transfer Case Range Inconsistent";
BA_ "VNSigAllNodes" SG_ 647 EngCntrlUtldTrnCsRgIn 1;
BA_ "SignalType" SG_ 647 EngCtrlUtldTrnCRgARC "UNM";
BA_ "SignalLongName" SG_ 647 EngCtrlUtldTrnCRgARC "Engine Controller Utilized Transfer Case Range Alive Rolling Count";
BA_ "VNSigAllNodes" SG_ 647 EngCtrlUtldTrnCRgARC 1;
BA_ "SignalType" SG_ 368 EnvIdRspSt5 "ENM";
BA_ "SignalLongName" SG_ 368 EnvIdRspSt5 "Environment Identification Response Status 5";
BA_ "VNSigAllNodes" SG_ 368 EnvIdRspSt5 1;
BA_ "SignalType" SG_ 368 EnvIdRsp5 "UNM";
BA_ "SignalLongName" SG_ 368 EnvIdRsp5 "Environment Identification Response 5";
BA_ "VNSigAllNodes" SG_ 368 EnvIdRsp5 1;
BA_REL_ "GenSigSuprvResp" BU_SG_REL_ BCM_HS SG_ 565 PerfMdMainMenuType 1;
BA_REL_ "GenSigTimeoutMsg" BU_SG_REL_ BCM_HS SG_ 565 PerfMdMainMenuType 565;
BA_REL_ "GenSigTimeoutTime" BU_SG_REL_ BCM_HS SG_ 565 PerfMdMainMenuType 5000;
BA_REL_ "GenSigSuprvResp" BU_SG_REL_ BCM_HS SG_ 565 PSPMCA_PsngStPrfMd6Avl 1;
BA_REL_ "GenSigTimeoutMsg" BU_SG_REL_ BCM_HS SG_ 565 PSPMCA_PsngStPrfMd6Avl 565;
BA_REL_ "GenSigTimeoutTime" BU_SG_REL_ BCM_HS SG_ 565 PSPMCA_PsngStPrfMd6Avl 5000;
BA_REL_ "GenSigSuprvResp" BU_SG_REL_ BCM_HS SG_ 565 PSPMCA_PsngStPrfMd5Avl 1;
BA_REL_ "GenSigTimeoutMsg" BU_SG_REL_ BCM_HS SG_ 565 PSPMCA_PsngStPrfMd5Avl 565;
BA_REL_ "GenSigTimeoutTime" BU_SG_REL_ BCM_HS SG_ 565 PSPMCA_PsngStPrfMd5Avl 5000;
BA_REL_ "GenSigSuprvResp" BU_SG_REL_ BCM_HS SG_ 565 PSPMCA_PsngStPrfMd4Avl 1;
BA_REL_ "GenSigTimeoutMsg" BU_SG_REL_ BCM_HS SG_ 565 PSPMCA_PsngStPrfMd4Avl 565;
BA_REL_ "GenSigTimeoutTime" BU_SG_REL_ BCM_HS SG_ 565 PSPMCA_PsngStPrfMd4Avl 5000;
BA_REL_ "GenSigSuprvResp" BU_SG_REL_ BCM_HS SG_ 565 PSPMCA_PsngStPrfMd3Avl 1;
BA_REL_ "GenSigTimeoutMsg" BU_SG_REL_ BCM_HS SG_ 565 PSPMCA_PsngStPrfMd3Avl 565;
BA_REL_ "GenSigTimeoutTime" BU_SG_REL_ BCM_HS SG_ 565 PSPMCA_PsngStPrfMd3Avl 5000;
BA_REL_ "GenSigSuprvResp" BU_SG_REL_ BCM_HS SG_ 565 PSPMCA_PsngStPrfMd2Avl 1;
BA_REL_ "GenSigTimeoutMsg" BU_SG_REL_ BCM_HS SG_ 565 PSPMCA_PsngStPrfMd2Avl 565;
BA_REL_ "GenSigTimeoutTime" BU_SG_REL_ BCM_HS SG_ 565 PSPMCA_PsngStPrfMd2Avl 5000;
BA_REL_ "GenSigSuprvResp" BU_SG_REL_ BCM_HS SG_ 565 PSPMCA_PsngStPrfMd1Avl 1;
BA_REL_ "GenSigTimeoutMsg" BU_SG_REL_ BCM_HS SG_ 565 PSPMCA_PsngStPrfMd1Avl 565;
BA_REL_ "GenSigTimeoutTime" BU_SG_REL_ BCM_HS SG_ 565 PSPMCA_PsngStPrfMd1Avl 5000;
BA_REL_ "GenSigSuprvResp" BU_SG_REL_ BCM_HS SG_ 565 DSPMCA_DrvStyPrfMd7Avl 1;
BA_REL_ "GenSigTimeoutMsg" BU_SG_REL_ BCM_HS SG_ 565 DSPMCA_DrvStyPrfMd7Avl 565;
BA_REL_ "GenSigTimeoutTime" BU_SG_REL_ BCM_HS SG_ 565 DSPMCA_DrvStyPrfMd7Avl 5000;
BA_REL_ "GenSigSuprvResp" BU_SG_REL_ BCM_HS SG_ 565 DSPMCA_DrvStyPrfMd6Avl 1;
BA_REL_ "GenSigTimeoutMsg" BU_SG_REL_ BCM_HS SG_ 565 DSPMCA_DrvStyPrfMd6Avl 565;
BA_REL_ "GenSigTimeoutTime" BU_SG_REL_ BCM_HS SG_ 565 DSPMCA_DrvStyPrfMd6Avl 5000;
BA_REL_ "GenSigSuprvResp" BU_SG_REL_ BCM_HS SG_ 565 DSPMCA_DrvStyPrfMd5Avl 1;
BA_REL_ "GenSigTimeoutMsg" BU_SG_REL_ BCM_HS SG_ 565 DSPMCA_DrvStyPrfMd5Avl 565;
BA_REL_ "GenSigTimeoutTime" BU_SG_REL_ BCM_HS SG_ 565 DSPMCA_DrvStyPrfMd5Avl 5000;
BA_REL_ "GenSigSuprvResp" BU_SG_REL_ BCM_HS SG_ 565 DSPMCA_DrvStyPrfMd4Avl 1;
BA_REL_ "GenSigTimeoutMsg" BU_SG_REL_ BCM_HS SG_ 565 DSPMCA_DrvStyPrfMd4Avl 565;
BA_REL_ "GenSigTimeoutTime" BU_SG_REL_ BCM_HS SG_ 565 DSPMCA_DrvStyPrfMd4Avl 5000;
BA_REL_ "GenSigSuprvResp" BU_SG_REL_ BCM_HS SG_ 565 DSPMCA_DrvStyPrfMd3Avl 1;
BA_REL_ "GenSigTimeoutMsg" BU_SG_REL_ BCM_HS SG_ 565 DSPMCA_DrvStyPrfMd3Avl 565;
BA_REL_ "GenSigTimeoutTime" BU_SG_REL_ BCM_HS SG_ 565 DSPMCA_DrvStyPrfMd3Avl 5000;
BA_REL_ "GenSigSuprvResp" BU_SG_REL_ BCM_HS SG_ 565 DSPMCA_DrvStyPrfMd2Avl 1;
BA_REL_ "GenSigTimeoutMsg" BU_SG_REL_ BCM_HS SG_ 565 DSPMCA_DrvStyPrfMd2Avl 565;
BA_REL_ "GenSigTimeoutTime" BU_SG_REL_ BCM_HS SG_ 565 DSPMCA_DrvStyPrfMd2Avl 5000;
BA_REL_ "GenSigSuprvResp" BU_SG_REL_ BCM_HS SG_ 565 DSPMCA_DrvStyPrfMd1Avl 1;
BA_REL_ "GenSigTimeoutMsg" BU_SG_REL_ BCM_HS SG_ 565 DSPMCA_DrvStyPrfMd1Avl 565;
BA_REL_ "GenSigTimeoutTime" BU_SG_REL_ BCM_HS SG_ 565 DSPMCA_DrvStyPrfMd1Avl 5000;
BA_REL_ "GenSigSuprvResp" BU_SG_REL_ BCM_HS SG_ 565 DSPMCA_DrvrStPrfMd6Avl 1;
BA_REL_ "GenSigTimeoutMsg" BU_SG_REL_ BCM_HS SG_ 565 DSPMCA_DrvrStPrfMd6Avl 565;
BA_REL_ "GenSigTimeoutTime" BU_SG_REL_ BCM_HS SG_ 565 DSPMCA_DrvrStPrfMd6Avl 5000;
BA_REL_ "GenSigSuprvResp" BU_SG_REL_ BCM_HS SG_ 565 DSPMCA_DrvrStPrfMd5Avl 1;
BA_REL_ "GenSigTimeoutMsg" BU_SG_REL_ BCM_HS SG_ 565 DSPMCA_DrvrStPrfMd5Avl 565;
BA_REL_ "GenSigTimeoutTime" BU_SG_REL_ BCM_HS SG_ 565 DSPMCA_DrvrStPrfMd5Avl 5000;
BA_REL_ "GenSigSuprvResp" BU_SG_REL_ BCM_HS SG_ 565 DSPMCA_DrvrStPrfMd4Avl 1;
BA_REL_ "GenSigTimeoutMsg" BU_SG_REL_ BCM_HS SG_ 565 DSPMCA_DrvrStPrfMd4Avl 565;
BA_REL_ "GenSigTimeoutTime" BU_SG_REL_ BCM_HS SG_ 565 DSPMCA_DrvrStPrfMd4Avl 5000;
BA_REL_ "GenSigSuprvResp" BU_SG_REL_ BCM_HS SG_ 565 DSPMCA_DrvrStPrfMd3Avl 1;
BA_REL_ "GenSigTimeoutMsg" BU_SG_REL_ BCM_HS SG_ 565 DSPMCA_DrvrStPrfMd3Avl 565;
BA_REL_ "GenSigTimeoutTime" BU_SG_REL_ BCM_HS SG_ 565 DSPMCA_DrvrStPrfMd3Avl 5000;
BA_REL_ "GenSigSuprvResp" BU_SG_REL_ BCM_HS SG_ 565 DSPMCA_DrvrStPrfMd2Avl 1;
BA_REL_ "GenSigTimeoutMsg" BU_SG_REL_ BCM_HS SG_ 565 DSPMCA_DrvrStPrfMd2Avl 565;
BA_REL_ "GenSigTimeoutTime" BU_SG_REL_ BCM_HS SG_ 565 DSPMCA_DrvrStPrfMd2Avl 5000;
BA_REL_ "GenSigSuprvResp" BU_SG_REL_ BCM_HS SG_ 565 DSPMCA_DrvrStPrfMd1Avl 1;
BA_REL_ "GenSigTimeoutMsg" BU_SG_REL_ BCM_HS SG_ 565 DSPMCA_DrvrStPrfMd1Avl 565;
BA_REL_ "GenSigTimeoutTime" BU_SG_REL_ BCM_HS SG_ 565 DSPMCA_DrvrStPrfMd1Avl 5000;
BA_REL_ "GenSigSuprvResp" BU_SG_REL_ BCM_HS SG_ 565 ACCPMCA_ACCPrfMd6Avl 1;
BA_REL_ "GenSigTimeoutMsg" BU_SG_REL_ BCM_HS SG_ 565 ACCPMCA_ACCPrfMd6Avl 565;
BA_REL_ "GenSigTimeoutTime" BU_SG_REL_ BCM_HS SG_ 565 ACCPMCA_ACCPrfMd6Avl 5000;
BA_REL_ "GenSigSuprvResp" BU_SG_REL_ BCM_HS SG_ 565 ACCPMCA_ACCPrfMd5Avl 1;
BA_REL_ "GenSigTimeoutMsg" BU_SG_REL_ BCM_HS SG_ 565 ACCPMCA_ACCPrfMd5Avl 565;
BA_REL_ "GenSigTimeoutTime" BU_SG_REL_ BCM_HS SG_ 565 ACCPMCA_ACCPrfMd5Avl 5000;
BA_REL_ "GenSigSuprvResp" BU_SG_REL_ BCM_HS SG_ 565 ACCPMCA_ACCPrfMd4Avl 1;
BA_REL_ "GenSigTimeoutMsg" BU_SG_REL_ BCM_HS SG_ 565 ACCPMCA_ACCPrfMd4Avl 565;
BA_REL_ "GenSigTimeoutTime" BU_SG_REL_ BCM_HS SG_ 565 ACCPMCA_ACCPrfMd4Avl 5000;
BA_REL_ "GenSigSuprvResp" BU_SG_REL_ BCM_HS SG_ 565 ACCPMCA_ACCPrfMd3Avl 1;
BA_REL_ "GenSigTimeoutMsg" BU_SG_REL_ BCM_HS SG_ 565 ACCPMCA_ACCPrfMd3Avl 565;
BA_REL_ "GenSigTimeoutTime" BU_SG_REL_ BCM_HS SG_ 565 ACCPMCA_ACCPrfMd3Avl 5000;
BA_REL_ "GenSigSuprvResp" BU_SG_REL_ BCM_HS SG_ 565 ACCPMCA_ACCPrfMd2Avl 1;
BA_REL_ "GenSigTimeoutMsg" BU_SG_REL_ BCM_HS SG_ 565 ACCPMCA_ACCPrfMd2Avl 565;
BA_REL_ "GenSigTimeoutTime" BU_SG_REL_ BCM_HS SG_ 565 ACCPMCA_ACCPrfMd2Avl 5000;
BA_REL_ "GenSigSuprvResp" BU_SG_REL_ BCM_HS SG_ 565 ACCPMCA_ACCPrfMd1Avl 1;
BA_REL_ "GenSigTimeoutMsg" BU_SG_REL_ BCM_HS SG_ 565 ACCPMCA_ACCPrfMd1Avl 565;
BA_REL_ "GenSigTimeoutTime" BU_SG_REL_ BCM_HS SG_ 565 ACCPMCA_ACCPrfMd1Avl 5000;
BA_REL_ "GenSigSuprvResp" BU_SG_REL_ AHL_AFL_HS SG_ 1029 GFHBFwVsnWidthTrk6 1;
BA_REL_ "GenSigTimeoutMsg" BU_SG_REL_ AHL_AFL_HS SG_ 1029 GFHBFwVsnWidthTrk6 1029;
BA_REL_ "GenSigTimeoutTime" BU_SG_REL_ AHL_AFL_HS SG_ 1029 GFHBFwVsnWidthTrk6 250;
BA_REL_ "GenSigSuprvResp" BU_SG_REL_ AHL_AFL_HS SG_ 1029 GFHBFwVsnVertPosTrk6 1;
BA_REL_ "GenSigTimeoutMsg" BU_SG_REL_ AHL_AFL_HS SG_ 1029 GFHBFwVsnVertPosTrk6 1029;
BA_REL_ "GenSigTimeoutTime" BU_SG_REL_ AHL_AFL_HS SG_ 1029 GFHBFwVsnVertPosTrk6 250;
BA_REL_ "GenSigSuprvResp" BU_SG_REL_ AHL_AFL_HS SG_ 1029 GFHBFwVsnRelLaneTrk6 1;
BA_REL_ "GenSigTimeoutMsg" BU_SG_REL_ AHL_AFL_HS SG_ 1029 GFHBFwVsnRelLaneTrk6 1029;
BA_REL_ "GenSigTimeoutTime" BU_SG_REL_ AHL_AFL_HS SG_ 1029 GFHBFwVsnRelLaneTrk6 250;
BA_REL_ "GenSigSuprvResp" BU_SG_REL_ AHL_AFL_HS SG_ 1029 GFHBFwVsnAzmthRtTrk6 1;
BA_REL_ "GenSigTimeoutMsg" BU_SG_REL_ AHL_AFL_HS SG_ 1029 GFHBFwVsnAzmthRtTrk6 1029;
BA_REL_ "GenSigTimeoutTime" BU_SG_REL_ AHL_AFL_HS SG_ 1029 GFHBFwVsnAzmthRtTrk6 250;
BA_REL_ "GenSigSuprvResp" BU_SG_REL_ AHL_AFL_HS SG_ 1029 GFHBFwVsnCnfdncTrk6 1;
BA_REL_ "GenSigTimeoutMsg" BU_SG_REL_ AHL_AFL_HS SG_ 1029 GFHBFwVsnCnfdncTrk6 1029;
BA_REL_ "GenSigTimeoutTime" BU_SG_REL_ AHL_AFL_HS SG_ 1029 GFHBFwVsnCnfdncTrk6 250;
BA_REL_ "GenSigSuprvResp" BU_SG_REL_ AHL_AFL_HS SG_ 1029 GFHBFwVsnRngTrkRev6 1;
BA_REL_ "GenSigTimeoutMsg" BU_SG_REL_ AHL_AFL_HS SG_ 1029 GFHBFwVsnRngTrkRev6 1029;
BA_REL_ "GenSigTimeoutTime" BU_SG_REL_ AHL_AFL_HS SG_ 1029 GFHBFwVsnRngTrkRev6 250;
BA_REL_ "GenSigSuprvResp" BU_SG_REL_ AHL_AFL_HS SG_ 1029 GFHBFwVsnAzmthTrkRev6 1;
BA_REL_ "GenSigTimeoutMsg" BU_SG_REL_ AHL_AFL_HS SG_ 1029 GFHBFwVsnAzmthTrkRev6 1029;
BA_REL_ "GenSigTimeoutTime" BU_SG_REL_ AHL_AFL_HS SG_ 1029 GFHBFwVsnAzmthTrkRev6 250;
BA_REL_ "GenSigSuprvResp" BU_SG_REL_ AHL_AFL_HS SG_ 1029 GFHBFVsnObjTypTrkRev6 1;
BA_REL_ "GenSigTimeoutMsg" BU_SG_REL_ AHL_AFL_HS SG_ 1029 GFHBFVsnObjTypTrkRev6 1029;
BA_REL_ "GenSigTimeoutTime" BU_SG_REL_ AHL_AFL_HS SG_ 1029 GFHBFVsnObjTypTrkRev6 250;
BA_REL_ "GenSigSuprvResp" BU_SG_REL_ AHL_AFL_HS SG_ 1029 GFHBObjDirTrk6 1;
BA_REL_ "GenSigTimeoutMsg" BU_SG_REL_ AHL_AFL_HS SG_ 1029 GFHBObjDirTrk6 1029;
BA_REL_ "GenSigTimeoutTime" BU_SG_REL_ AHL_AFL_HS SG_ 1029 GFHBObjDirTrk6 250;
BA_REL_ "GenSigSuprvResp" BU_SG_REL_ AHL_AFL_HS SG_ 1029 GFHBFwVsnMesStatTrk6 1;
BA_REL_ "GenSigTimeoutMsg" BU_SG_REL_ AHL_AFL_HS SG_ 1029 GFHBFwVsnMesStatTrk6 1029;
BA_REL_ "GenSigTimeoutTime" BU_SG_REL_ AHL_AFL_HS SG_ 1029 GFHBFwVsnMesStatTrk6 250;
BA_REL_ "GenSigSuprvResp" BU_SG_REL_ AHL_AFL_HS SG_ 1029 GFHBFwVsnObjIDTrk6 1;
BA_REL_ "GenSigTimeoutMsg" BU_SG_REL_ AHL_AFL_HS SG_ 1029 GFHBFwVsnObjIDTrk6 1029;
BA_REL_ "GenSigTimeoutTime" BU_SG_REL_ AHL_AFL_HS SG_ 1029 GFHBFwVsnObjIDTrk6 250;
BA_REL_ "GenSigSuprvResp" BU_SG_REL_ AHL_AFL_HS SG_ 1028 GFHBFwVsnWidthTrk5 1;
BA_REL_ "GenSigTimeoutMsg" BU_SG_REL_ AHL_AFL_HS SG_ 1028 GFHBFwVsnWidthTrk5 1028;
BA_REL_ "GenSigTimeoutTime" BU_SG_REL_ AHL_AFL_HS SG_ 1028 GFHBFwVsnWidthTrk5 250;
BA_REL_ "GenSigSuprvResp" BU_SG_REL_ AHL_AFL_HS SG_ 1028 GFHBFwVsnVertPosTrk5 1;
BA_REL_ "GenSigTimeoutMsg" BU_SG_REL_ AHL_AFL_HS SG_ 1028 GFHBFwVsnVertPosTrk5 1028;
BA_REL_ "GenSigTimeoutTime" BU_SG_REL_ AHL_AFL_HS SG_ 1028 GFHBFwVsnVertPosTrk5 250;
BA_REL_ "GenSigSuprvResp" BU_SG_REL_ AHL_AFL_HS SG_ 1028 GFHBFwVsnRelLaneTrk5 1;
BA_REL_ "GenSigTimeoutMsg" BU_SG_REL_ AHL_AFL_HS SG_ 1028 GFHBFwVsnRelLaneTrk5 1028;
BA_REL_ "GenSigTimeoutTime" BU_SG_REL_ AHL_AFL_HS SG_ 1028 GFHBFwVsnRelLaneTrk5 250;
BA_REL_ "GenSigSuprvResp" BU_SG_REL_ AHL_AFL_HS SG_ 1028 GFHBFwVsnAzmthRtTrk5 1;
BA_REL_ "GenSigTimeoutMsg" BU_SG_REL_ AHL_AFL_HS SG_ 1028 GFHBFwVsnAzmthRtTrk5 1028;
BA_REL_ "GenSigTimeoutTime" BU_SG_REL_ AHL_AFL_HS SG_ 1028 GFHBFwVsnAzmthRtTrk5 250;
BA_REL_ "GenSigSuprvResp" BU_SG_REL_ AHL_AFL_HS SG_ 1028 GFHBFwVsnCnfdncTrk5 1;
BA_REL_ "GenSigTimeoutMsg" BU_SG_REL_ AHL_AFL_HS SG_ 1028 GFHBFwVsnCnfdncTrk5 1028;
BA_REL_ "GenSigTimeoutTime" BU_SG_REL_ AHL_AFL_HS SG_ 1028 GFHBFwVsnCnfdncTrk5 250;
BA_REL_ "GenSigSuprvResp" BU_SG_REL_ AHL_AFL_HS SG_ 1028 GFHBFwVsnRngTrkRev5 1;
BA_REL_ "GenSigTimeoutMsg" BU_SG_REL_ AHL_AFL_HS SG_ 1028 GFHBFwVsnRngTrkRev5 1028;
BA_REL_ "GenSigTimeoutTime" BU_SG_REL_ AHL_AFL_HS SG_ 1028 GFHBFwVsnRngTrkRev5 250;
BA_REL_ "GenSigSuprvResp" BU_SG_REL_ AHL_AFL_HS SG_ 1028 GFHBFwVsnAzmthTrkRev5 1;
BA_REL_ "GenSigTimeoutMsg" BU_SG_REL_ AHL_AFL_HS SG_ 1028 GFHBFwVsnAzmthTrkRev5 1028;
BA_REL_ "GenSigTimeoutTime" BU_SG_REL_ AHL_AFL_HS SG_ 1028 GFHBFwVsnAzmthTrkRev5 250;
BA_REL_ "GenSigSuprvResp" BU_SG_REL_ AHL_AFL_HS SG_ 1028 GFHBFVsnObjTypTrkRev5 1;
BA_REL_ "GenSigTimeoutMsg" BU_SG_REL_ AHL_AFL_HS SG_ 1028 GFHBFVsnObjTypTrkRev5 1028;
BA_REL_ "GenSigTimeoutTime" BU_SG_REL_ AHL_AFL_HS SG_ 1028 GFHBFVsnObjTypTrkRev5 250;
BA_REL_ "GenSigSuprvResp" BU_SG_REL_ AHL_AFL_HS SG_ 1028 GFHBObjDirTrk5 1;
BA_REL_ "GenSigTimeoutMsg" BU_SG_REL_ AHL_AFL_HS SG_ 1028 GFHBObjDirTrk5 1028;
BA_REL_ "GenSigTimeoutTime" BU_SG_REL_ AHL_AFL_HS SG_ 1028 GFHBObjDirTrk5 250;
BA_REL_ "GenSigSuprvResp" BU_SG_REL_ AHL_AFL_HS SG_ 1028 GFHBFwVsnMesStatTrk5 1;
BA_REL_ "GenSigTimeoutMsg" BU_SG_REL_ AHL_AFL_HS SG_ 1028 GFHBFwVsnMesStatTrk5 1028;
BA_REL_ "GenSigTimeoutTime" BU_SG_REL_ AHL_AFL_HS SG_ 1028 GFHBFwVsnMesStatTrk5 250;
BA_REL_ "GenSigSuprvResp" BU_SG_REL_ AHL_AFL_HS SG_ 1028 GFHBFwVsnObjIDTrk5 1;
BA_REL_ "GenSigTimeoutMsg" BU_SG_REL_ AHL_AFL_HS SG_ 1028 GFHBFwVsnObjIDTrk5 1028;
BA_REL_ "GenSigTimeoutTime" BU_SG_REL_ AHL_AFL_HS SG_ 1028 GFHBFwVsnObjIDTrk5 250;
BA_REL_ "GenSigSuprvResp" BU_SG_REL_ EBCM_OBD_HS SG_ 500 EnhDrvMdSwChUseAct 1;
BA_REL_ "GenSigTimeoutMsg" BU_SG_REL_ EBCM_OBD_HS SG_ 500 EnhDrvMdSwChUseAct 500;
BA_REL_ "GenSigTimeoutTime" BU_SG_REL_ EBCM_OBD_HS SG_ 500 EnhDrvMdSwChUseAct 250;
BA_REL_ "GenSigSuprvResp" BU_SG_REL_ EBCM_HS SG_ 500 EnhDrvMdSwChUseAct 1;
BA_REL_ "GenSigTimeoutMsg" BU_SG_REL_ EBCM_HS SG_ 500 EnhDrvMdSwChUseAct 500;
BA_REL_ "GenSigTimeoutTime" BU_SG_REL_ EBCM_HS SG_ 500 EnhDrvMdSwChUseAct 250;
BA_REL_ "GenSigSuprvResp" BU_SG_REL_ EBCM_OBD_HS SG_ 500 EnhDrvSelMdSwStat 1;
BA_REL_ "GenSigTimeoutMsg" BU_SG_REL_ EBCM_OBD_HS SG_ 500 EnhDrvSelMdSwStat 500;
BA_REL_ "GenSigTimeoutTime" BU_SG_REL_ EBCM_OBD_HS SG_ 500 EnhDrvSelMdSwStat 250;
BA_REL_ "GenSigSuprvResp" BU_SG_REL_ EBCM_HS SG_ 500 EnhDrvSelMdSwStat 1;
BA_REL_ "GenSigTimeoutMsg" BU_SG_REL_ EBCM_HS SG_ 500 EnhDrvSelMdSwStat 500;
BA_REL_ "GenSigTimeoutTime" BU_SG_REL_ EBCM_HS SG_ 500 EnhDrvSelMdSwStat 250;
BA_REL_ "GenSigSuprvResp" BU_SG_REL_ RDCM_HS SG_ 500 DrvSelMd8Stat 1;
BA_REL_ "GenSigTimeoutMsg" BU_SG_REL_ RDCM_HS SG_ 500 DrvSelMd8Stat 500;
BA_REL_ "GenSigTimeoutTime" BU_SG_REL_ RDCM_HS SG_ 500 DrvSelMd8Stat 250;
BA_REL_ "GenSigSuprvResp" BU_SG_REL_ SADS_HS SG_ 500 DrvSelMd8Stat 1;
BA_REL_ "GenSigTimeoutMsg" BU_SG_REL_ SADS_HS SG_ 500 DrvSelMd8Stat 500;
BA_REL_ "GenSigTimeoutTime" BU_SG_REL_ SADS_HS SG_ 500 DrvSelMd8Stat 250;
BA_REL_ "GenSigSuprvResp" BU_SG_REL_ RDCM_HS SG_ 500 DrvSelMd8ReqDnd 1;
BA_REL_ "GenSigTimeoutMsg" BU_SG_REL_ RDCM_HS SG_ 500 DrvSelMd8ReqDnd 500;
BA_REL_ "GenSigTimeoutTime" BU_SG_REL_ RDCM_HS SG_ 500 DrvSelMd8ReqDnd 250;
BA_REL_ "GenSigSuprvResp" BU_SG_REL_ RDCM_HS SG_ 500 DrvSelMd7Stat 1;
BA_REL_ "GenSigTimeoutMsg" BU_SG_REL_ RDCM_HS SG_ 500 DrvSelMd7Stat 500;
BA_REL_ "GenSigTimeoutTime" BU_SG_REL_ RDCM_HS SG_ 500 DrvSelMd7Stat 250;
BA_REL_ "GenSigSuprvResp" BU_SG_REL_ EBCM_OBD_HS SG_ 500 DrvSelMd7Stat 1;
BA_REL_ "GenSigTimeoutMsg" BU_SG_REL_ EBCM_OBD_HS SG_ 500 DrvSelMd7Stat 500;
BA_REL_ "GenSigTimeoutTime" BU_SG_REL_ EBCM_OBD_HS SG_ 500 DrvSelMd7Stat 250;
BA_REL_ "GenSigSuprvResp" BU_SG_REL_ EBCM_HS SG_ 500 DrvSelMd7Stat 1;
BA_REL_ "GenSigTimeoutMsg" BU_SG_REL_ EBCM_HS SG_ 500 DrvSelMd7Stat 500;
BA_REL_ "GenSigTimeoutTime" BU_SG_REL_ EBCM_HS SG_ 500 DrvSelMd7Stat 250;
BA_REL_ "GenSigSuprvResp" BU_SG_REL_ SADS_HS SG_ 500 DrvSelMd7Stat 1;
BA_REL_ "GenSigTimeoutMsg" BU_SG_REL_ SADS_HS SG_ 500 DrvSelMd7Stat 500;
BA_REL_ "GenSigTimeoutTime" BU_SG_REL_ SADS_HS SG_ 500 DrvSelMd7Stat 250;
BA_REL_ "GenSigSuprvResp" BU_SG_REL_ RDCM_HS SG_ 500 DrvSelMd7ReqDnd 1;
BA_REL_ "GenSigTimeoutMsg" BU_SG_REL_ RDCM_HS SG_ 500 DrvSelMd7ReqDnd 500;
BA_REL_ "GenSigTimeoutTime" BU_SG_REL_ RDCM_HS SG_ 500 DrvSelMd7ReqDnd 250;
BA_REL_ "GenSigSuprvResp" BU_SG_REL_ RDCM_HS SG_ 500 DrvSelMd6Stat 1;
BA_REL_ "GenSigTimeoutMsg" BU_SG_REL_ RDCM_HS SG_ 500 DrvSelMd6Stat 500;
BA_REL_ "GenSigTimeoutTime" BU_SG_REL_ RDCM_HS SG_ 500 DrvSelMd6Stat 250;
BA_REL_ "GenSigSuprvResp" BU_SG_REL_ SADS_HS SG_ 500 DrvSelMd6Stat 1;
BA_REL_ "GenSigTimeoutMsg" BU_SG_REL_ SADS_HS SG_ 500 DrvSelMd6Stat 500;
BA_REL_ "GenSigTimeoutTime" BU_SG_REL_ SADS_HS SG_ 500 DrvSelMd6Stat 250;
BA_REL_ "GenSigSuprvResp" BU_SG_REL_ EBCM_OBD_HS SG_ 500 DrvSelMd6Stat 1;
BA_REL_ "GenSigTimeoutMsg" BU_SG_REL_ EBCM_OBD_HS SG_ 500 DrvSelMd6Stat 500;
BA_REL_ "GenSigTimeoutTime" BU_SG_REL_ EBCM_OBD_HS SG_ 500 DrvSelMd6Stat 250;
BA_REL_ "GenSigSuprvResp" BU_SG_REL_ EBCM_HS SG_ 500 DrvSelMd6Stat 1;
BA_REL_ "GenSigTimeoutMsg" BU_SG_REL_ EBCM_HS SG_ 500 DrvSelMd6Stat 500;
BA_REL_ "GenSigTimeoutTime" BU_SG_REL_ EBCM_HS SG_ 500 DrvSelMd6Stat 250;
BA_REL_ "GenSigSuprvResp" BU_SG_REL_ RDCM_HS SG_ 500 DrvSelMd6ReqDnd 1;
BA_REL_ "GenSigTimeoutMsg" BU_SG_REL_ RDCM_HS SG_ 500 DrvSelMd6ReqDnd 500;
BA_REL_ "GenSigTimeoutTime" BU_SG_REL_ RDCM_HS SG_ 500 DrvSelMd6ReqDnd 250;
BA_REL_ "GenSigSuprvResp" BU_SG_REL_ RDCM_HS SG_ 500 DrvSelMd5Stat 1;
BA_REL_ "GenSigTimeoutMsg" BU_SG_REL_ RDCM_HS SG_ 500 DrvSelMd5Stat 500;
BA_REL_ "GenSigTimeoutTime" BU_SG_REL_ RDCM_HS SG_ 500 DrvSelMd5Stat 250;
BA_REL_ "GenSigSuprvResp" BU_SG_REL_ SADS_HS SG_ 500 DrvSelMd5Stat 1;
BA_REL_ "GenSigTimeoutMsg" BU_SG_REL_ SADS_HS SG_ 500 DrvSelMd5Stat 500;
BA_REL_ "GenSigTimeoutTime" BU_SG_REL_ SADS_HS SG_ 500 DrvSelMd5Stat 250;
BA_REL_ "GenSigSuprvResp" BU_SG_REL_ EBCM_OBD_HS SG_ 500 DrvSelMd5Stat 1;
BA_REL_ "GenSigTimeoutMsg" BU_SG_REL_ EBCM_OBD_HS SG_ 500 DrvSelMd5Stat 500;
BA_REL_ "GenSigTimeoutTime" BU_SG_REL_ EBCM_OBD_HS SG_ 500 DrvSelMd5Stat 250;
BA_REL_ "GenSigSuprvResp" BU_SG_REL_ EBCM_HS SG_ 500 DrvSelMd5Stat 1;
BA_REL_ "GenSigTimeoutMsg" BU_SG_REL_ EBCM_HS SG_ 500 DrvSelMd5Stat 500;
BA_REL_ "GenSigTimeoutTime" BU_SG_REL_ EBCM_HS SG_ 500 DrvSelMd5Stat 250;
BA_REL_ "GenSigSuprvResp" BU_SG_REL_ RDCM_HS SG_ 500 DrvSelMd5ReqDnd 1;
BA_REL_ "GenSigTimeoutMsg" BU_SG_REL_ RDCM_HS SG_ 500 DrvSelMd5ReqDnd 500;
BA_REL_ "GenSigTimeoutTime" BU_SG_REL_ RDCM_HS SG_ 500 DrvSelMd5ReqDnd 250;
BA_REL_ "GenSigSuprvResp" BU_SG_REL_ RDCM_HS SG_ 500 DrvSelMd4Stat 1;
BA_REL_ "GenSigTimeoutMsg" BU_SG_REL_ RDCM_HS SG_ 500 DrvSelMd4Stat 500;
BA_REL_ "GenSigTimeoutTime" BU_SG_REL_ RDCM_HS SG_ 500 DrvSelMd4Stat 250;
BA_REL_ "GenSigSuprvResp" BU_SG_REL_ SADS_HS SG_ 500 DrvSelMd4Stat 1;
BA_REL_ "GenSigTimeoutMsg" BU_SG_REL_ SADS_HS SG_ 500 DrvSelMd4Stat 500;
BA_REL_ "GenSigTimeoutTime" BU_SG_REL_ SADS_HS SG_ 500 DrvSelMd4Stat 250;
BA_REL_ "GenSigSuprvResp" BU_SG_REL_ EBCM_OBD_HS SG_ 500 DrvSelMd4Stat 1;
BA_REL_ "GenSigTimeoutMsg" BU_SG_REL_ EBCM_OBD_HS SG_ 500 DrvSelMd4Stat 500;
BA_REL_ "GenSigTimeoutTime" BU_SG_REL_ EBCM_OBD_HS SG_ 500 DrvSelMd4Stat 250;
BA_REL_ "GenSigSuprvResp" BU_SG_REL_ EBCM_HS SG_ 500 DrvSelMd4Stat 1;
BA_REL_ "GenSigTimeoutMsg" BU_SG_REL_ EBCM_HS SG_ 500 DrvSelMd4Stat 500;
BA_REL_ "GenSigTimeoutTime" BU_SG_REL_ EBCM_HS SG_ 500 DrvSelMd4Stat 250;
BA_REL_ "GenSigSuprvResp" BU_SG_REL_ RDCM_HS SG_ 500 DrvSelMd4ReqDnd 1;
BA_REL_ "GenSigTimeoutMsg" BU_SG_REL_ RDCM_HS SG_ 500 DrvSelMd4ReqDnd 500;
BA_REL_ "GenSigTimeoutTime" BU_SG_REL_ RDCM_HS SG_ 500 DrvSelMd4ReqDnd 250;
BA_REL_ "GenSigSuprvResp" BU_SG_REL_ RDCM_HS SG_ 500 DrvSelMd3Stat 1;
BA_REL_ "GenSigTimeoutMsg" BU_SG_REL_ RDCM_HS SG_ 500 DrvSelMd3Stat 500;
BA_REL_ "GenSigTimeoutTime" BU_SG_REL_ RDCM_HS SG_ 500 DrvSelMd3Stat 250;
BA_REL_ "GenSigSuprvResp" BU_SG_REL_ SADS_HS SG_ 500 DrvSelMd3Stat 1;
BA_REL_ "GenSigTimeoutMsg" BU_SG_REL_ SADS_HS SG_ 500 DrvSelMd3Stat 500;
BA_REL_ "GenSigTimeoutTime" BU_SG_REL_ SADS_HS SG_ 500 DrvSelMd3Stat 250;
BA_REL_ "GenSigSuprvResp" BU_SG_REL_ EBCM_OBD_HS SG_ 500 DrvSelMd3Stat 1;
BA_REL_ "GenSigTimeoutMsg" BU_SG_REL_ EBCM_OBD_HS SG_ 500 DrvSelMd3Stat 500;
BA_REL_ "GenSigTimeoutTime" BU_SG_REL_ EBCM_OBD_HS SG_ 500 DrvSelMd3Stat 250;
BA_REL_ "GenSigSuprvResp" BU_SG_REL_ EBCM_HS SG_ 500 DrvSelMd3Stat 1;
BA_REL_ "GenSigTimeoutMsg" BU_SG_REL_ EBCM_HS SG_ 500 DrvSelMd3Stat 500;
BA_REL_ "GenSigTimeoutTime" BU_SG_REL_ EBCM_HS SG_ 500 DrvSelMd3Stat 250;
BA_REL_ "GenSigSuprvResp" BU_SG_REL_ RDCM_HS SG_ 500 DrvSelMd3ReqDnd 1;
BA_REL_ "GenSigTimeoutMsg" BU_SG_REL_ RDCM_HS SG_ 500 DrvSelMd3ReqDnd 500;
BA_REL_ "GenSigTimeoutTime" BU_SG_REL_ RDCM_HS SG_ 500 DrvSelMd3ReqDnd 250;
BA_REL_ "GenSigSuprvResp" BU_SG_REL_ RDCM_HS SG_ 500 DrvSelMd2Stat 1;
BA_REL_ "GenSigTimeoutMsg" BU_SG_REL_ RDCM_HS SG_ 500 DrvSelMd2Stat 500;
BA_REL_ "GenSigTimeoutTime" BU_SG_REL_ RDCM_HS SG_ 500 DrvSelMd2Stat 250;
BA_REL_ "GenSigSuprvResp" BU_SG_REL_ SADS_HS SG_ 500 DrvSelMd2Stat 1;
BA_REL_ "GenSigTimeoutMsg" BU_SG_REL_ SADS_HS SG_ 500 DrvSelMd2Stat 500;
BA_REL_ "GenSigTimeoutTime" BU_SG_REL_ SADS_HS SG_ 500 DrvSelMd2Stat 250;
BA_REL_ "GenSigSuprvResp" BU_SG_REL_ EBCM_OBD_HS SG_ 500 DrvSelMd2Stat 1;
BA_REL_ "GenSigTimeoutMsg" BU_SG_REL_ EBCM_OBD_HS SG_ 500 DrvSelMd2Stat 500;
BA_REL_ "GenSigTimeoutTime" BU_SG_REL_ EBCM_OBD_HS SG_ 500 DrvSelMd2Stat 250;
BA_REL_ "GenSigSuprvResp" BU_SG_REL_ EBCM_HS SG_ 500 DrvSelMd2Stat 1;
BA_REL_ "GenSigTimeoutMsg" BU_SG_REL_ EBCM_HS SG_ 500 DrvSelMd2Stat 500;
BA_REL_ "GenSigTimeoutTime" BU_SG_REL_ EBCM_HS SG_ 500 DrvSelMd2Stat 250;
BA_REL_ "GenSigSuprvResp" BU_SG_REL_ RDCM_HS SG_ 500 DrvSelMd2ReqDnd 1;
BA_REL_ "GenSigTimeoutMsg" BU_SG_REL_ RDCM_HS SG_ 500 DrvSelMd2ReqDnd 500;
BA_REL_ "GenSigTimeoutTime" BU_SG_REL_ RDCM_HS SG_ 500 DrvSelMd2ReqDnd 250;
BA_REL_ "GenSigSuprvResp" BU_SG_REL_ EBCM_OBD_HS SG_ 500 DSMSS_DrvSelMd0Pn 1;
BA_REL_ "GenSigTimeoutMsg" BU_SG_REL_ EBCM_OBD_HS SG_ 500 DSMSS_DrvSelMd0Pn 500;
BA_REL_ "GenSigTimeoutTime" BU_SG_REL_ EBCM_OBD_HS SG_ 500 DSMSS_DrvSelMd0Pn 250;
BA_REL_ "GenSigSuprvResp" BU_SG_REL_ EBCM_HS SG_ 500 DSMSS_DrvSelMd0Pn 1;
BA_REL_ "GenSigTimeoutMsg" BU_SG_REL_ EBCM_HS SG_ 500 DSMSS_DrvSelMd0Pn 500;
BA_REL_ "GenSigTimeoutTime" BU_SG_REL_ EBCM_HS SG_ 500 DSMSS_DrvSelMd0Pn 250;
BA_REL_ "GenSigSuprvResp" BU_SG_REL_ RDCM_HS SG_ 500 DSMSS_DrvSelMd0Pn 1;
BA_REL_ "GenSigTimeoutMsg" BU_SG_REL_ RDCM_HS SG_ 500 DSMSS_DrvSelMd0Pn 500;
BA_REL_ "GenSigTimeoutTime" BU_SG_REL_ RDCM_HS SG_ 500 DSMSS_DrvSelMd0Pn 250;
BA_REL_ "GenSigSuprvResp" BU_SG_REL_ EBCM_OBD_HS SG_ 500 DSMSS_DrvSelMd8Pn 1;
BA_REL_ "GenSigTimeoutMsg" BU_SG_REL_ EBCM_OBD_HS SG_ 500 DSMSS_DrvSelMd8Pn 500;
BA_REL_ "GenSigTimeoutTime" BU_SG_REL_ EBCM_OBD_HS SG_ 500 DSMSS_DrvSelMd8Pn 250;
BA_REL_ "GenSigSuprvResp" BU_SG_REL_ EBCM_HS SG_ 500 DSMSS_DrvSelMd8Pn 1;
BA_REL_ "GenSigTimeoutMsg" BU_SG_REL_ EBCM_HS SG_ 500 DSMSS_DrvSelMd8Pn 500;
BA_REL_ "GenSigTimeoutTime" BU_SG_REL_ EBCM_HS SG_ 500 DSMSS_DrvSelMd8Pn 250;
BA_REL_ "GenSigSuprvResp" BU_SG_REL_ RDCM_HS SG_ 500 DSMSS_DrvSelMd8Pn 1;
BA_REL_ "GenSigTimeoutMsg" BU_SG_REL_ RDCM_HS SG_ 500 DSMSS_DrvSelMd8Pn 500;
BA_REL_ "GenSigTimeoutTime" BU_SG_REL_ RDCM_HS SG_ 500 DSMSS_DrvSelMd8Pn 250;
BA_REL_ "GenSigSuprvResp" BU_SG_REL_ EBCM_OBD_HS SG_ 500 DSMSS_DrvSelMd7Pn 1;
BA_REL_ "GenSigTimeoutMsg" BU_SG_REL_ EBCM_OBD_HS SG_ 500 DSMSS_DrvSelMd7Pn 500;
BA_REL_ "GenSigTimeoutTime" BU_SG_REL_ EBCM_OBD_HS SG_ 500 DSMSS_DrvSelMd7Pn 250;
BA_REL_ "GenSigSuprvResp" BU_SG_REL_ EBCM_HS SG_ 500 DSMSS_DrvSelMd7Pn 1;
BA_REL_ "GenSigTimeoutMsg" BU_SG_REL_ EBCM_HS SG_ 500 DSMSS_DrvSelMd7Pn 500;
BA_REL_ "GenSigTimeoutTime" BU_SG_REL_ EBCM_HS SG_ 500 DSMSS_DrvSelMd7Pn 250;
BA_REL_ "GenSigSuprvResp" BU_SG_REL_ RDCM_HS SG_ 500 DSMSS_DrvSelMd7Pn 1;
BA_REL_ "GenSigTimeoutMsg" BU_SG_REL_ RDCM_HS SG_ 500 DSMSS_DrvSelMd7Pn 500;
BA_REL_ "GenSigTimeoutTime" BU_SG_REL_ RDCM_HS SG_ 500 DSMSS_DrvSelMd7Pn 250;
BA_REL_ "GenSigSuprvResp" BU_SG_REL_ EBCM_OBD_HS SG_ 500 DSMSS_DrvSelMd6Pn 1;
BA_REL_ "GenSigTimeoutMsg" BU_SG_REL_ EBCM_OBD_HS SG_ 500 DSMSS_DrvSelMd6Pn 500;
BA_REL_ "GenSigTimeoutTime" BU_SG_REL_ EBCM_OBD_HS SG_ 500 DSMSS_DrvSelMd6Pn 250;
BA_REL_ "GenSigSuprvResp" BU_SG_REL_ EBCM_HS SG_ 500 DSMSS_DrvSelMd6Pn 1;
BA_REL_ "GenSigTimeoutMsg" BU_SG_REL_ EBCM_HS SG_ 500 DSMSS_DrvSelMd6Pn 500;
BA_REL_ "GenSigTimeoutTime" BU_SG_REL_ EBCM_HS SG_ 500 DSMSS_DrvSelMd6Pn 250;
BA_REL_ "GenSigSuprvResp" BU_SG_REL_ RDCM_HS SG_ 500 DSMSS_DrvSelMd6Pn 1;
BA_REL_ "GenSigTimeoutMsg" BU_SG_REL_ RDCM_HS SG_ 500 DSMSS_DrvSelMd6Pn 500;
BA_REL_ "GenSigTimeoutTime" BU_SG_REL_ RDCM_HS SG_ 500 DSMSS_DrvSelMd6Pn 250;
BA_REL_ "GenSigSuprvResp" BU_SG_REL_ EBCM_OBD_HS SG_ 500 DSMSS_DrvSelMd5Pn 1;
BA_REL_ "GenSigTimeoutMsg" BU_SG_REL_ EBCM_OBD_HS SG_ 500 DSMSS_DrvSelMd5Pn 500;
BA_REL_ "GenSigTimeoutTime" BU_SG_REL_ EBCM_OBD_HS SG_ 500 DSMSS_DrvSelMd5Pn 250;
BA_REL_ "GenSigSuprvResp" BU_SG_REL_ EBCM_HS SG_ 500 DSMSS_DrvSelMd5Pn 1;
BA_REL_ "GenSigTimeoutMsg" BU_SG_REL_ EBCM_HS SG_ 500 DSMSS_DrvSelMd5Pn 500;
BA_REL_ "GenSigTimeoutTime" BU_SG_REL_ EBCM_HS SG_ 500 DSMSS_DrvSelMd5Pn 250;
BA_REL_ "GenSigSuprvResp" BU_SG_REL_ RDCM_HS SG_ 500 DSMSS_DrvSelMd5Pn 1;
BA_REL_ "GenSigTimeoutMsg" BU_SG_REL_ RDCM_HS SG_ 500 DSMSS_DrvSelMd5Pn 500;
BA_REL_ "GenSigTimeoutTime" BU_SG_REL_ RDCM_HS SG_ 500 DSMSS_DrvSelMd5Pn 250;
BA_REL_ "GenSigSuprvResp" BU_SG_REL_ EBCM_OBD_HS SG_ 500 DSMSS_DrvSelMd4Pn 1;
BA_REL_ "GenSigTimeoutMsg" BU_SG_REL_ EBCM_OBD_HS SG_ 500 DSMSS_DrvSelMd4Pn 500;
BA_REL_ "GenSigTimeoutTime" BU_SG_REL_ EBCM_OBD_HS SG_ 500 DSMSS_DrvSelMd4Pn 250;
BA_REL_ "GenSigSuprvResp" BU_SG_REL_ EBCM_HS SG_ 500 DSMSS_DrvSelMd4Pn 1;
BA_REL_ "GenSigTimeoutMsg" BU_SG_REL_ EBCM_HS SG_ 500 DSMSS_DrvSelMd4Pn 500;
BA_REL_ "GenSigTimeoutTime" BU_SG_REL_ EBCM_HS SG_ 500 DSMSS_DrvSelMd4Pn 250;
BA_REL_ "GenSigSuprvResp" BU_SG_REL_ RDCM_HS SG_ 500 DSMSS_DrvSelMd4Pn 1;
BA_REL_ "GenSigTimeoutMsg" BU_SG_REL_ RDCM_HS SG_ 500 DSMSS_DrvSelMd4Pn 500;
BA_REL_ "GenSigTimeoutTime" BU_SG_REL_ RDCM_HS SG_ 500 DSMSS_DrvSelMd4Pn 250;
BA_REL_ "GenSigSuprvResp" BU_SG_REL_ EBCM_OBD_HS SG_ 500 DSMSS_DrvSelMd3Pn 1;
BA_REL_ "GenSigTimeoutMsg" BU_SG_REL_ EBCM_OBD_HS SG_ 500 DSMSS_DrvSelMd3Pn 500;
BA_REL_ "GenSigTimeoutTime" BU_SG_REL_ EBCM_OBD_HS SG_ 500 DSMSS_DrvSelMd3Pn 250;
BA_REL_ "GenSigSuprvResp" BU_SG_REL_ EBCM_HS SG_ 500 DSMSS_DrvSelMd3Pn 1;
BA_REL_ "GenSigTimeoutMsg" BU_SG_REL_ EBCM_HS SG_ 500 DSMSS_DrvSelMd3Pn 500;
BA_REL_ "GenSigTimeoutTime" BU_SG_REL_ EBCM_HS SG_ 500 DSMSS_DrvSelMd3Pn 250;
BA_REL_ "GenSigSuprvResp" BU_SG_REL_ RDCM_HS SG_ 500 DSMSS_DrvSelMd3Pn 1;
BA_REL_ "GenSigTimeoutMsg" BU_SG_REL_ RDCM_HS SG_ 500 DSMSS_DrvSelMd3Pn 500;
BA_REL_ "GenSigTimeoutTime" BU_SG_REL_ RDCM_HS SG_ 500 DSMSS_DrvSelMd3Pn 250;
BA_REL_ "GenSigSuprvResp" BU_SG_REL_ EBCM_OBD_HS SG_ 500 DSMSS_DrvSelMd2Pn 1;
BA_REL_ "GenSigTimeoutMsg" BU_SG_REL_ EBCM_OBD_HS SG_ 500 DSMSS_DrvSelMd2Pn 500;
BA_REL_ "GenSigTimeoutTime" BU_SG_REL_ EBCM_OBD_HS SG_ 500 DSMSS_DrvSelMd2Pn 250;
BA_REL_ "GenSigSuprvResp" BU_SG_REL_ EBCM_HS SG_ 500 DSMSS_DrvSelMd2Pn 1;
BA_REL_ "GenSigTimeoutMsg" BU_SG_REL_ EBCM_HS SG_ 500 DSMSS_DrvSelMd2Pn 500;
BA_REL_ "GenSigTimeoutTime" BU_SG_REL_ EBCM_HS SG_ 500 DSMSS_DrvSelMd2Pn 250;
BA_REL_ "GenSigSuprvResp" BU_SG_REL_ RDCM_HS SG_ 500 DSMSS_DrvSelMd2Pn 1;
BA_REL_ "GenSigTimeoutMsg" BU_SG_REL_ RDCM_HS SG_ 500 DSMSS_DrvSelMd2Pn 500;
BA_REL_ "GenSigTimeoutTime" BU_SG_REL_ RDCM_HS SG_ 500 DSMSS_DrvSelMd2Pn 250;
BA_REL_ "GenSigSuprvResp" BU_SG_REL_ EBCM_OBD_HS SG_ 500 DSMSS_DrvSelMd1Pn 1;
BA_REL_ "GenSigTimeoutMsg" BU_SG_REL_ EBCM_OBD_HS SG_ 500 DSMSS_DrvSelMd1Pn 500;
BA_REL_ "GenSigTimeoutTime" BU_SG_REL_ EBCM_OBD_HS SG_ 500 DSMSS_DrvSelMd1Pn 250;
BA_REL_ "GenSigSuprvResp" BU_SG_REL_ EBCM_HS SG_ 500 DSMSS_DrvSelMd1Pn 1;
BA_REL_ "GenSigTimeoutMsg" BU_SG_REL_ EBCM_HS SG_ 500 DSMSS_DrvSelMd1Pn 500;
BA_REL_ "GenSigTimeoutTime" BU_SG_REL_ EBCM_HS SG_ 500 DSMSS_DrvSelMd1Pn 250;
BA_REL_ "GenSigSuprvResp" BU_SG_REL_ RDCM_HS SG_ 500 DSMSS_DrvSelMd1Pn 1;
BA_REL_ "GenSigTimeoutMsg" BU_SG_REL_ RDCM_HS SG_ 500 DSMSS_DrvSelMd1Pn 500;
BA_REL_ "GenSigTimeoutTime" BU_SG_REL_ RDCM_HS SG_ 500 DSMSS_DrvSelMd1Pn 250;
BA_REL_ "GenSigSuprvResp" BU_SG_REL_ EBCM_OBD_HS SG_ 500 DSMSS_DrvSelMd8Un 1;
BA_REL_ "GenSigTimeoutMsg" BU_SG_REL_ EBCM_OBD_HS SG_ 500 DSMSS_DrvSelMd8Un 500;
BA_REL_ "GenSigTimeoutTime" BU_SG_REL_ EBCM_OBD_HS SG_ 500 DSMSS_DrvSelMd8Un 250;
BA_REL_ "GenSigSuprvResp" BU_SG_REL_ EBCM_HS SG_ 500 DSMSS_DrvSelMd8Un 1;
BA_REL_ "GenSigTimeoutMsg" BU_SG_REL_ EBCM_HS SG_ 500 DSMSS_DrvSelMd8Un 500;
BA_REL_ "GenSigTimeoutTime" BU_SG_REL_ EBCM_HS SG_ 500 DSMSS_DrvSelMd8Un 250;
BA_REL_ "GenSigSuprvResp" BU_SG_REL_ RDCM_HS SG_ 500 DSMSS_DrvSelMd8Un 1;
BA_REL_ "GenSigTimeoutMsg" BU_SG_REL_ RDCM_HS SG_ 500 DSMSS_DrvSelMd8Un 500;
BA_REL_ "GenSigTimeoutTime" BU_SG_REL_ RDCM_HS SG_ 500 DSMSS_DrvSelMd8Un 250;
BA_REL_ "GenSigSuprvResp" BU_SG_REL_ EBCM_OBD_HS SG_ 500 DSMSS_DrvSelMd7Un 1;
BA_REL_ "GenSigTimeoutMsg" BU_SG_REL_ EBCM_OBD_HS SG_ 500 DSMSS_DrvSelMd7Un 500;
BA_REL_ "GenSigTimeoutTime" BU_SG_REL_ EBCM_OBD_HS SG_ 500 DSMSS_DrvSelMd7Un 250;
BA_REL_ "GenSigSuprvResp" BU_SG_REL_ EBCM_HS SG_ 500 DSMSS_DrvSelMd7Un 1;
BA_REL_ "GenSigTimeoutMsg" BU_SG_REL_ EBCM_HS SG_ 500 DSMSS_DrvSelMd7Un 500;
BA_REL_ "GenSigTimeoutTime" BU_SG_REL_ EBCM_HS SG_ 500 DSMSS_DrvSelMd7Un 250;
BA_REL_ "GenSigSuprvResp" BU_SG_REL_ RDCM_HS SG_ 500 DSMSS_DrvSelMd7Un 1;
BA_REL_ "GenSigTimeoutMsg" BU_SG_REL_ RDCM_HS SG_ 500 DSMSS_DrvSelMd7Un 500;
BA_REL_ "GenSigTimeoutTime" BU_SG_REL_ RDCM_HS SG_ 500 DSMSS_DrvSelMd7Un 250;
BA_REL_ "GenSigSuprvResp" BU_SG_REL_ EBCM_OBD_HS SG_ 500 DSMSS_DrvSelMd6Un 1;
BA_REL_ "GenSigTimeoutMsg" BU_SG_REL_ EBCM_OBD_HS SG_ 500 DSMSS_DrvSelMd6Un 500;
BA_REL_ "GenSigTimeoutTime" BU_SG_REL_ EBCM_OBD_HS SG_ 500 DSMSS_DrvSelMd6Un 250;
BA_REL_ "GenSigSuprvResp" BU_SG_REL_ EBCM_HS SG_ 500 DSMSS_DrvSelMd6Un 1;
BA_REL_ "GenSigTimeoutMsg" BU_SG_REL_ EBCM_HS SG_ 500 DSMSS_DrvSelMd6Un 500;
BA_REL_ "GenSigTimeoutTime" BU_SG_REL_ EBCM_HS SG_ 500 DSMSS_DrvSelMd6Un 250;
BA_REL_ "GenSigSuprvResp" BU_SG_REL_ RDCM_HS SG_ 500 DSMSS_DrvSelMd6Un 1;
BA_REL_ "GenSigTimeoutMsg" BU_SG_REL_ RDCM_HS SG_ 500 DSMSS_DrvSelMd6Un 500;
BA_REL_ "GenSigTimeoutTime" BU_SG_REL_ RDCM_HS SG_ 500 DSMSS_DrvSelMd6Un 250;
BA_REL_ "GenSigSuprvResp" BU_SG_REL_ EBCM_OBD_HS SG_ 500 DSMSS_DrvSelMd5Un 1;
BA_REL_ "GenSigTimeoutMsg" BU_SG_REL_ EBCM_OBD_HS SG_ 500 DSMSS_DrvSelMd5Un 500;
BA_REL_ "GenSigTimeoutTime" BU_SG_REL_ EBCM_OBD_HS SG_ 500 DSMSS_DrvSelMd5Un 250;
BA_REL_ "GenSigSuprvResp" BU_SG_REL_ EBCM_HS SG_ 500 DSMSS_DrvSelMd5Un 1;
BA_REL_ "GenSigTimeoutMsg" BU_SG_REL_ EBCM_HS SG_ 500 DSMSS_DrvSelMd5Un 500;
BA_REL_ "GenSigTimeoutTime" BU_SG_REL_ EBCM_HS SG_ 500 DSMSS_DrvSelMd5Un 250;
BA_REL_ "GenSigSuprvResp" BU_SG_REL_ RDCM_HS SG_ 500 DSMSS_DrvSelMd5Un 1;
BA_REL_ "GenSigTimeoutMsg" BU_SG_REL_ RDCM_HS SG_ 500 DSMSS_DrvSelMd5Un 500;
BA_REL_ "GenSigTimeoutTime" BU_SG_REL_ RDCM_HS SG_ 500 DSMSS_DrvSelMd5Un 250;
BA_REL_ "GenSigSuprvResp" BU_SG_REL_ EBCM_OBD_HS SG_ 500 DSMSS_DrvSelMd4Un 1;
BA_REL_ "GenSigTimeoutMsg" BU_SG_REL_ EBCM_OBD_HS SG_ 500 DSMSS_DrvSelMd4Un 500;
BA_REL_ "GenSigTimeoutTime" BU_SG_REL_ EBCM_OBD_HS SG_ 500 DSMSS_DrvSelMd4Un 250;
BA_REL_ "GenSigSuprvResp" BU_SG_REL_ EBCM_HS SG_ 500 DSMSS_DrvSelMd4Un 1;
BA_REL_ "GenSigTimeoutMsg" BU_SG_REL_ EBCM_HS SG_ 500 DSMSS_DrvSelMd4Un 500;
BA_REL_ "GenSigTimeoutTime" BU_SG_REL_ EBCM_HS SG_ 500 DSMSS_DrvSelMd4Un 250;
BA_REL_ "GenSigSuprvResp" BU_SG_REL_ RDCM_HS SG_ 500 DSMSS_DrvSelMd4Un 1;
BA_REL_ "GenSigTimeoutMsg" BU_SG_REL_ RDCM_HS SG_ 500 DSMSS_DrvSelMd4Un 500;
BA_REL_ "GenSigTimeoutTime" BU_SG_REL_ RDCM_HS SG_ 500 DSMSS_DrvSelMd4Un 250;
BA_REL_ "GenSigSuprvResp" BU_SG_REL_ EBCM_OBD_HS SG_ 500 DSMSS_DrvSelMd3Un 1;
BA_REL_ "GenSigTimeoutMsg" BU_SG_REL_ EBCM_OBD_HS SG_ 500 DSMSS_DrvSelMd3Un 500;
BA_REL_ "GenSigTimeoutTime" BU_SG_REL_ EBCM_OBD_HS SG_ 500 DSMSS_DrvSelMd3Un 250;
BA_REL_ "GenSigSuprvResp" BU_SG_REL_ EBCM_HS SG_ 500 DSMSS_DrvSelMd3Un 1;
BA_REL_ "GenSigTimeoutMsg" BU_SG_REL_ EBCM_HS SG_ 500 DSMSS_DrvSelMd3Un 500;
BA_REL_ "GenSigTimeoutTime" BU_SG_REL_ EBCM_HS SG_ 500 DSMSS_DrvSelMd3Un 250;
BA_REL_ "GenSigSuprvResp" BU_SG_REL_ RDCM_HS SG_ 500 DSMSS_DrvSelMd3Un 1;
BA_REL_ "GenSigTimeoutMsg" BU_SG_REL_ RDCM_HS SG_ 500 DSMSS_DrvSelMd3Un 500;
BA_REL_ "GenSigTimeoutTime" BU_SG_REL_ RDCM_HS SG_ 500 DSMSS_DrvSelMd3Un 250;
BA_REL_ "GenSigSuprvResp" BU_SG_REL_ EBCM_OBD_HS SG_ 500 DSMSS_DrvSelMd2Un 1;
BA_REL_ "GenSigTimeoutMsg" BU_SG_REL_ EBCM_OBD_HS SG_ 500 DSMSS_DrvSelMd2Un 500;
BA_REL_ "GenSigTimeoutTime" BU_SG_REL_ EBCM_OBD_HS SG_ 500 DSMSS_DrvSelMd2Un 250;
BA_REL_ "GenSigSuprvResp" BU_SG_REL_ EBCM_HS SG_ 500 DSMSS_DrvSelMd2Un 1;
BA_REL_ "GenSigTimeoutMsg" BU_SG_REL_ EBCM_HS SG_ 500 DSMSS_DrvSelMd2Un 500;
BA_REL_ "GenSigTimeoutTime" BU_SG_REL_ EBCM_HS SG_ 500 DSMSS_DrvSelMd2Un 250;
BA_REL_ "GenSigSuprvResp" BU_SG_REL_ RDCM_HS SG_ 500 DSMSS_DrvSelMd2Un 1;
BA_REL_ "GenSigTimeoutMsg" BU_SG_REL_ RDCM_HS SG_ 500 DSMSS_DrvSelMd2Un 500;
BA_REL_ "GenSigTimeoutTime" BU_SG_REL_ RDCM_HS SG_ 500 DSMSS_DrvSelMd2Un 250;
BA_REL_ "GenSigSuprvResp" BU_SG_REL_ EBCM_OBD_HS SG_ 500 DSMSS_DrvSelMd1Un 1;
BA_REL_ "GenSigTimeoutMsg" BU_SG_REL_ EBCM_OBD_HS SG_ 500 DSMSS_DrvSelMd1Un 500;
BA_REL_ "GenSigTimeoutTime" BU_SG_REL_ EBCM_OBD_HS SG_ 500 DSMSS_DrvSelMd1Un 250;
BA_REL_ "GenSigSuprvResp" BU_SG_REL_ EBCM_HS SG_ 500 DSMSS_DrvSelMd1Un 1;
BA_REL_ "GenSigTimeoutMsg" BU_SG_REL_ EBCM_HS SG_ 500 DSMSS_DrvSelMd1Un 500;
BA_REL_ "GenSigTimeoutTime" BU_SG_REL_ EBCM_HS SG_ 500 DSMSS_DrvSelMd1Un 250;
BA_REL_ "GenSigSuprvResp" BU_SG_REL_ RDCM_HS SG_ 500 DSMSS_DrvSelMd1Un 1;
BA_REL_ "GenSigTimeoutMsg" BU_SG_REL_ RDCM_HS SG_ 500 DSMSS_DrvSelMd1Un 500;
BA_REL_ "GenSigTimeoutTime" BU_SG_REL_ RDCM_HS SG_ 500 DSMSS_DrvSelMd1Un 250;
BA_REL_ "GenSigSuprvResp" BU_SG_REL_ RDCM_HS SG_ 500 DrvSelMd1ReqDnd 1;
BA_REL_ "GenSigTimeoutMsg" BU_SG_REL_ RDCM_HS SG_ 500 DrvSelMd1ReqDnd 500;
BA_REL_ "GenSigTimeoutTime" BU_SG_REL_ RDCM_HS SG_ 500 DrvSelMd1ReqDnd 250;
BA_REL_ "GenSigSuprvResp" BU_SG_REL_ RDCM_HS SG_ 500 DrvSelMd1Stat 1;
BA_REL_ "GenSigTimeoutMsg" BU_SG_REL_ RDCM_HS SG_ 500 DrvSelMd1Stat 500;
BA_REL_ "GenSigTimeoutTime" BU_SG_REL_ RDCM_HS SG_ 500 DrvSelMd1Stat 250;
BA_REL_ "GenSigSuprvResp" BU_SG_REL_ SADS_HS SG_ 500 DrvSelMd1Stat 1;
BA_REL_ "GenSigTimeoutMsg" BU_SG_REL_ SADS_HS SG_ 500 DrvSelMd1Stat 500;
BA_REL_ "GenSigTimeoutTime" BU_SG_REL_ SADS_HS SG_ 500 DrvSelMd1Stat 250;
BA_REL_ "GenSigSuprvResp" BU_SG_REL_ EBCM_OBD_HS SG_ 500 DrvSelMd1Stat 1;
BA_REL_ "GenSigTimeoutMsg" BU_SG_REL_ EBCM_OBD_HS SG_ 500 DrvSelMd1Stat 500;
BA_REL_ "GenSigTimeoutTime" BU_SG_REL_ EBCM_OBD_HS SG_ 500 DrvSelMd1Stat 250;
BA_REL_ "GenSigSuprvResp" BU_SG_REL_ EBCM_HS SG_ 500 DrvSelMd1Stat 1;
BA_REL_ "GenSigTimeoutMsg" BU_SG_REL_ EBCM_HS SG_ 500 DrvSelMd1Stat 500;
BA_REL_ "GenSigTimeoutTime" BU_SG_REL_ EBCM_HS SG_ 500 DrvSelMd1Stat 250;
BA_REL_ "GenSigSuprvResp" BU_SG_REL_ TCM_HS SG_ 1417 PrplsnTrqRelCap 1;
BA_REL_ "GenSigTimeoutMsg" BU_SG_REL_ TCM_HS SG_ 1417 PrplsnTrqRelCap 1417;
BA_REL_ "GenSigTimeoutTime" BU_SG_REL_ TCM_HS SG_ 1417 PrplsnTrqRelCap 1250;
BA_REL_ "GenSigSuprvResp" BU_SG_REL_ HCP_B_HS SG_ 1417 ETC_MinTorq 1;
BA_REL_ "GenSigTimeoutMsg" BU_SG_REL_ HCP_B_HS SG_ 1417 ETC_MinTorq 1417;
BA_REL_ "GenSigTimeoutTime" BU_SG_REL_ HCP_B_HS SG_ 1417 ETC_MinTorq 1250;
BA_REL_ "GenSigSuprvResp" BU_SG_REL_ HCP_T_HS SG_ 1417 ETC_MinTorq 1;
BA_REL_ "GenSigTimeoutMsg" BU_SG_REL_ HCP_T_HS SG_ 1417 ETC_MinTorq 1417;
BA_REL_ "GenSigTimeoutTime" BU_SG_REL_ HCP_T_HS SG_ 1417 ETC_MinTorq 1250;
BA_REL_ "GenSigSuprvResp" BU_SG_REL_ HCP_T_HS SG_ 1417 ETC_MinTorq 1;
BA_REL_ "GenSigTimeoutMsg" BU_SG_REL_ HCP_T_HS SG_ 1417 ETC_MinTorq 1417;
BA_REL_ "GenSigTimeoutTime" BU_SG_REL_ HCP_T_HS SG_ 1417 ETC_MinTorq 1250;
BA_REL_ "GenSigSuprvResp" BU_SG_REL_ HCP_B_HS SG_ 1417 ETC_MinRunTorq 1;
BA_REL_ "GenSigTimeoutMsg" BU_SG_REL_ HCP_B_HS SG_ 1417 ETC_MinRunTorq 1417;
BA_REL_ "GenSigTimeoutTime" BU_SG_REL_ HCP_B_HS SG_ 1417 ETC_MinRunTorq 1250;
BA_REL_ "GenSigSuprvResp" BU_SG_REL_ HCP_T_HS SG_ 1417 ETC_MinRunTorq 1;
BA_REL_ "GenSigTimeoutMsg" BU_SG_REL_ HCP_T_HS SG_ 1417 ETC_MinRunTorq 1417;
BA_REL_ "GenSigTimeoutTime" BU_SG_REL_ HCP_T_HS SG_ 1417 ETC_MinRunTorq 1250;
BA_REL_ "GenSigSuprvResp" BU_SG_REL_ HCP_T_HS SG_ 1417 ETC_MinRunTorq 1;
BA_REL_ "GenSigTimeoutMsg" BU_SG_REL_ HCP_T_HS SG_ 1417 ETC_MinRunTorq 1417;
BA_REL_ "GenSigTimeoutTime" BU_SG_REL_ HCP_T_HS SG_ 1417 ETC_MinRunTorq 1250;
BA_REL_ "GenSigSuprvResp" BU_SG_REL_ HCP_B_HS SG_ 1417 ETC_MaxTorq 1;
BA_REL_ "GenSigTimeoutMsg" BU_SG_REL_ HCP_B_HS SG_ 1417 ETC_MaxTorq 1417;
BA_REL_ "GenSigTimeoutTime" BU_SG_REL_ HCP_B_HS SG_ 1417 ETC_MaxTorq 1250;
BA_REL_ "GenSigSuprvResp" BU_SG_REL_ HCP_T_HS SG_ 1417 ETC_MaxTorq 1;
BA_REL_ "GenSigTimeoutMsg" BU_SG_REL_ HCP_T_HS SG_ 1417 ETC_MaxTorq 1417;
BA_REL_ "GenSigTimeoutTime" BU_SG_REL_ HCP_T_HS SG_ 1417 ETC_MaxTorq 1250;
BA_REL_ "GenSigSuprvResp" BU_SG_REL_ HCP_T_HS SG_ 1417 ETC_MaxTorq 1;
BA_REL_ "GenSigTimeoutMsg" BU_SG_REL_ HCP_T_HS SG_ 1417 ETC_MaxTorq 1417;
BA_REL_ "GenSigTimeoutTime" BU_SG_REL_ HCP_T_HS SG_ 1417 ETC_MaxTorq 1250;
BA_REL_ "GenSigSuprvResp" BU_SG_REL_ HCP_B_HS SG_ 1417 ETC_RefEngSpd 1;
BA_REL_ "GenSigTimeoutMsg" BU_SG_REL_ HCP_B_HS SG_ 1417 ETC_RefEngSpd 1417;
BA_REL_ "GenSigTimeoutTime" BU_SG_REL_ HCP_B_HS SG_ 1417 ETC_RefEngSpd 1250;
BA_REL_ "GenSigSuprvResp" BU_SG_REL_ HCP_T_HS SG_ 1417 ETC_RefEngSpd 1;
BA_REL_ "GenSigTimeoutMsg" BU_SG_REL_ HCP_T_HS SG_ 1417 ETC_RefEngSpd 1417;
BA_REL_ "GenSigTimeoutTime" BU_SG_REL_ HCP_T_HS SG_ 1417 ETC_RefEngSpd 1250;
BA_REL_ "GenSigSuprvResp" BU_SG_REL_ HCP_T_HS SG_ 1417 ETC_RefEngSpd 1;
BA_REL_ "GenSigTimeoutMsg" BU_SG_REL_ HCP_T_HS SG_ 1417 ETC_RefEngSpd 1417;
BA_REL_ "GenSigTimeoutTime" BU_SG_REL_ HCP_T_HS SG_ 1417 ETC_RefEngSpd 1250;
BA_REL_ "GenSigSuprvResp" BU_SG_REL_ HCP_B_HS SG_ 1417 ETC_UnsdRsrvd 1;
BA_REL_ "GenSigTimeoutMsg" BU_SG_REL_ HCP_B_HS SG_ 1417 ETC_UnsdRsrvd 1417;
BA_REL_ "GenSigTimeoutTime" BU_SG_REL_ HCP_B_HS SG_ 1417 ETC_UnsdRsrvd 1250;
BA_REL_ "GenSigSuprvResp" BU_SG_REL_ HCP_T_HS SG_ 1417 ETC_UnsdRsrvd 1;
BA_REL_ "GenSigTimeoutMsg" BU_SG_REL_ HCP_T_HS SG_ 1417 ETC_UnsdRsrvd 1417;
BA_REL_ "GenSigTimeoutTime" BU_SG_REL_ HCP_T_HS SG_ 1417 ETC_UnsdRsrvd 1250;
BA_REL_ "GenSigSuprvResp" BU_SG_REL_ HCP_T_HS SG_ 1417 ETC_UnsdRsrvd 1;
BA_REL_ "GenSigTimeoutMsg" BU_SG_REL_ HCP_T_HS SG_ 1417 ETC_UnsdRsrvd 1417;
BA_REL_ "GenSigTimeoutTime" BU_SG_REL_ HCP_T_HS SG_ 1417 ETC_UnsdRsrvd 1250;
BA_REL_ "GenSigSuprvResp" BU_SG_REL_ HCP_B_HS SG_ 1417 ETC_FrmCntr 1;
BA_REL_ "GenSigTimeoutMsg" BU_SG_REL_ HCP_B_HS SG_ 1417 ETC_FrmCntr 1417;
BA_REL_ "GenSigTimeoutTime" BU_SG_REL_ HCP_B_HS SG_ 1417 ETC_FrmCntr 1250;
BA_REL_ "GenSigSuprvResp" BU_SG_REL_ HCP_T_HS SG_ 1417 ETC_FrmCntr 1;
BA_REL_ "GenSigTimeoutMsg" BU_SG_REL_ HCP_T_HS SG_ 1417 ETC_FrmCntr 1417;
BA_REL_ "GenSigTimeoutTime" BU_SG_REL_ HCP_T_HS SG_ 1417 ETC_FrmCntr 1250;
BA_REL_ "GenSigSuprvResp" BU_SG_REL_ HCP_T_HS SG_ 1417 ETC_FrmCntr 1;
BA_REL_ "GenSigTimeoutMsg" BU_SG_REL_ HCP_T_HS SG_ 1417 ETC_FrmCntr 1417;
BA_REL_ "GenSigTimeoutTime" BU_SG_REL_ HCP_T_HS SG_ 1417 ETC_FrmCntr 1250;
BA_REL_ "GenSigSuprvResp" BU_SG_REL_ HCP_B_HS SG_ 1417 ETC_EngOpMd 1;
BA_REL_ "GenSigTimeoutMsg" BU_SG_REL_ HCP_B_HS SG_ 1417 ETC_EngOpMd 1417;
BA_REL_ "GenSigTimeoutTime" BU_SG_REL_ HCP_B_HS SG_ 1417 ETC_EngOpMd 1250;
BA_REL_ "GenSigSuprvResp" BU_SG_REL_ HCP_T_HS SG_ 1417 ETC_EngOpMd 1;
BA_REL_ "GenSigTimeoutMsg" BU_SG_REL_ HCP_T_HS SG_ 1417 ETC_EngOpMd 1417;
BA_REL_ "GenSigTimeoutTime" BU_SG_REL_ HCP_T_HS SG_ 1417 ETC_EngOpMd 1250;
BA_REL_ "GenSigSuprvResp" BU_SG_REL_ HCP_T_HS SG_ 1417 ETC_EngOpMd 1;
BA_REL_ "GenSigTimeoutMsg" BU_SG_REL_ HCP_T_HS SG_ 1417 ETC_EngOpMd 1417;
BA_REL_ "GenSigTimeoutTime" BU_SG_REL_ HCP_T_HS SG_ 1417 ETC_EngOpMd 1250;
BA_REL_ "GenSigSuprvResp" BU_SG_REL_ ICCM_HS SG_ 407 TEPI_TrnsEngdPrFlwStV 1;
BA_REL_ "GenSigTimeoutMsg" BU_SG_REL_ ICCM_HS SG_ 407 TEPI_TrnsEngdPrFlwStV 407;
BA_REL_ "GenSigTimeoutTime" BU_SG_REL_ ICCM_HS SG_ 407 TEPI_TrnsEngdPrFlwStV 250;
BA_REL_ "GenSigSuprvResp" BU_SG_REL_ ICCM_HS SG_ 407 TEPI_TrnsEngdPrFlwSt 1;
BA_REL_ "GenSigTimeoutMsg" BU_SG_REL_ ICCM_HS SG_ 407 TEPI_TrnsEngdPrFlwSt 407;
BA_REL_ "GenSigTimeoutTime" BU_SG_REL_ ICCM_HS SG_ 407 TEPI_TrnsEngdPrFlwSt 250;
BA_REL_ "GenSigSuprvResp" BU_SG_REL_ ECM_HS SG_ 407 TransRatio 1;
BA_REL_ "GenSigTimeoutMsg" BU_SG_REL_ ECM_HS SG_ 407 TransRatio 407;
BA_REL_ "GenSigTimeoutTime" BU_SG_REL_ ECM_HS SG_ 407 TransRatio 250;
BA_REL_ "GenSigSuprvResp" BU_SG_REL_ ECM_HS SG_ 189 HybDisengCruzCmnd 1;
BA_REL_ "GenSigTimeoutMsg" BU_SG_REL_ ECM_HS SG_ 189 HybDisengCruzCmnd 189;
BA_REL_ "GenSigTimeoutTime" BU_SG_REL_ ECM_HS SG_ 189 HybDisengCruzCmnd 250;
BA_REL_ "GenSigSuprvResp" BU_SG_REL_ ECM_HS SG_ 188 TransDirctnSt 1;
BA_REL_ "GenSigTimeoutMsg" BU_SG_REL_ ECM_HS SG_ 188 TransDirctnSt 188;
BA_REL_ "GenSigTimeoutTime" BU_SG_REL_ ECM_HS SG_ 188 TransDirctnSt 250;
BA_REL_ "GenSigSuprvResp" BU_SG_REL_ HCP_T_HS SG_ 170 EngCommFlrRedPwrCm 1;
BA_REL_ "GenSigTimeoutMsg" BU_SG_REL_ HCP_T_HS SG_ 170 EngCommFlrRedPwrCm 170;
BA_REL_ "GenSigTimeoutTime" BU_SG_REL_ HCP_T_HS SG_ 170 EngCommFlrRedPwrCm 250;
BA_REL_ "GenSigSuprvResp" BU_SG_REL_ HCP_T_HS SG_ 170 EngCommFlrRedPwrCm 1;
BA_REL_ "GenSigTimeoutMsg" BU_SG_REL_ HCP_T_HS SG_ 170 EngCommFlrRedPwrCm 170;
BA_REL_ "GenSigTimeoutTime" BU_SG_REL_ HCP_T_HS SG_ 170 EngCommFlrRedPwrCm 250;
BA_REL_ "GenSigSuprvResp" BU_SG_REL_ HCP_T_HS SG_ 170 CmndAxlTrqARC 1;
BA_REL_ "GenSigTimeoutMsg" BU_SG_REL_ HCP_T_HS SG_ 170 CmndAxlTrqARC 170;
BA_REL_ "GenSigTimeoutTime" BU_SG_REL_ HCP_T_HS SG_ 170 CmndAxlTrqARC 250;
BA_REL_ "GenSigSuprvResp" BU_SG_REL_ HCP_T_HS SG_ 170 CmndAxlTrqRespTyp 1;
BA_REL_ "GenSigTimeoutMsg" BU_SG_REL_ HCP_T_HS SG_ 170 CmndAxlTrqRespTyp 170;
BA_REL_ "GenSigTimeoutTime" BU_SG_REL_ HCP_T_HS SG_ 170 CmndAxlTrqRespTyp 250;
BA_REL_ "GenSigSuprvResp" BU_SG_REL_ HCP_T_HS SG_ 170 CmndAxlTrqImm 1;
BA_REL_ "GenSigTimeoutMsg" BU_SG_REL_ HCP_T_HS SG_ 170 CmndAxlTrqImm 170;
BA_REL_ "GenSigTimeoutTime" BU_SG_REL_ HCP_T_HS SG_ 170 CmndAxlTrqImm 250;
BA_REL_ "GenSigSuprvResp" BU_SG_REL_ HCP_B_HS SG_ 170 AccPos 1;
BA_REL_ "GenSigTimeoutMsg" BU_SG_REL_ HCP_B_HS SG_ 170 AccPos 170;
BA_REL_ "GenSigTimeoutTime" BU_SG_REL_ HCP_B_HS SG_ 170 AccPos 250;
BA_REL_ "GenSigSuprvResp" BU_SG_REL_ HCP_T_HS SG_ 170 AccPos 1;
BA_REL_ "GenSigTimeoutMsg" BU_SG_REL_ HCP_T_HS SG_ 170 AccPos 170;
BA_REL_ "GenSigTimeoutTime" BU_SG_REL_ HCP_T_HS SG_ 170 AccPos 250;
BA_REL_ "GenSigSuprvResp" BU_SG_REL_ TCM_HS SG_ 170 AccPos 1;
BA_REL_ "GenSigTimeoutMsg" BU_SG_REL_ TCM_HS SG_ 170 AccPos 170;
BA_REL_ "GenSigTimeoutTime" BU_SG_REL_ TCM_HS SG_ 170 AccPos 250;
BA_REL_ "GenSigSuprvResp" BU_SG_REL_ HCP_B_HS SG_ 170 CmndAxlTrqPredct 1;
BA_REL_ "GenSigTimeoutMsg" BU_SG_REL_ HCP_B_HS SG_ 170 CmndAxlTrqPredct 170;
BA_REL_ "GenSigTimeoutTime" BU_SG_REL_ HCP_B_HS SG_ 170 CmndAxlTrqPredct 250;
BA_REL_ "GenSigSuprvResp" BU_SG_REL_ HCP_T_HS SG_ 170 CmndAxlTrqPredct 1;
BA_REL_ "GenSigTimeoutMsg" BU_SG_REL_ HCP_T_HS SG_ 170 CmndAxlTrqPredct 170;
BA_REL_ "GenSigTimeoutTime" BU_SG_REL_ HCP_T_HS SG_ 170 CmndAxlTrqPredct 250;
BA_REL_ "GenSigSuprvResp" BU_SG_REL_ HCP_T_HS SG_ 170 CmndAxlTrqPredctProtVal 1;
BA_REL_ "GenSigTimeoutMsg" BU_SG_REL_ HCP_T_HS SG_ 170 CmndAxlTrqPredctProtVal 170;
BA_REL_ "GenSigTimeoutTime" BU_SG_REL_ HCP_T_HS SG_ 170 CmndAxlTrqPredctProtVal 250;
BA_REL_ "GenSigSuprvResp" BU_SG_REL_ EOCM_F_HS SG_ 1221 SpdLmtVsnFsdSpdUnt 1;
BA_REL_ "GenSigTimeoutMsg" BU_SG_REL_ EOCM_F_HS SG_ 1221 SpdLmtVsnFsdSpdUnt 1221;
BA_REL_ "GenSigTimeoutTime" BU_SG_REL_ EOCM_F_HS SG_ 1221 SpdLmtVsnFsdSpdUnt 1250;
BA_REL_ "GenSigSuprvResp" BU_SG_REL_ ACC_HS SG_ 1221 SpdLmtVsnFsdSpdUnt 1;
BA_REL_ "GenSigTimeoutMsg" BU_SG_REL_ ACC_HS SG_ 1221 SpdLmtVsnFsdSpdUnt 1221;
BA_REL_ "GenSigTimeoutTime" BU_SG_REL_ ACC_HS SG_ 1221 SpdLmtVsnFsdSpdUnt 1250;
BA_REL_ "GenSigSuprvResp" BU_SG_REL_ ECM_HS SG_ 1221 SpdLmtVsnFsdSpdUnt 1;
BA_REL_ "GenSigTimeoutMsg" BU_SG_REL_ ECM_HS SG_ 1221 SpdLmtVsnFsdSpdUnt 1221;
BA_REL_ "GenSigTimeoutTime" BU_SG_REL_ ECM_HS SG_ 1221 SpdLmtVsnFsdSpdUnt 1250;
BA_REL_ "GenSigSuprvResp" BU_SG_REL_ EOCM_F_HS SG_ 1221 SpdLmtVnFsSpdNwDet 1;
BA_REL_ "GenSigTimeoutMsg" BU_SG_REL_ EOCM_F_HS SG_ 1221 SpdLmtVnFsSpdNwDet 1221;
BA_REL_ "GenSigTimeoutTime" BU_SG_REL_ EOCM_F_HS SG_ 1221 SpdLmtVnFsSpdNwDet 1250;
BA_REL_ "GenSigSuprvResp" BU_SG_REL_ ACC_HS SG_ 1221 SpdLmtVnFsSpdNwDet 1;
BA_REL_ "GenSigTimeoutMsg" BU_SG_REL_ ACC_HS SG_ 1221 SpdLmtVnFsSpdNwDet 1221;
BA_REL_ "GenSigTimeoutTime" BU_SG_REL_ ACC_HS SG_ 1221 SpdLmtVnFsSpdNwDet 1250;
BA_REL_ "GenSigSuprvResp" BU_SG_REL_ ECM_HS SG_ 1221 SpdLmtVnFsSpdNwDet 1;
BA_REL_ "GenSigTimeoutMsg" BU_SG_REL_ ECM_HS SG_ 1221 SpdLmtVnFsSpdNwDet 1221;
BA_REL_ "GenSigTimeoutTime" BU_SG_REL_ ECM_HS SG_ 1221 SpdLmtVnFsSpdNwDet 1250;
BA_REL_ "GenSigSuprvResp" BU_SG_REL_ EOCM_F_HS SG_ 1221 SpdLmtVsnFsdSpd 1;
BA_REL_ "GenSigTimeoutMsg" BU_SG_REL_ EOCM_F_HS SG_ 1221 SpdLmtVsnFsdSpd 1221;
BA_REL_ "GenSigTimeoutTime" BU_SG_REL_ EOCM_F_HS SG_ 1221 SpdLmtVsnFsdSpd 1250;
BA_REL_ "GenSigSuprvResp" BU_SG_REL_ ACC_HS SG_ 1221 SpdLmtVsnFsdSpd 1;
BA_REL_ "GenSigTimeoutMsg" BU_SG_REL_ ACC_HS SG_ 1221 SpdLmtVsnFsdSpd 1221;
BA_REL_ "GenSigTimeoutTime" BU_SG_REL_ ACC_HS SG_ 1221 SpdLmtVsnFsdSpd 1250;
BA_REL_ "GenSigSuprvResp" BU_SG_REL_ ECM_HS SG_ 1221 SpdLmtVsnFsdSpd 1;
BA_REL_ "GenSigTimeoutMsg" BU_SG_REL_ ECM_HS SG_ 1221 SpdLmtVsnFsdSpd 1221;
BA_REL_ "GenSigTimeoutTime" BU_SG_REL_ ECM_HS SG_ 1221 SpdLmtVsnFsdSpd 1250;
BA_REL_ "GenSigSuprvResp" BU_SG_REL_ VICM2_HS SG_ 1221 CCClntCrcFlwRtReq 1;
BA_REL_ "GenSigTimeoutMsg" BU_SG_REL_ VICM2_HS SG_ 1221 CCClntCrcFlwRtReq 1221;
BA_REL_ "GenSigTimeoutTime" BU_SG_REL_ VICM2_HS SG_ 1221 CCClntCrcFlwRtReq 1250;
BA_REL_ "GenSigSuprvResp" BU_SG_REL_ ECM_HS SG_ 1243 CSERDTC_CdNum 1;
BA_REL_ "GenSigTimeoutMsg" BU_SG_REL_ ECM_HS SG_ 1243 CSERDTC_CdNum 1243;
BA_REL_ "GenSigTimeoutTime" BU_SG_REL_ ECM_HS SG_ 1243 CSERDTC_CdNum 1250;
BA_REL_ "GenSigSuprvResp" BU_SG_REL_ ECM_HS SG_ 1243 CSERDTC_SysDes 1;
BA_REL_ "GenSigTimeoutMsg" BU_SG_REL_ ECM_HS SG_ 1243 CSERDTC_SysDes 1243;
BA_REL_ "GenSigTimeoutTime" BU_SG_REL_ ECM_HS SG_ 1243 CSERDTC_SysDes 1250;
BA_REL_ "GenSigSuprvResp" BU_SG_REL_ ECM_HS SG_ 1243 ChsSysEmmRelMalfAct 1;
BA_REL_ "GenSigTimeoutMsg" BU_SG_REL_ ECM_HS SG_ 1243 ChsSysEmmRelMalfAct 1243;
BA_REL_ "GenSigTimeoutTime" BU_SG_REL_ ECM_HS SG_ 1243 ChsSysEmmRelMalfAct 1250;
BA_REL_ "GenSigSuprvResp" BU_SG_REL_ BCM_HS SG_ 979 SpdLmtrSttngTypAct 1;
BA_REL_ "GenSigTimeoutMsg" BU_SG_REL_ BCM_HS SG_ 979 SpdLmtrSttngTypAct 979;
BA_REL_ "GenSigTimeoutTime" BU_SG_REL_ BCM_HS SG_ 979 SpdLmtrSttngTypAct 250;
BA_REL_ "GenSigSuprvResp" BU_SG_REL_ BCM_HS SG_ 979 SetSpdLmtRchd 1;
BA_REL_ "GenSigTimeoutMsg" BU_SG_REL_ BCM_HS SG_ 979 SetSpdLmtRchd 979;
BA_REL_ "GenSigTimeoutTime" BU_SG_REL_ BCM_HS SG_ 979 SetSpdLmtRchd 250;
BA_REL_ "GenSigSuprvResp" BU_SG_REL_ BCM_HS SG_ 979 ElvtdIdlCstCrStVal 1;
BA_REL_ "GenSigTimeoutMsg" BU_SG_REL_ BCM_HS SG_ 979 ElvtdIdlCstCrStVal 979;
BA_REL_ "GenSigTimeoutTime" BU_SG_REL_ BCM_HS SG_ 979 ElvtdIdlCstCrStVal 250;
BA_REL_ "GenSigSuprvResp" BU_SG_REL_ BCM_HS SG_ 979 ElvtdIdlCstStAvl 1;
BA_REL_ "GenSigTimeoutMsg" BU_SG_REL_ BCM_HS SG_ 979 ElvtdIdlCstStAvl 979;
BA_REL_ "GenSigTimeoutTime" BU_SG_REL_ BCM_HS SG_ 979 ElvtdIdlCstStAvl 250;
BA_REL_ "GenSigSuprvResp" BU_SG_REL_ PTO_HS SG_ 979 PltfrmEngSpdCmmndSt 1;
BA_REL_ "GenSigTimeoutMsg" BU_SG_REL_ PTO_HS SG_ 979 PltfrmEngSpdCmmndSt 979;
BA_REL_ "GenSigTimeoutTime" BU_SG_REL_ PTO_HS SG_ 979 PltfrmEngSpdCmmndSt 250;
BA_REL_ "GenSigSuprvResp" BU_SG_REL_ BCM_HS SG_ 979 EngManfldAirTempCrtd 1;
BA_REL_ "GenSigTimeoutMsg" BU_SG_REL_ BCM_HS SG_ 979 EngManfldAirTempCrtd 979;
BA_REL_ "GenSigTimeoutTime" BU_SG_REL_ BCM_HS SG_ 979 EngManfldAirTempCrtd 250;
BA_REL_ "GenSigSuprvResp" BU_SG_REL_ BSM_HS SG_ 546 ThrmlRefCmpIGBTTmp 1;
BA_REL_ "GenSigTimeoutMsg" BU_SG_REL_ BSM_HS SG_ 546 ThrmlRefCmpIGBTTmp 546;
BA_REL_ "GenSigTimeoutTime" BU_SG_REL_ BSM_HS SG_ 546 ThrmlRefCmpIGBTTmp 250;
BA_REL_ "GenSigSuprvResp" BU_SG_REL_ VICM_HS SG_ 546 ThrmlRefCmpIGBTTmp 1;
BA_REL_ "GenSigTimeoutMsg" BU_SG_REL_ VICM_HS SG_ 546 ThrmlRefCmpIGBTTmp 546;
BA_REL_ "GenSigTimeoutTime" BU_SG_REL_ VICM_HS SG_ 546 ThrmlRefCmpIGBTTmp 250;
BA_REL_ "GenSigSuprvResp" BU_SG_REL_ BSM_HS SG_ 546 ThrmlRefCmpCPUHtSkTmp 1;
BA_REL_ "GenSigTimeoutMsg" BU_SG_REL_ BSM_HS SG_ 546 ThrmlRefCmpCPUHtSkTmp 546;
BA_REL_ "GenSigTimeoutTime" BU_SG_REL_ BSM_HS SG_ 546 ThrmlRefCmpCPUHtSkTmp 250;
BA_REL_ "GenSigSuprvResp" BU_SG_REL_ VICM_HS SG_ 546 ThrmlRefCmpCPUHtSkTmp 1;
BA_REL_ "GenSigTimeoutMsg" BU_SG_REL_ VICM_HS SG_ 546 ThrmlRefCmpCPUHtSkTmp 546;
BA_REL_ "GenSigTimeoutTime" BU_SG_REL_ VICM_HS SG_ 546 ThrmlRefCmpCPUHtSkTmp 250;
BA_REL_ "GenSigSuprvResp" BU_SG_REL_ BSM_HS SG_ 546 ThrmlRefCmpHVInHRsln 1;
BA_REL_ "GenSigTimeoutMsg" BU_SG_REL_ BSM_HS SG_ 546 ThrmlRefCmpHVInHRsln 546;
BA_REL_ "GenSigTimeoutTime" BU_SG_REL_ BSM_HS SG_ 546 ThrmlRefCmpHVInHRsln 250;
BA_REL_ "GenSigSuprvResp" BU_SG_REL_ VICM_HS SG_ 546 ThrmlRefCmpHVInHRsln 1;
BA_REL_ "GenSigTimeoutMsg" BU_SG_REL_ VICM_HS SG_ 546 ThrmlRefCmpHVInHRsln 546;
BA_REL_ "GenSigTimeoutTime" BU_SG_REL_ VICM_HS SG_ 546 ThrmlRefCmpHVInHRsln 250;
BA_REL_ "GenSigSuprvResp" BU_SG_REL_ BSM_HS SG_ 546 ThrmlRfCmprElctrCrnt 1;
BA_REL_ "GenSigTimeoutMsg" BU_SG_REL_ BSM_HS SG_ 546 ThrmlRfCmprElctrCrnt 546;
BA_REL_ "GenSigTimeoutTime" BU_SG_REL_ BSM_HS SG_ 546 ThrmlRfCmprElctrCrnt 250;
BA_REL_ "GenSigSuprvResp" BU_SG_REL_ VICM_HS SG_ 546 ThrmlRfCmprElctrCrnt 1;
BA_REL_ "GenSigTimeoutMsg" BU_SG_REL_ VICM_HS SG_ 546 ThrmlRfCmprElctrCrnt 546;
BA_REL_ "GenSigTimeoutTime" BU_SG_REL_ VICM_HS SG_ 546 ThrmlRfCmprElctrCrnt 250;
BA_REL_ "GenSigSuprvResp" BU_SG_REL_ VICM_HS SG_ 546 ThrmlRfCmprElctrCrnt 1;
BA_REL_ "GenSigTimeoutMsg" BU_SG_REL_ VICM_HS SG_ 546 ThrmlRfCmprElctrCrnt 546;
BA_REL_ "GenSigTimeoutTime" BU_SG_REL_ VICM_HS SG_ 546 ThrmlRfCmprElctrCrnt 250;
BA_REL_ "GenSigSuprvResp" BU_SG_REL_ BSM_HS SG_ 546 ThrmlRefCompSpdFdbck 1;
BA_REL_ "GenSigTimeoutMsg" BU_SG_REL_ BSM_HS SG_ 546 ThrmlRefCompSpdFdbck 546;
BA_REL_ "GenSigTimeoutTime" BU_SG_REL_ BSM_HS SG_ 546 ThrmlRefCompSpdFdbck 250;
BA_REL_ "GenSigSuprvResp" BU_SG_REL_ VICM_HS SG_ 546 ThrmlRefCompSpdFdbck 1;
BA_REL_ "GenSigTimeoutMsg" BU_SG_REL_ VICM_HS SG_ 546 ThrmlRefCompSpdFdbck 546;
BA_REL_ "GenSigTimeoutTime" BU_SG_REL_ VICM_HS SG_ 546 ThrmlRefCompSpdFdbck 250;
BA_REL_ "GenSigSuprvResp" BU_SG_REL_ BSM_HS SG_ 546 ThrmlRefCompStatFdbck 1;
BA_REL_ "GenSigTimeoutMsg" BU_SG_REL_ BSM_HS SG_ 546 ThrmlRefCompStatFdbck 546;
BA_REL_ "GenSigTimeoutTime" BU_SG_REL_ BSM_HS SG_ 546 ThrmlRefCompStatFdbck 250;
BA_REL_ "GenSigSuprvResp" BU_SG_REL_ VICM_HS SG_ 546 ThrmlRefCompStatFdbck 1;
BA_REL_ "GenSigTimeoutMsg" BU_SG_REL_ VICM_HS SG_ 546 ThrmlRefCompStatFdbck 546;
BA_REL_ "GenSigTimeoutTime" BU_SG_REL_ VICM_HS SG_ 546 ThrmlRefCompStatFdbck 250;
BA_REL_ "GenSigSuprvResp" BU_SG_REL_ AHL_AFL_HS SG_ 1027 GFHBFwVsnWidthTrk4 1;
BA_REL_ "GenSigTimeoutMsg" BU_SG_REL_ AHL_AFL_HS SG_ 1027 GFHBFwVsnWidthTrk4 1027;
BA_REL_ "GenSigTimeoutTime" BU_SG_REL_ AHL_AFL_HS SG_ 1027 GFHBFwVsnWidthTrk4 250;
BA_REL_ "GenSigSuprvResp" BU_SG_REL_ AHL_AFL_HS SG_ 1027 GFHBFwVsnVertPosTrk4 1;
BA_REL_ "GenSigTimeoutMsg" BU_SG_REL_ AHL_AFL_HS SG_ 1027 GFHBFwVsnVertPosTrk4 1027;
BA_REL_ "GenSigTimeoutTime" BU_SG_REL_ AHL_AFL_HS SG_ 1027 GFHBFwVsnVertPosTrk4 250;
BA_REL_ "GenSigSuprvResp" BU_SG_REL_ AHL_AFL_HS SG_ 1027 GFHBFwVsnRelLaneTrk4 1;
BA_REL_ "GenSigTimeoutMsg" BU_SG_REL_ AHL_AFL_HS SG_ 1027 GFHBFwVsnRelLaneTrk4 1027;
BA_REL_ "GenSigTimeoutTime" BU_SG_REL_ AHL_AFL_HS SG_ 1027 GFHBFwVsnRelLaneTrk4 250;
BA_REL_ "GenSigSuprvResp" BU_SG_REL_ AHL_AFL_HS SG_ 1027 GFHBFwVsnAzmthRtTrk4 1;
BA_REL_ "GenSigTimeoutMsg" BU_SG_REL_ AHL_AFL_HS SG_ 1027 GFHBFwVsnAzmthRtTrk4 1027;
BA_REL_ "GenSigTimeoutTime" BU_SG_REL_ AHL_AFL_HS SG_ 1027 GFHBFwVsnAzmthRtTrk4 250;
BA_REL_ "GenSigSuprvResp" BU_SG_REL_ AHL_AFL_HS SG_ 1027 GFHBFwVsnCnfdncTrk4 1;
BA_REL_ "GenSigTimeoutMsg" BU_SG_REL_ AHL_AFL_HS SG_ 1027 GFHBFwVsnCnfdncTrk4 1027;
BA_REL_ "GenSigTimeoutTime" BU_SG_REL_ AHL_AFL_HS SG_ 1027 GFHBFwVsnCnfdncTrk4 250;
BA_REL_ "GenSigSuprvResp" BU_SG_REL_ AHL_AFL_HS SG_ 1027 GFHBFwVsnRngTrkRev4 1;
BA_REL_ "GenSigTimeoutMsg" BU_SG_REL_ AHL_AFL_HS SG_ 1027 GFHBFwVsnRngTrkRev4 1027;
BA_REL_ "GenSigTimeoutTime" BU_SG_REL_ AHL_AFL_HS SG_ 1027 GFHBFwVsnRngTrkRev4 250;
BA_REL_ "GenSigSuprvResp" BU_SG_REL_ AHL_AFL_HS SG_ 1027 GFHBFwVsnAzmthTrkRev4 1;
BA_REL_ "GenSigTimeoutMsg" BU_SG_REL_ AHL_AFL_HS SG_ 1027 GFHBFwVsnAzmthTrkRev4 1027;
BA_REL_ "GenSigTimeoutTime" BU_SG_REL_ AHL_AFL_HS SG_ 1027 GFHBFwVsnAzmthTrkRev4 250;
BA_REL_ "GenSigSuprvResp" BU_SG_REL_ AHL_AFL_HS SG_ 1027 GFHBFVsnObjTypTrkRev4 1;
BA_REL_ "GenSigTimeoutMsg" BU_SG_REL_ AHL_AFL_HS SG_ 1027 GFHBFVsnObjTypTrkRev4 1027;
BA_REL_ "GenSigTimeoutTime" BU_SG_REL_ AHL_AFL_HS SG_ 1027 GFHBFVsnObjTypTrkRev4 250;
BA_REL_ "GenSigSuprvResp" BU_SG_REL_ AHL_AFL_HS SG_ 1027 GFHBObjDirTrk4 1;
BA_REL_ "GenSigTimeoutMsg" BU_SG_REL_ AHL_AFL_HS SG_ 1027 GFHBObjDirTrk4 1027;
BA_REL_ "GenSigTimeoutTime" BU_SG_REL_ AHL_AFL_HS SG_ 1027 GFHBObjDirTrk4 250;
BA_REL_ "GenSigSuprvResp" BU_SG_REL_ AHL_AFL_HS SG_ 1027 GFHBFwVsnMesStatTrk4 1;
BA_REL_ "GenSigTimeoutMsg" BU_SG_REL_ AHL_AFL_HS SG_ 1027 GFHBFwVsnMesStatTrk4 1027;
BA_REL_ "GenSigTimeoutTime" BU_SG_REL_ AHL_AFL_HS SG_ 1027 GFHBFwVsnMesStatTrk4 250;
BA_REL_ "GenSigSuprvResp" BU_SG_REL_ AHL_AFL_HS SG_ 1027 GFHBFwVsnObjIDTrk4 1;
BA_REL_ "GenSigTimeoutMsg" BU_SG_REL_ AHL_AFL_HS SG_ 1027 GFHBFwVsnObjIDTrk4 1027;
BA_REL_ "GenSigTimeoutTime" BU_SG_REL_ AHL_AFL_HS SG_ 1027 GFHBFwVsnObjIDTrk4 250;
BA_REL_ "GenSigSuprvResp" BU_SG_REL_ AHL_AFL_HS SG_ 1026 GFHBFwVsnWidthTrk3 1;
BA_REL_ "GenSigTimeoutMsg" BU_SG_REL_ AHL_AFL_HS SG_ 1026 GFHBFwVsnWidthTrk3 1026;
BA_REL_ "GenSigTimeoutTime" BU_SG_REL_ AHL_AFL_HS SG_ 1026 GFHBFwVsnWidthTrk3 250;
BA_REL_ "GenSigSuprvResp" BU_SG_REL_ AHL_AFL_HS SG_ 1026 GFHBFwVsnVertPosTrk3 1;
BA_REL_ "GenSigTimeoutMsg" BU_SG_REL_ AHL_AFL_HS SG_ 1026 GFHBFwVsnVertPosTrk3 1026;
BA_REL_ "GenSigTimeoutTime" BU_SG_REL_ AHL_AFL_HS SG_ 1026 GFHBFwVsnVertPosTrk3 250;
BA_REL_ "GenSigSuprvResp" BU_SG_REL_ AHL_AFL_HS SG_ 1026 GFHBFwVsnRelLaneTrk3 1;
BA_REL_ "GenSigTimeoutMsg" BU_SG_REL_ AHL_AFL_HS SG_ 1026 GFHBFwVsnRelLaneTrk3 1026;
BA_REL_ "GenSigTimeoutTime" BU_SG_REL_ AHL_AFL_HS SG_ 1026 GFHBFwVsnRelLaneTrk3 250;
BA_REL_ "GenSigSuprvResp" BU_SG_REL_ AHL_AFL_HS SG_ 1026 GFHBFwVsnAzmthRtTrk3 1;
BA_REL_ "GenSigTimeoutMsg" BU_SG_REL_ AHL_AFL_HS SG_ 1026 GFHBFwVsnAzmthRtTrk3 1026;
BA_REL_ "GenSigTimeoutTime" BU_SG_REL_ AHL_AFL_HS SG_ 1026 GFHBFwVsnAzmthRtTrk3 250;
BA_REL_ "GenSigSuprvResp" BU_SG_REL_ AHL_AFL_HS SG_ 1026 GFHBFwVsnCnfdncTrk3 1;
BA_REL_ "GenSigTimeoutMsg" BU_SG_REL_ AHL_AFL_HS SG_ 1026 GFHBFwVsnCnfdncTrk3 1026;
BA_REL_ "GenSigTimeoutTime" BU_SG_REL_ AHL_AFL_HS SG_ 1026 GFHBFwVsnCnfdncTrk3 250;
BA_REL_ "GenSigSuprvResp" BU_SG_REL_ AHL_AFL_HS SG_ 1026 GFHBFwVsnRngTrkRev3 1;
BA_REL_ "GenSigTimeoutMsg" BU_SG_REL_ AHL_AFL_HS SG_ 1026 GFHBFwVsnRngTrkRev3 1026;
BA_REL_ "GenSigTimeoutTime" BU_SG_REL_ AHL_AFL_HS SG_ 1026 GFHBFwVsnRngTrkRev3 250;
BA_REL_ "GenSigSuprvResp" BU_SG_REL_ AHL_AFL_HS SG_ 1026 GFHBFwVsnAzmthTrkRev3 1;
BA_REL_ "GenSigTimeoutMsg" BU_SG_REL_ AHL_AFL_HS SG_ 1026 GFHBFwVsnAzmthTrkRev3 1026;
BA_REL_ "GenSigTimeoutTime" BU_SG_REL_ AHL_AFL_HS SG_ 1026 GFHBFwVsnAzmthTrkRev3 250;
BA_REL_ "GenSigSuprvResp" BU_SG_REL_ AHL_AFL_HS SG_ 1026 GFHBFVsnObjTypTrkRev3 1;
BA_REL_ "GenSigTimeoutMsg" BU_SG_REL_ AHL_AFL_HS SG_ 1026 GFHBFVsnObjTypTrkRev3 1026;
BA_REL_ "GenSigTimeoutTime" BU_SG_REL_ AHL_AFL_HS SG_ 1026 GFHBFVsnObjTypTrkRev3 250;
BA_REL_ "GenSigSuprvResp" BU_SG_REL_ AHL_AFL_HS SG_ 1026 GFHBObjDirTrk3 1;
BA_REL_ "GenSigTimeoutMsg" BU_SG_REL_ AHL_AFL_HS SG_ 1026 GFHBObjDirTrk3 1026;
BA_REL_ "GenSigTimeoutTime" BU_SG_REL_ AHL_AFL_HS SG_ 1026 GFHBObjDirTrk3 250;
BA_REL_ "GenSigSuprvResp" BU_SG_REL_ AHL_AFL_HS SG_ 1026 GFHBFwVsnMesStatTrk3 1;
BA_REL_ "GenSigTimeoutMsg" BU_SG_REL_ AHL_AFL_HS SG_ 1026 GFHBFwVsnMesStatTrk3 1026;
BA_REL_ "GenSigTimeoutTime" BU_SG_REL_ AHL_AFL_HS SG_ 1026 GFHBFwVsnMesStatTrk3 250;
BA_REL_ "GenSigSuprvResp" BU_SG_REL_ AHL_AFL_HS SG_ 1026 GFHBFwVsnObjIDTrk3 1;
BA_REL_ "GenSigTimeoutMsg" BU_SG_REL_ AHL_AFL_HS SG_ 1026 GFHBFwVsnObjIDTrk3 1026;
BA_REL_ "GenSigTimeoutTime" BU_SG_REL_ AHL_AFL_HS SG_ 1026 GFHBFwVsnObjIDTrk3 250;
BA_REL_ "GenSigSuprvResp" BU_SG_REL_ AHL_AFL_HS SG_ 1025 GFHBFwVsnWidthTrk2 1;
BA_REL_ "GenSigTimeoutMsg" BU_SG_REL_ AHL_AFL_HS SG_ 1025 GFHBFwVsnWidthTrk2 1025;
BA_REL_ "GenSigTimeoutTime" BU_SG_REL_ AHL_AFL_HS SG_ 1025 GFHBFwVsnWidthTrk2 250;
BA_REL_ "GenSigSuprvResp" BU_SG_REL_ AHL_AFL_HS SG_ 1025 GFHBFwVsnVertPosTrk2 1;
BA_REL_ "GenSigTimeoutMsg" BU_SG_REL_ AHL_AFL_HS SG_ 1025 GFHBFwVsnVertPosTrk2 1025;
BA_REL_ "GenSigTimeoutTime" BU_SG_REL_ AHL_AFL_HS SG_ 1025 GFHBFwVsnVertPosTrk2 250;
BA_REL_ "GenSigSuprvResp" BU_SG_REL_ AHL_AFL_HS SG_ 1025 GFHBFwVsnRelLaneTrk2 1;
BA_REL_ "GenSigTimeoutMsg" BU_SG_REL_ AHL_AFL_HS SG_ 1025 GFHBFwVsnRelLaneTrk2 1025;
BA_REL_ "GenSigTimeoutTime" BU_SG_REL_ AHL_AFL_HS SG_ 1025 GFHBFwVsnRelLaneTrk2 250;
BA_REL_ "GenSigSuprvResp" BU_SG_REL_ AHL_AFL_HS SG_ 1025 GFHBFwVsnAzmthRtTrk2 1;
BA_REL_ "GenSigTimeoutMsg" BU_SG_REL_ AHL_AFL_HS SG_ 1025 GFHBFwVsnAzmthRtTrk2 1025;
BA_REL_ "GenSigTimeoutTime" BU_SG_REL_ AHL_AFL_HS SG_ 1025 GFHBFwVsnAzmthRtTrk2 250;
BA_REL_ "GenSigSuprvResp" BU_SG_REL_ AHL_AFL_HS SG_ 1025 GFHBFwVsnCnfdncTrk2 1;
BA_REL_ "GenSigTimeoutMsg" BU_SG_REL_ AHL_AFL_HS SG_ 1025 GFHBFwVsnCnfdncTrk2 1025;
BA_REL_ "GenSigTimeoutTime" BU_SG_REL_ AHL_AFL_HS SG_ 1025 GFHBFwVsnCnfdncTrk2 250;
BA_REL_ "GenSigSuprvResp" BU_SG_REL_ AHL_AFL_HS SG_ 1025 GFHBFwVsnRngTrkRev2 1;
BA_REL_ "GenSigTimeoutMsg" BU_SG_REL_ AHL_AFL_HS SG_ 1025 GFHBFwVsnRngTrkRev2 1025;
BA_REL_ "GenSigTimeoutTime" BU_SG_REL_ AHL_AFL_HS SG_ 1025 GFHBFwVsnRngTrkRev2 250;
BA_REL_ "GenSigSuprvResp" BU_SG_REL_ AHL_AFL_HS SG_ 1025 GFHBFwVsnAzmthTrkRev2 1;
BA_REL_ "GenSigTimeoutMsg" BU_SG_REL_ AHL_AFL_HS SG_ 1025 GFHBFwVsnAzmthTrkRev2 1025;
BA_REL_ "GenSigTimeoutTime" BU_SG_REL_ AHL_AFL_HS SG_ 1025 GFHBFwVsnAzmthTrkRev2 250;
BA_REL_ "GenSigSuprvResp" BU_SG_REL_ AHL_AFL_HS SG_ 1025 GFHBFVsnObjTypTrkRev2 1;
BA_REL_ "GenSigTimeoutMsg" BU_SG_REL_ AHL_AFL_HS SG_ 1025 GFHBFVsnObjTypTrkRev2 1025;
BA_REL_ "GenSigTimeoutTime" BU_SG_REL_ AHL_AFL_HS SG_ 1025 GFHBFVsnObjTypTrkRev2 250;
BA_REL_ "GenSigSuprvResp" BU_SG_REL_ AHL_AFL_HS SG_ 1025 GFHBObjDirTrk2 1;
BA_REL_ "GenSigTimeoutMsg" BU_SG_REL_ AHL_AFL_HS SG_ 1025 GFHBObjDirTrk2 1025;
BA_REL_ "GenSigTimeoutTime" BU_SG_REL_ AHL_AFL_HS SG_ 1025 GFHBObjDirTrk2 250;
BA_REL_ "GenSigSuprvResp" BU_SG_REL_ AHL_AFL_HS SG_ 1025 GFHBFwVsnMesStatTrk2 1;
BA_REL_ "GenSigTimeoutMsg" BU_SG_REL_ AHL_AFL_HS SG_ 1025 GFHBFwVsnMesStatTrk2 1025;
BA_REL_ "GenSigTimeoutTime" BU_SG_REL_ AHL_AFL_HS SG_ 1025 GFHBFwVsnMesStatTrk2 250;
BA_REL_ "GenSigSuprvResp" BU_SG_REL_ AHL_AFL_HS SG_ 1025 GFHBFwVsnObjIDTrk2 1;
BA_REL_ "GenSigTimeoutMsg" BU_SG_REL_ AHL_AFL_HS SG_ 1025 GFHBFwVsnObjIDTrk2 1025;
BA_REL_ "GenSigTimeoutTime" BU_SG_REL_ AHL_AFL_HS SG_ 1025 GFHBFwVsnObjIDTrk2 250;
BA_REL_ "GenSigSuprvResp" BU_SG_REL_ AHL_AFL_HS SG_ 1024 GFHBFwVsnWidthTrk1 1;
BA_REL_ "GenSigTimeoutMsg" BU_SG_REL_ AHL_AFL_HS SG_ 1024 GFHBFwVsnWidthTrk1 1024;
BA_REL_ "GenSigTimeoutTime" BU_SG_REL_ AHL_AFL_HS SG_ 1024 GFHBFwVsnWidthTrk1 250;
BA_REL_ "GenSigSuprvResp" BU_SG_REL_ AHL_AFL_HS SG_ 1024 GFHBFwVsnVertPosTrk1 1;
BA_REL_ "GenSigTimeoutMsg" BU_SG_REL_ AHL_AFL_HS SG_ 1024 GFHBFwVsnVertPosTrk1 1024;
BA_REL_ "GenSigTimeoutTime" BU_SG_REL_ AHL_AFL_HS SG_ 1024 GFHBFwVsnVertPosTrk1 250;
BA_REL_ "GenSigSuprvResp" BU_SG_REL_ AHL_AFL_HS SG_ 1024 GFHBFwVsnRelLaneTrk1 1;
BA_REL_ "GenSigTimeoutMsg" BU_SG_REL_ AHL_AFL_HS SG_ 1024 GFHBFwVsnRelLaneTrk1 1024;
BA_REL_ "GenSigTimeoutTime" BU_SG_REL_ AHL_AFL_HS SG_ 1024 GFHBFwVsnRelLaneTrk1 250;
BA_REL_ "GenSigSuprvResp" BU_SG_REL_ AHL_AFL_HS SG_ 1024 GFHBFwVsnAzmthRtTrk1 1;
BA_REL_ "GenSigTimeoutMsg" BU_SG_REL_ AHL_AFL_HS SG_ 1024 GFHBFwVsnAzmthRtTrk1 1024;
BA_REL_ "GenSigTimeoutTime" BU_SG_REL_ AHL_AFL_HS SG_ 1024 GFHBFwVsnAzmthRtTrk1 250;
BA_REL_ "GenSigSuprvResp" BU_SG_REL_ AHL_AFL_HS SG_ 1024 GFHBFwVsnCnfdncTrk1 1;
BA_REL_ "GenSigTimeoutMsg" BU_SG_REL_ AHL_AFL_HS SG_ 1024 GFHBFwVsnCnfdncTrk1 1024;
BA_REL_ "GenSigTimeoutTime" BU_SG_REL_ AHL_AFL_HS SG_ 1024 GFHBFwVsnCnfdncTrk1 250;
BA_REL_ "GenSigSuprvResp" BU_SG_REL_ AHL_AFL_HS SG_ 1024 GFHBFwVsnRngTrkRev1 1;
BA_REL_ "GenSigTimeoutMsg" BU_SG_REL_ AHL_AFL_HS SG_ 1024 GFHBFwVsnRngTrkRev1 1024;
BA_REL_ "GenSigTimeoutTime" BU_SG_REL_ AHL_AFL_HS SG_ 1024 GFHBFwVsnRngTrkRev1 250;
BA_REL_ "GenSigSuprvResp" BU_SG_REL_ AHL_AFL_HS SG_ 1024 GFHBFwVsnAzmthTrkRev1 1;
BA_REL_ "GenSigTimeoutMsg" BU_SG_REL_ AHL_AFL_HS SG_ 1024 GFHBFwVsnAzmthTrkRev1 1024;
BA_REL_ "GenSigTimeoutTime" BU_SG_REL_ AHL_AFL_HS SG_ 1024 GFHBFwVsnAzmthTrkRev1 250;
BA_REL_ "GenSigSuprvResp" BU_SG_REL_ AHL_AFL_HS SG_ 1024 GFHBFVsnObjTypTrkRev1 1;
BA_REL_ "GenSigTimeoutMsg" BU_SG_REL_ AHL_AFL_HS SG_ 1024 GFHBFVsnObjTypTrkRev1 1024;
BA_REL_ "GenSigTimeoutTime" BU_SG_REL_ AHL_AFL_HS SG_ 1024 GFHBFVsnObjTypTrkRev1 250;
BA_REL_ "GenSigSuprvResp" BU_SG_REL_ AHL_AFL_HS SG_ 1024 GFHBObjDirTrk1 1;
BA_REL_ "GenSigTimeoutMsg" BU_SG_REL_ AHL_AFL_HS SG_ 1024 GFHBObjDirTrk1 1024;
BA_REL_ "GenSigTimeoutTime" BU_SG_REL_ AHL_AFL_HS SG_ 1024 GFHBObjDirTrk1 250;
BA_REL_ "GenSigSuprvResp" BU_SG_REL_ AHL_AFL_HS SG_ 1024 GFHBFwVsnMesStatTrk1 1;
BA_REL_ "GenSigTimeoutMsg" BU_SG_REL_ AHL_AFL_HS SG_ 1024 GFHBFwVsnMesStatTrk1 1024;
BA_REL_ "GenSigTimeoutTime" BU_SG_REL_ AHL_AFL_HS SG_ 1024 GFHBFwVsnMesStatTrk1 250;
BA_REL_ "GenSigSuprvResp" BU_SG_REL_ AHL_AFL_HS SG_ 1024 GFHBFwVsnObjIDTrk1 1;
BA_REL_ "GenSigTimeoutMsg" BU_SG_REL_ AHL_AFL_HS SG_ 1024 GFHBFwVsnObjIDTrk1 1024;
BA_REL_ "GenSigTimeoutTime" BU_SG_REL_ AHL_AFL_HS SG_ 1024 GFHBFwVsnObjIDTrk1 250;
BA_REL_ "GenSigSuprvResp" BU_SG_REL_ TCM_HS SG_ 508 LonLatAccSnsChk 1;
BA_REL_ "GenSigTimeoutMsg" BU_SG_REL_ TCM_HS SG_ 508 LonLatAccSnsChk 508;
BA_REL_ "GenSigTimeoutTime" BU_SG_REL_ TCM_HS SG_ 508 LonLatAccSnsChk 125;
BA_REL_ "GenSigSuprvResp" BU_SG_REL_ TCM_HS SG_ 508 LonLatAccSnsValARC 1;
BA_REL_ "GenSigTimeoutMsg" BU_SG_REL_ TCM_HS SG_ 508 LonLatAccSnsValARC 508;
BA_REL_ "GenSigTimeoutTime" BU_SG_REL_ TCM_HS SG_ 508 LonLatAccSnsValARC 125;
BA_REL_ "GenSigSuprvResp" BU_SG_REL_ ECM_HS SG_ 508 LatAccSnsVal 1;
BA_REL_ "GenSigTimeoutMsg" BU_SG_REL_ ECM_HS SG_ 508 LatAccSnsVal 508;
BA_REL_ "GenSigTimeoutTime" BU_SG_REL_ ECM_HS SG_ 508 LatAccSnsVal 250;
BA_REL_ "GenSigSuprvResp" BU_SG_REL_ ICCM_OBD_HS SG_ 508 LatAccSnsVal 1;
BA_REL_ "GenSigTimeoutMsg" BU_SG_REL_ ICCM_OBD_HS SG_ 508 LatAccSnsVal 508;
BA_REL_ "GenSigTimeoutTime" BU_SG_REL_ ICCM_OBD_HS SG_ 508 LatAccSnsVal 250;
BA_REL_ "GenSigSuprvResp" BU_SG_REL_ ICCM_HS SG_ 508 LatAccSnsVal 1;
BA_REL_ "GenSigTimeoutMsg" BU_SG_REL_ ICCM_HS SG_ 508 LatAccSnsVal 508;
BA_REL_ "GenSigTimeoutTime" BU_SG_REL_ ICCM_HS SG_ 508 LatAccSnsVal 250;
BA_REL_ "GenSigSuprvResp" BU_SG_REL_ TCM_HS SG_ 508 LatAccSnsVal 1;
BA_REL_ "GenSigTimeoutMsg" BU_SG_REL_ TCM_HS SG_ 508 LatAccSnsVal 508;
BA_REL_ "GenSigTimeoutTime" BU_SG_REL_ TCM_HS SG_ 508 LatAccSnsVal 125;
BA_REL_ "GenSigSuprvResp" BU_SG_REL_ ECM_HS SG_ 508 LonAccSnsVal 1;
BA_REL_ "GenSigTimeoutMsg" BU_SG_REL_ ECM_HS SG_ 508 LonAccSnsVal 508;
BA_REL_ "GenSigTimeoutTime" BU_SG_REL_ ECM_HS SG_ 508 LonAccSnsVal 250;
BA_REL_ "GenSigSuprvResp" BU_SG_REL_ ICCM_OBD_HS SG_ 508 LonAccSnsVal 1;
BA_REL_ "GenSigTimeoutMsg" BU_SG_REL_ ICCM_OBD_HS SG_ 508 LonAccSnsVal 508;
BA_REL_ "GenSigTimeoutTime" BU_SG_REL_ ICCM_OBD_HS SG_ 508 LonAccSnsVal 250;
BA_REL_ "GenSigSuprvResp" BU_SG_REL_ ICCM_HS SG_ 508 LonAccSnsVal 1;
BA_REL_ "GenSigTimeoutMsg" BU_SG_REL_ ICCM_HS SG_ 508 LonAccSnsVal 508;
BA_REL_ "GenSigTimeoutTime" BU_SG_REL_ ICCM_HS SG_ 508 LonAccSnsVal 250;
BA_REL_ "GenSigSuprvResp" BU_SG_REL_ TCM_HS SG_ 508 LonAccSnsVal 1;
BA_REL_ "GenSigTimeoutMsg" BU_SG_REL_ TCM_HS SG_ 508 LonAccSnsVal 508;
BA_REL_ "GenSigTimeoutTime" BU_SG_REL_ TCM_HS SG_ 508 LonAccSnsVal 125;
BA_REL_ "GenSigSuprvResp" BU_SG_REL_ HCP_B_HS SG_ 508 CSTBATS_TrqVl 1;
BA_REL_ "GenSigTimeoutMsg" BU_SG_REL_ HCP_B_HS SG_ 508 CSTBATS_TrqVl 508;
BA_REL_ "GenSigTimeoutTime" BU_SG_REL_ HCP_B_HS SG_ 508 CSTBATS_TrqVl 250;
BA_REL_ "GenSigSuprvResp" BU_SG_REL_ SADS_HS SG_ 508 CSTBATS_TrqVl 1;
BA_REL_ "GenSigTimeoutMsg" BU_SG_REL_ SADS_HS SG_ 508 CSTBATS_TrqVl 508;
BA_REL_ "GenSigTimeoutTime" BU_SG_REL_ SADS_HS SG_ 508 CSTBATS_TrqVl 250;
BA_REL_ "GenSigSuprvResp" BU_SG_REL_ ECM_HS SG_ 508 CSTBATS_TrqVl 1;
BA_REL_ "GenSigTimeoutMsg" BU_SG_REL_ ECM_HS SG_ 508 CSTBATS_TrqVl 508;
BA_REL_ "GenSigTimeoutTime" BU_SG_REL_ ECM_HS SG_ 508 CSTBATS_TrqVl 250;
BA_REL_ "GenSigSuprvResp" BU_SG_REL_ ICCM_OBD_HS SG_ 508 CSTBATS_TrqVl 1;
BA_REL_ "GenSigTimeoutMsg" BU_SG_REL_ ICCM_OBD_HS SG_ 508 CSTBATS_TrqVl 508;
BA_REL_ "GenSigTimeoutTime" BU_SG_REL_ ICCM_OBD_HS SG_ 508 CSTBATS_TrqVl 250;
BA_REL_ "GenSigSuprvResp" BU_SG_REL_ ICCM_HS SG_ 508 CSTBATS_TrqVl 1;
BA_REL_ "GenSigTimeoutMsg" BU_SG_REL_ ICCM_HS SG_ 508 CSTBATS_TrqVl 508;
BA_REL_ "GenSigTimeoutTime" BU_SG_REL_ ICCM_HS SG_ 508 CSTBATS_TrqVl 250;
BA_REL_ "GenSigSuprvResp" BU_SG_REL_ HCP_T_HS SG_ 508 CSTBATS_TrqVl 1;
BA_REL_ "GenSigTimeoutMsg" BU_SG_REL_ HCP_T_HS SG_ 508 CSTBATS_TrqVl 508;
BA_REL_ "GenSigTimeoutTime" BU_SG_REL_ HCP_T_HS SG_ 508 CSTBATS_TrqVl 250;
BA_REL_ "GenSigSuprvResp" BU_SG_REL_ TCM_HS SG_ 508 CSTBATS_TrqVl 1;
BA_REL_ "GenSigTimeoutMsg" BU_SG_REL_ TCM_HS SG_ 508 CSTBATS_TrqVl 508;
BA_REL_ "GenSigTimeoutTime" BU_SG_REL_ TCM_HS SG_ 508 CSTBATS_TrqVl 125;
BA_REL_ "GenSigSuprvResp" BU_SG_REL_ HCP_B_HS SG_ 508 CSTBATS_TrqVlV 1;
BA_REL_ "GenSigTimeoutMsg" BU_SG_REL_ HCP_B_HS SG_ 508 CSTBATS_TrqVlV 508;
BA_REL_ "GenSigTimeoutTime" BU_SG_REL_ HCP_B_HS SG_ 508 CSTBATS_TrqVlV 250;
BA_REL_ "GenSigSuprvResp" BU_SG_REL_ SADS_HS SG_ 508 CSTBATS_TrqVlV 1;
BA_REL_ "GenSigTimeoutMsg" BU_SG_REL_ SADS_HS SG_ 508 CSTBATS_TrqVlV 508;
BA_REL_ "GenSigTimeoutTime" BU_SG_REL_ SADS_HS SG_ 508 CSTBATS_TrqVlV 250;
BA_REL_ "GenSigSuprvResp" BU_SG_REL_ ECM_HS SG_ 508 CSTBATS_TrqVlV 1;
BA_REL_ "GenSigTimeoutMsg" BU_SG_REL_ ECM_HS SG_ 508 CSTBATS_TrqVlV 508;
BA_REL_ "GenSigTimeoutTime" BU_SG_REL_ ECM_HS SG_ 508 CSTBATS_TrqVlV 250;
BA_REL_ "GenSigSuprvResp" BU_SG_REL_ ICCM_OBD_HS SG_ 508 CSTBATS_TrqVlV 1;
BA_REL_ "GenSigTimeoutMsg" BU_SG_REL_ ICCM_OBD_HS SG_ 508 CSTBATS_TrqVlV 508;
BA_REL_ "GenSigTimeoutTime" BU_SG_REL_ ICCM_OBD_HS SG_ 508 CSTBATS_TrqVlV 250;
BA_REL_ "GenSigSuprvResp" BU_SG_REL_ ICCM_HS SG_ 508 CSTBATS_TrqVlV 1;
BA_REL_ "GenSigTimeoutMsg" BU_SG_REL_ ICCM_HS SG_ 508 CSTBATS_TrqVlV 508;
BA_REL_ "GenSigTimeoutTime" BU_SG_REL_ ICCM_HS SG_ 508 CSTBATS_TrqVlV 250;
BA_REL_ "GenSigSuprvResp" BU_SG_REL_ HCP_T_HS SG_ 508 CSTBATS_TrqVlV 1;
BA_REL_ "GenSigTimeoutMsg" BU_SG_REL_ HCP_T_HS SG_ 508 CSTBATS_TrqVlV 508;
BA_REL_ "GenSigTimeoutTime" BU_SG_REL_ HCP_T_HS SG_ 508 CSTBATS_TrqVlV 250;
BA_REL_ "GenSigSuprvResp" BU_SG_REL_ TCM_HS SG_ 508 CSTBATS_TrqVlV 1;
BA_REL_ "GenSigTimeoutMsg" BU_SG_REL_ TCM_HS SG_ 508 CSTBATS_TrqVlV 508;
BA_REL_ "GenSigTimeoutTime" BU_SG_REL_ TCM_HS SG_ 508 CSTBATS_TrqVlV 125;
BA_REL_ "GenSigSuprvResp" BU_SG_REL_ HCP_B_HS SG_ 422 TrnsAuxPrsDisOvrrdOn 1;
BA_REL_ "GenSigTimeoutMsg" BU_SG_REL_ HCP_B_HS SG_ 422 TrnsAuxPrsDisOvrrdOn 422;
BA_REL_ "GenSigTimeoutTime" BU_SG_REL_ HCP_B_HS SG_ 422 TrnsAuxPrsDisOvrrdOn 250;
BA_REL_ "GenSigSuprvResp" BU_SG_REL_ ECM_HS SG_ 422 TrnsAuxPrsDisOvrrdOn 1;
BA_REL_ "GenSigTimeoutMsg" BU_SG_REL_ ECM_HS SG_ 422 TrnsAuxPrsDisOvrrdOn 422;
BA_REL_ "GenSigTimeoutTime" BU_SG_REL_ ECM_HS SG_ 422 TrnsAuxPrsDisOvrrdOn 250;
BA_REL_ "GenSigSuprvResp" BU_SG_REL_ ECM_HS SG_ 422 TransEngShtdwnRqd 1;
BA_REL_ "GenSigTimeoutMsg" BU_SG_REL_ ECM_HS SG_ 422 TransEngShtdwnRqd 422;
BA_REL_ "GenSigTimeoutTime" BU_SG_REL_ ECM_HS SG_ 422 TransEngShtdwnRqd 250;
BA_REL_ "GenSigSuprvResp" BU_SG_REL_ ECM_HS SG_ 422 TransCrksftTqLoad 1;
BA_REL_ "GenSigTimeoutMsg" BU_SG_REL_ ECM_HS SG_ 422 TransCrksftTqLoad 422;
BA_REL_ "GenSigTimeoutTime" BU_SG_REL_ ECM_HS SG_ 422 TransCrksftTqLoad 250;
BA_REL_ "GenSigSuprvResp" BU_SG_REL_ ECM_HS SG_ 422 TrStPTGrdBrkDsMdOvr 1;
BA_REL_ "GenSigTimeoutMsg" BU_SG_REL_ ECM_HS SG_ 422 TrStPTGrdBrkDsMdOvr 422;
BA_REL_ "GenSigTimeoutTime" BU_SG_REL_ ECM_HS SG_ 422 TrStPTGrdBrkDsMdOvr 62;
BA_REL_ "GenSigSuprvResp" BU_SG_REL_ HCP_B_HS SG_ 422 TrnsHybEngSrtStpOvrd 1;
BA_REL_ "GenSigTimeoutMsg" BU_SG_REL_ HCP_B_HS SG_ 422 TrnsHybEngSrtStpOvrd 422;
BA_REL_ "GenSigTimeoutTime" BU_SG_REL_ HCP_B_HS SG_ 422 TrnsHybEngSrtStpOvrd 250;
BA_REL_ "GenSigSuprvResp" BU_SG_REL_ ECM_HS SG_ 422 TrnsHybEngSrtStpOvrd 1;
BA_REL_ "GenSigTimeoutMsg" BU_SG_REL_ ECM_HS SG_ 422 TrnsHybEngSrtStpOvrd 422;
BA_REL_ "GenSigTimeoutTime" BU_SG_REL_ ECM_HS SG_ 422 TrnsHybEngSrtStpOvrd 250;
BA_REL_ "GenSigSuprvResp" BU_SG_REL_ TCM_HS SG_ 647 EngDetPndTrnCsRngShf 1;
BA_REL_ "GenSigTimeoutMsg" BU_SG_REL_ TCM_HS SG_ 647 EngDetPndTrnCsRngShf 647;
BA_REL_ "GenSigTimeoutTime" BU_SG_REL_ TCM_HS SG_ 647 EngDetPndTrnCsRngShf 250;
BA_REL_ "GenSigSuprvResp" BU_SG_REL_ TCM_HS SG_ 647 CrpCstCrvCmd 1;
BA_REL_ "GenSigTimeoutMsg" BU_SG_REL_ TCM_HS SG_ 647 CrpCstCrvCmd 647;
BA_REL_ "GenSigTimeoutTime" BU_SG_REL_ TCM_HS SG_ 647 CrpCstCrvCmd 250;
BA_REL_ "GenSigSuprvResp" BU_SG_REL_ HCP_T_HS SG_ 647 CrpCstCrvCmd 1;
BA_REL_ "GenSigTimeoutMsg" BU_SG_REL_ HCP_T_HS SG_ 647 CrpCstCrvCmd 647;
BA_REL_ "GenSigTimeoutTime" BU_SG_REL_ HCP_T_HS SG_ 647 CrpCstCrvCmd 250;
BA_REL_ "GenSigSuprvResp" BU_SG_REL_ HCP_T_HS SG_ 647 DrvMntnMdCmnd 1;
BA_REL_ "GenSigTimeoutMsg" BU_SG_REL_ HCP_T_HS SG_ 647 DrvMntnMdCmnd 647;
BA_REL_ "GenSigTimeoutTime" BU_SG_REL_ HCP_T_HS SG_ 647 DrvMntnMdCmnd 250;
BA_REL_ "GenSigSuprvResp" BU_SG_REL_ HCP_T_HS SG_ 647 DrvHldMdCmnd 1;
BA_REL_ "GenSigTimeoutMsg" BU_SG_REL_ HCP_T_HS SG_ 647 DrvHldMdCmnd 647;
BA_REL_ "GenSigTimeoutTime" BU_SG_REL_ HCP_T_HS SG_ 647 DrvHldMdCmnd 250;
BA_REL_ "GenSigSuprvResp" BU_SG_REL_ HCP_T_HS SG_ 647 DrPTGrdBrkDsbMdCmd 1;
BA_REL_ "GenSigTimeoutMsg" BU_SG_REL_ HCP_T_HS SG_ 647 DrPTGrdBrkDsbMdCmd 647;
BA_REL_ "GenSigTimeoutTime" BU_SG_REL_ HCP_T_HS SG_ 647 DrPTGrdBrkDsbMdCmd 250;
BA_REL_ "GenSigSuprvResp" BU_SG_REL_ TCM_HS SG_ 647 DrPTGrdBrkDsbMdCmd 1;
BA_REL_ "GenSigTimeoutMsg" BU_SG_REL_ TCM_HS SG_ 647 DrPTGrdBrkDsbMdCmd 647;
BA_REL_ "GenSigTimeoutTime" BU_SG_REL_ TCM_HS SG_ 647 DrPTGrdBrkDsbMdCmd 62;
BA_REL_ "GenSigSuprvResp" BU_SG_REL_ HCP_HS SG_ 647 DrPTGrdBrkDsbMdCmd 1;
BA_REL_ "GenSigTimeoutMsg" BU_SG_REL_ HCP_HS SG_ 647 DrPTGrdBrkDsbMdCmd 647;
BA_REL_ "GenSigTimeoutTime" BU_SG_REL_ HCP_HS SG_ 647 DrPTGrdBrkDsbMdCmd 62;
BA_REL_ "GenSigSuprvResp" BU_SG_REL_ TCM_HS SG_ 647 DrvWntrMdCmd 1;
BA_REL_ "GenSigTimeoutMsg" BU_SG_REL_ TCM_HS SG_ 647 DrvWntrMdCmd 647;
BA_REL_ "GenSigTimeoutTime" BU_SG_REL_ TCM_HS SG_ 647 DrvWntrMdCmd 62;
BA_REL_ "GenSigSuprvResp" BU_SG_REL_ HCP_T_HS SG_ 647 DrvTwHaulMdCmd 1;
BA_REL_ "GenSigTimeoutMsg" BU_SG_REL_ HCP_T_HS SG_ 647 DrvTwHaulMdCmd 647;
BA_REL_ "GenSigTimeoutTime" BU_SG_REL_ HCP_T_HS SG_ 647 DrvTwHaulMdCmd 250;
BA_REL_ "GenSigSuprvResp" BU_SG_REL_ HCP_HS SG_ 647 DrvTwHaulMdCmd 1;
BA_REL_ "GenSigTimeoutMsg" BU_SG_REL_ HCP_HS SG_ 647 DrvTwHaulMdCmd 647;
BA_REL_ "GenSigTimeoutTime" BU_SG_REL_ HCP_HS SG_ 647 DrvTwHaulMdCmd 62;
BA_REL_ "GenSigSuprvResp" BU_SG_REL_ TCM_HS SG_ 647 DrvTwHaulMdCmd 1;
BA_REL_ "GenSigTimeoutMsg" BU_SG_REL_ TCM_HS SG_ 647 DrvTwHaulMdCmd 647;
BA_REL_ "GenSigTimeoutTime" BU_SG_REL_ TCM_HS SG_ 647 DrvTwHaulMdCmd 62;
BA_REL_ "GenSigSuprvResp" BU_SG_REL_ HCP_B_HS SG_ 647 DrvTwHaulMdCmd 1;
BA_REL_ "GenSigTimeoutMsg" BU_SG_REL_ HCP_B_HS SG_ 647 DrvTwHaulMdCmd 647;
BA_REL_ "GenSigTimeoutTime" BU_SG_REL_ HCP_B_HS SG_ 647 DrvTwHaulMdCmd 250;
BA_REL_ "GenSigSuprvResp" BU_SG_REL_ HCP_T_HS SG_ 647 DrvSprtMdCmd 1;
BA_REL_ "GenSigTimeoutMsg" BU_SG_REL_ HCP_T_HS SG_ 647 DrvSprtMdCmd 647;
BA_REL_ "GenSigTimeoutTime" BU_SG_REL_ HCP_T_HS SG_ 647 DrvSprtMdCmd 250;
BA_REL_ "GenSigSuprvResp" BU_SG_REL_ HCP_T_HS SG_ 647 DrvSprtMdCmd 1;
BA_REL_ "GenSigTimeoutMsg" BU_SG_REL_ HCP_T_HS SG_ 647 DrvSprtMdCmd 647;
BA_REL_ "GenSigTimeoutTime" BU_SG_REL_ HCP_T_HS SG_ 647 DrvSprtMdCmd 250;
BA_REL_ "GenSigSuprvResp" BU_SG_REL_ TCM_HS SG_ 647 DrvSprtMdCmd 1;
BA_REL_ "GenSigTimeoutMsg" BU_SG_REL_ TCM_HS SG_ 647 DrvSprtMdCmd 647;
BA_REL_ "GenSigTimeoutTime" BU_SG_REL_ TCM_HS SG_ 647 DrvSprtMdCmd 62;
BA_REL_ "GenSigSuprvResp" BU_SG_REL_ HCP_HS SG_ 647 DrvSprtMdCmd 1;
BA_REL_ "GenSigTimeoutMsg" BU_SG_REL_ HCP_HS SG_ 647 DrvSprtMdCmd 647;
BA_REL_ "GenSigTimeoutTime" BU_SG_REL_ HCP_HS SG_ 647 DrvSprtMdCmd 62;
BA_REL_ "GenSigSuprvResp" BU_SG_REL_ TCM_HS SG_ 647 DrvEconMdCmd 1;
BA_REL_ "GenSigTimeoutMsg" BU_SG_REL_ TCM_HS SG_ 647 DrvEconMdCmd 647;
BA_REL_ "GenSigTimeoutTime" BU_SG_REL_ TCM_HS SG_ 647 DrvEconMdCmd 62;
BA_REL_ "GenSigSuprvResp" BU_SG_REL_ ICCM_OBD_HS SG_ 647 EngCntrlDtrmdTrfCRng 1;
BA_REL_ "GenSigTimeoutMsg" BU_SG_REL_ ICCM_OBD_HS SG_ 647 EngCntrlDtrmdTrfCRng 647;
BA_REL_ "GenSigTimeoutTime" BU_SG_REL_ ICCM_OBD_HS SG_ 647 EngCntrlDtrmdTrfCRng 250;
BA_REL_ "GenSigSuprvResp" BU_SG_REL_ ICCM_HS SG_ 647 EngCntrlDtrmdTrfCRng 1;
BA_REL_ "GenSigTimeoutMsg" BU_SG_REL_ ICCM_HS SG_ 647 EngCntrlDtrmdTrfCRng 647;
BA_REL_ "GenSigTimeoutTime" BU_SG_REL_ ICCM_HS SG_ 647 EngCntrlDtrmdTrfCRng 250;
BA_REL_ "GenSigSuprvResp" BU_SG_REL_ FICM_HS SG_ 647 EngCntrlDtrmdTrfCRng 1;
BA_REL_ "GenSigTimeoutMsg" BU_SG_REL_ FICM_HS SG_ 647 EngCntrlDtrmdTrfCRng 647;
BA_REL_ "GenSigTimeoutTime" BU_SG_REL_ FICM_HS SG_ 647 EngCntrlDtrmdTrfCRng 250;
BA_REL_ "GenSigSuprvResp" BU_SG_REL_ HCP_T_HS SG_ 647 EngCtrlUtldTrnCRgPVal 1;
BA_REL_ "GenSigTimeoutMsg" BU_SG_REL_ HCP_T_HS SG_ 647 EngCtrlUtldTrnCRgPVal 647;
BA_REL_ "GenSigTimeoutTime" BU_SG_REL_ HCP_T_HS SG_ 647 EngCtrlUtldTrnCRgPVal 250;
BA_REL_ "GenSigSuprvResp" BU_SG_REL_ EBCM_OBD_HS SG_ 647 EngCtrlUtldTrnCRgPVal 1;
BA_REL_ "GenSigTimeoutMsg" BU_SG_REL_ EBCM_OBD_HS SG_ 647 EngCtrlUtldTrnCRgPVal 647;
BA_REL_ "GenSigTimeoutTime" BU_SG_REL_ EBCM_OBD_HS SG_ 647 EngCtrlUtldTrnCRgPVal 250;
BA_REL_ "GenSigSuprvResp" BU_SG_REL_ EBCM_HS SG_ 647 EngCtrlUtldTrnCRgPVal 1;
BA_REL_ "GenSigTimeoutMsg" BU_SG_REL_ EBCM_HS SG_ 647 EngCtrlUtldTrnCRgPVal 647;
BA_REL_ "GenSigTimeoutTime" BU_SG_REL_ EBCM_HS SG_ 647 EngCtrlUtldTrnCRgPVal 250;
BA_REL_ "GenSigSuprvResp" BU_SG_REL_ EBCM_OBD_HS SG_ 647 EngCntrlUtldTrnCsRng 1;
BA_REL_ "GenSigTimeoutMsg" BU_SG_REL_ EBCM_OBD_HS SG_ 647 EngCntrlUtldTrnCsRng 647;
BA_REL_ "GenSigTimeoutTime" BU_SG_REL_ EBCM_OBD_HS SG_ 647 EngCntrlUtldTrnCsRng 250;
BA_REL_ "GenSigSuprvResp" BU_SG_REL_ EBCM_HS SG_ 647 EngCntrlUtldTrnCsRng 1;
BA_REL_ "GenSigTimeoutMsg" BU_SG_REL_ EBCM_HS SG_ 647 EngCntrlUtldTrnCsRng 647;
BA_REL_ "GenSigTimeoutTime" BU_SG_REL_ EBCM_HS SG_ 647 EngCntrlUtldTrnCsRng 250;
BA_REL_ "GenSigSuprvResp" BU_SG_REL_ HCP_T_HS SG_ 647 EngCntrlUtldTrnCsRgIn 1;
BA_REL_ "GenSigTimeoutMsg" BU_SG_REL_ HCP_T_HS SG_ 647 EngCntrlUtldTrnCsRgIn 647;
BA_REL_ "GenSigTimeoutTime" BU_SG_REL_ HCP_T_HS SG_ 647 EngCntrlUtldTrnCsRgIn 250;
BA_REL_ "GenSigSuprvResp" BU_SG_REL_ EBCM_OBD_HS SG_ 647 EngCntrlUtldTrnCsRgIn 1;
BA_REL_ "GenSigTimeoutMsg" BU_SG_REL_ EBCM_OBD_HS SG_ 647 EngCntrlUtldTrnCsRgIn 647;
BA_REL_ "GenSigTimeoutTime" BU_SG_REL_ EBCM_OBD_HS SG_ 647 EngCntrlUtldTrnCsRgIn 250;
BA_REL_ "GenSigSuprvResp" BU_SG_REL_ EBCM_HS SG_ 647 EngCntrlUtldTrnCsRgIn 1;
BA_REL_ "GenSigTimeoutMsg" BU_SG_REL_ EBCM_HS SG_ 647 EngCntrlUtldTrnCsRgIn 647;
BA_REL_ "GenSigTimeoutTime" BU_SG_REL_ EBCM_HS SG_ 647 EngCntrlUtldTrnCsRgIn 250;
BA_REL_ "GenSigSuprvResp" BU_SG_REL_ HCP_T_HS SG_ 647 EngCtrlUtldTrnCRgARC 1;
BA_REL_ "GenSigTimeoutMsg" BU_SG_REL_ HCP_T_HS SG_ 647 EngCtrlUtldTrnCRgARC 647;
BA_REL_ "GenSigTimeoutTime" BU_SG_REL_ HCP_T_HS SG_ 647 EngCtrlUtldTrnCRgARC 250;
BA_REL_ "GenSigSuprvResp" BU_SG_REL_ EBCM_OBD_HS SG_ 647 EngCtrlUtldTrnCRgARC 1;
BA_REL_ "GenSigTimeoutMsg" BU_SG_REL_ EBCM_OBD_HS SG_ 647 EngCtrlUtldTrnCRgARC 647;
BA_REL_ "GenSigTimeoutTime" BU_SG_REL_ EBCM_OBD_HS SG_ 647 EngCtrlUtldTrnCRgARC 250;
BA_REL_ "GenSigSuprvResp" BU_SG_REL_ EBCM_HS SG_ 647 EngCtrlUtldTrnCRgARC 1;
BA_REL_ "GenSigTimeoutMsg" BU_SG_REL_ EBCM_HS SG_ 647 EngCtrlUtldTrnCRgARC 647;
BA_REL_ "GenSigTimeoutTime" BU_SG_REL_ EBCM_HS SG_ 647 EngCtrlUtldTrnCRgARC 250;
VAL_ 565 PerfMdMainMenuType 7 "Reserved" 6 "Reserved" 5 "Reserved" 4 "Reserved" 3 "Main Menu Type 3" 2 "Main Menu Type 2" 1 "Main Menu Type 1" 0 "No Action" ;
VAL_ 565 PSPMCA_PsngStPrfMd6Avl 1 "true" 0 "false" ;
VAL_ 565 PSPMCA_PsngStPrfMd5Avl 1 "true" 0 "false" ;
VAL_ 565 PSPMCA_PsngStPrfMd4Avl 1 "true" 0 "false" ;
VAL_ 565 PSPMCA_PsngStPrfMd3Avl 1 "true" 0 "false" ;
VAL_ 565 PSPMCA_PsngStPrfMd2Avl 1 "true" 0 "false" ;
VAL_ 565 PSPMCA_PsngStPrfMd1Avl 1 "true" 0 "false" ;
VAL_ 565 DSPMCA_DrvStyPrfMd7Avl 1 "true" 0 "false" ;
VAL_ 565 DSPMCA_DrvStyPrfMd6Avl 1 "true" 0 "false" ;
VAL_ 565 DSPMCA_DrvStyPrfMd5Avl 1 "true" 0 "false" ;
VAL_ 565 DSPMCA_DrvStyPrfMd4Avl 1 "true" 0 "false" ;
VAL_ 565 DSPMCA_DrvStyPrfMd3Avl 1 "true" 0 "false" ;
VAL_ 565 DSPMCA_DrvStyPrfMd2Avl 1 "true" 0 "false" ;
VAL_ 565 DSPMCA_DrvStyPrfMd1Avl 1 "true" 0 "false" ;
VAL_ 565 DSPMCA_DrvrStPrfMd6Avl 1 "true" 0 "false" ;
VAL_ 565 DSPMCA_DrvrStPrfMd5Avl 1 "true" 0 "false" ;
VAL_ 565 DSPMCA_DrvrStPrfMd4Avl 1 "true" 0 "false" ;
VAL_ 565 DSPMCA_DrvrStPrfMd3Avl 1 "true" 0 "false" ;
VAL_ 565 DSPMCA_DrvrStPrfMd2Avl 1 "true" 0 "false" ;
VAL_ 565 DSPMCA_DrvrStPrfMd1Avl 1 "true" 0 "false" ;
VAL_ 565 ACCPMCA_ACCPrfMd6Avl 1 "true" 0 "false" ;
VAL_ 565 ACCPMCA_ACCPrfMd5Avl 1 "true" 0 "false" ;
VAL_ 565 ACCPMCA_ACCPrfMd4Avl 1 "true" 0 "false" ;
VAL_ 565 ACCPMCA_ACCPrfMd3Avl 1 "true" 0 "false" ;
VAL_ 565 ACCPMCA_ACCPrfMd2Avl 1 "true" 0 "false" ;
VAL_ 565 ACCPMCA_ACCPrfMd1Avl 1 "true" 0 "false" ;
VAL_ 1029 GFHBFwVsnRelLaneTrk6 3 "Left Lane" 2 "Right Lane" 1 "Host Lane" 0 "Unknown" ;
VAL_ 1029 GFHBFwVsnCnfdncTrk6 3 "Confident" 2 "Speculative" 1 "Highly Speculative" 0 "Invalid" ;
VAL_ 1029 GFHBFVsnObjTypTrkRev6 12 "Cluster Object" 11 "Child Close to Danger Zone" 10 "Pedestrian Moving Out of Danger Zone" 9 "Pedestrian Moving Into Danger Zone" 8 "Pedestrian Standing Outside Danger Zone" 7 "No Object Present" 6 "Fixed Roadside Object" 5 "Fixed Overhead Object" 4 "Pedestrian" 3 "Motorcycle/ Bicycle" 2 "Large Vehicle (Semi)" 1 "4 Wheel Vehicle (Car)" 0 "Unknown" ;
VAL_ 1029 GFHBObjDirTrk6 1 "Ahead Traffic" 0 "Incoming Traffic" ;
VAL_ 1029 GFHBFwVsnMesStatTrk6 3 "Measured this cycle" 2 "Latent track not detected this cycle" 1 "New Object" 0 "No Object" ;
VAL_ 1028 GFHBFwVsnRelLaneTrk5 3 "Left Lane" 2 "Right Lane" 1 "Host Lane" 0 "Unknown" ;
VAL_ 1028 GFHBFwVsnCnfdncTrk5 3 "Confident" 2 "Speculative" 1 "Highly Speculative" 0 "Invalid" ;
VAL_ 1028 GFHBFVsnObjTypTrkRev5 12 "Cluster Object" 11 "Child Close to Danger Zone" 10 "Pedestrian Moving Out of Danger Zone" 9 "Pedestrian Moving Into Danger Zone" 8 "Pedestrian Standing Outside Danger Zone" 7 "No Object Present" 6 "Fixed Roadside Object" 5 "Fixed Overhead Object" 4 "Pedestrian" 3 "Motorcycle/ Bicycle" 2 "Large Vehicle (Semi)" 1 "4 Wheel Vehicle (Car)" 0 "Unknown" ;
VAL_ 1028 GFHBObjDirTrk5 1 "Ahead Traffic" 0 "Incoming Traffic" ;
VAL_ 1028 GFHBFwVsnMesStatTrk5 3 "Measured this cycle" 2 "Latent track not detected this cycle" 1 "New Object" 0 "No Object" ;
VAL_ 500 EnhDrvMdSwChUseAct 1 "true" 0 "false" ;
VAL_ 500 EnhDrvSelMdSwStat 0 "No Activation" 1 "Increment" 2 "Decrement" 3 "Faulted" ;
VAL_ 500 DrvSelMd8Stat 1 "Active" 0 "Inactive" ;
VAL_ 500 DrvSelMd8ReqDnd 1 "true" 0 "false" ;
VAL_ 500 DrvSelMd7Stat 1 "Active" 0 "Inactive" ;
VAL_ 500 DrvSelMd7ReqDnd 1 "true" 0 "false" ;
VAL_ 500 DrvSelMd6Stat 1 "Active" 0 "Inactive" ;
VAL_ 500 DrvSelMd6ReqDnd 1 "true" 0 "false" ;
VAL_ 500 DrvSelMd5Stat 1 "Active" 0 "Inactive" ;
VAL_ 500 DrvSelMd5ReqDnd 1 "true" 0 "false" ;
VAL_ 500 DrvSelMd4Stat 1 "Active" 0 "Inactive" ;
VAL_ 500 DrvSelMd4ReqDnd 1 "true" 0 "false" ;
VAL_ 500 DrvSelMd3Stat 1 "Active" 0 "Inactive" ;
VAL_ 500 DrvSelMd3ReqDnd 1 "true" 0 "false" ;
VAL_ 500 DrvSelMd2Stat 1 "Active" 0 "Inactive" ;
VAL_ 500 DrvSelMd2ReqDnd 1 "true" 0 "false" ;
VAL_ 500 DSMSS_DrvSelMd0Pn 1 "true" 0 "false" ;
VAL_ 500 DSMSS_DrvSelMd8Pn 1 "true" 0 "false" ;
VAL_ 500 DSMSS_DrvSelMd7Pn 1 "true" 0 "false" ;
VAL_ 500 DSMSS_DrvSelMd6Pn 1 "true" 0 "false" ;
VAL_ 500 DSMSS_DrvSelMd5Pn 1 "true" 0 "false" ;
VAL_ 500 DSMSS_DrvSelMd4Pn 1 "true" 0 "false" ;
VAL_ 500 DSMSS_DrvSelMd3Pn 1 "true" 0 "false" ;
VAL_ 500 DSMSS_DrvSelMd2Pn 1 "true" 0 "false" ;
VAL_ 500 DSMSS_DrvSelMd1Pn 1 "true" 0 "false" ;
VAL_ 500 DSMSS_DrvSelMd8Un 1 "true" 0 "false" ;
VAL_ 500 DSMSS_DrvSelMd7Un 1 "true" 0 "false" ;
VAL_ 500 DSMSS_DrvSelMd6Un 1 "true" 0 "false" ;
VAL_ 500 DSMSS_DrvSelMd5Un 1 "true" 0 "false" ;
VAL_ 500 DSMSS_DrvSelMd4Un 1 "true" 0 "false" ;
VAL_ 500 DSMSS_DrvSelMd3Un 1 "true" 0 "false" ;
VAL_ 500 DSMSS_DrvSelMd2Un 1 "true" 0 "false" ;
VAL_ 500 DSMSS_DrvSelMd1Un 1 "true" 0 "false" ;
VAL_ 500 DrvSelMd1ReqDnd 1 "true" 0 "false" ;
VAL_ 500 DrvSelMd1Stat 1 "Active" 0 "Inactive" ;
VAL_ 1417 ETC_EngOpMd 1 "Half Cylinders" 0 "All cylinders" ;
VAL_ 407 TEPI_TrnsEngdPrFlwStV 1 "Invalid" 0 "Valid" ;
VAL_ 407 TEPI_TrnsEngdPrFlwSt 7 "Unused and Reserved4" 6 "Unused and Reserved3" 5 "Unused and Reserved2" 4 "Unused and Reserved1" 3 "Reverse Engaged" 2 "Drive Engaged" 1 "No Powerflow" 0 "Unavailable " ;
VAL_ 407 TransRatioV 1 "Invalid" 0 "Valid" ;
VAL_ 407 TrnsOvrallActTorqRatioV 1 "Invalid" 0 "Valid" ;
VAL_ 189 HybDisengCruzCmnd 1 "true" 0 "false" ;
VAL_ 189 TrnsRtoCntlSysFlt 1 "true" 0 "false" ;
VAL_ 189 TrnsInpMinSpdRq 0 "Unused and Reserved" 1 "Speed Point 1" 2 "Speed Point 2" 3 "Speed Point 3" 4 "Speed Point 4" 5 "Speed Point 5" 6 "Speed Point 6" 7 "Speed Point 7" 8 "Speed Point 8" 9 "Speed Point 9" 10 "Speed Point 10" 11 "Speed Point 11" 12 "Speed Point 12" 13 "Speed Point 13" 14 "Speed Point 14" 15 "Speed Point 15" ;
VAL_ 187 TransCltch5FillCmd 0 "Exhaust Clutch" 1 "Fill Clutch" 2 "Lock Clutch" 3 "Prefill Clutch" ;
VAL_ 187 TransCltch4FillCmd 0 "Exhaust Clutch" 1 "Fill Clutch" 2 "Lock Clutch" 3 "Prefill Clutch" ;
VAL_ 185 TransCltch1FillCmd 0 "Exhaust Clutch" 1 "Fill Clutch" 2 "Lock Clutch" 3 "Prefill Clutch" ;
VAL_ 185 TransCltch1CntlRq 0 "No Control" 1 "Active Control" 2 "Passive Control" 3 "Unused and Reserved" ;
VAL_ 185 TransCltch5CntlRq 0 "No Control" 1 "Active Control" 2 "Passive Control" 3 "Unused and Reserved" ;
VAL_ 185 TransCltch4CntlRq 0 "No Control" 1 "Active Control" 2 "Passive Control" 3 "Unused and Reserved" ;
VAL_ 185 TransCltch3CntlRq 0 "No Control" 1 "Active Control" 2 "Passive Control" 3 "Unused and Reserved" ;
VAL_ 185 TransCltch2CntlRq 0 "No Control" 1 "Active Control" 2 "Passive Control" 3 "Unused and Reserved" ;
VAL_ 186 TransCltch3FillCmd 0 "Exhaust Clutch" 1 "Fill Clutch" 2 "Lock Clutch" 3 "Prefill Clutch" ;
VAL_ 186 TransCltch2FillCmd 0 "Exhaust Clutch" 1 "Fill Clutch" 2 "Lock Clutch" 3 "Prefill Clutch" ;
VAL_ 152 TransClch5FlAch 1 "true" 0 "false" ;
VAL_ 152 TransClch5_Avail 1 "true" 0 "false" ;
VAL_ 152 TransClch4FlAch 1 "true" 0 "false" ;
VAL_ 152 TransClch4_Avail 1 "true" 0 "false" ;
VAL_ 151 TransClch3FlAch 1 "true" 0 "false" ;
VAL_ 151 TransClch3_Avail 1 "true" 0 "false" ;
VAL_ 151 TransClch2FlAch 1 "true" 0 "false" ;
VAL_ 151 TransClch2_Avail 1 "true" 0 "false" ;
VAL_ 150 TrnsInpDvcStat 7 "Unused and Reserved 5" 6 "Unused and Reserved 4" 5 "Unused and Reserved 3" 4 "Unused and Reserved 2" 3 "Unused and Reserved 1" 2 "Permanent Isolation" 1 "Temporary Isolation" 0 "Normal Control" ;
VAL_ 150 TransInhibitNeut 1 "true" 0 "false" ;
VAL_ 150 TransInhibitMode2 1 "true" 0 "false" ;
VAL_ 150 TransInhibitMode1 1 "true" 0 "false" ;
VAL_ 150 TransInhibitGear4 1 "true" 0 "false" ;
VAL_ 150 TransInhibitGear3 1 "true" 0 "false" ;
VAL_ 150 TransInhibitGear2 1 "true" 0 "false" ;
VAL_ 150 TransInhibitGear1 1 "true" 0 "false" ;
VAL_ 150 TrnsPTSysShtdwnRq 1 "true" 0 "false" ;
VAL_ 150 TransClch1FlAch 1 "true" 0 "false" ;
VAL_ 150 TransClch1_Avail 1 "true" 0 "false" ;
VAL_ 188 HybTransStCmmnd 0 "Neutral" 1 "Mode 1" 2 "Mode 2" 3 "Mode 3" 4 "Mode 4" 5 "Gear 1" 6 "Gear 2" 7 "Gear 3" 8 "Gear 4" 9 "Pseudo Gear 1" 10 "Unused and Reserved 2" 11 "Unused and Reserved 3" 12 "Unused and Reserved 4" 13 "Unused and Reserved 5" 14 "Unused and Reserved 6" 15 "Unused and Reserved 7" ;
VAL_ 188 HybTransStAchvd 0 "Neutral Stable State" 1 "EVT Mode 1 Stable State" 2 "EVT Mode 2 Stable State" 3 "EVT Mode 3 Stable State" 4 "EVT Mode 4 Stable State" 5 "Gear 1 Stable State" 6 "Gear 2 Stable State" 7 "Gear 3 Stable State" 8 "Gear 4 Stable State" 9 "Pseudo Gear 1 Stable State" 10 "Unused and Reserved 2" 11 "Unused and Reserved 3" 12 "Unused and Reserved 4" 13 "Unused and Reserved 5" 14 "Unused and Reserved 6" 15 "Unused and Reserved 7" ;
VAL_ 188 TransFldPmpCmd 0 "Normal" 1 "Prime On" 2 "Off" 3 "On" ;
VAL_ 188 TransDirctnStV 1 "Invalid" 0 "Valid" ;
VAL_ 188 TransDirctnSt 0 "Between Positions" 1 "Park" 2 "Reverse" 3 "Neutral" 4 "Drive" 5 "Unknown" ;
VAL_ 188 TnsClchFlLnePrsBstRq 1 "true" 0 "false" ;
VAL_ 188 TransAuxPumpAvail 1 "true" 0 "false" ;
VAL_ 188 MtrBSpdV 1 "Invalid" 0 "Valid" ;
VAL_ 188 MtrASpdV 1 "Invalid" 0 "Valid" ;
VAL_ 170 EngCommFlrRedPwrCm 1 "true" 0 "false" ;
VAL_ 170 CmndAxlTrqRespTyp 0 "Inactive" 1 "Pleasability Limit" 2 "Maximum Range" 3 "Automatic Actuator Selection" ;
VAL_ 1221 SpdLmtVsnFsdSpdUnt 0 "km/h" 1 "mph" ;
VAL_ 1221 SpdLmtVnFsSpdNwDet 1 "true" 0 "false" ;
VAL_ 1221 SpdLmtVsnFsdSpdM 0 "Don't Use Data" 1 "Use Data" ;
VAL_ 1243 CSERDTC_SysDes 0 "P0-Powertrain Codes SAE Controlled" 1 "P1-Powertrain Codes MFG Controlled" 2 "P2-Powertrain Codes Reserved" 3 "P3-Powertrain Codes Reserved" 4 "C0-Chassis Codes SAE Controlled" 5 "C1-Chassis Codes MFG Controlled" 6 "C2-Chassis Codes Reserved" 7 "C3-Chassis Codes Reserved" 8 "B0-Body Codes SAE Controlled" 9 "B1-Body Codes MFG Controlled" 10 "B2-Body Codes Reserved" 11 "B3-Body Codes Reserved" 12 "U0-Network Codes SAE Controlled" 13 "U1-Network Codes MFG Controlled" 14 "U2- Network Codes Reserved" 15 "U3-Network Codes Reserved" ;
VAL_ 1243 ChsSysEmmRelMalfAct 1 "true" 0 "false" ;
VAL_ 979 SpdLmtrSttngTypAct 3 "Reserved" 2 "Auto" 1 "Manual" 0 "Off" ;
VAL_ 979 SetSpdLmtRchd 3 "Reserved" 2 "Low limit reached" 1 "High limit reached" 0 "No limit reached" ;
VAL_ 979 ElvtdIdlCstCrStVal 0 "No Action" 1 "Off" 2 "On" ;
VAL_ 979 ElvtdIdlCstStAvl 1 "true" 0 "false" ;
VAL_ 979 PTABR_PTBrkRqAct 1 "true" 0 "false" ;
VAL_ 979 BrkBstVacV 1 "Invalid" 0 "Valid" ;
VAL_ 979 EngManfldAirTempCrtdV 1 "Invalid" 0 "Valid" ;
VAL_ 979 PltfrmEngSpdCmmndSt 3 "Request Denied" 2 "Lost Arbitration" 1 "Request Honored" 0 "No Request" ;
VAL_ 546 ThrmlRefCompStatFdbck 3 "Invalid" 2 "Inoperative" 1 "Degraded Operation" 0 "Normal Operation" ;
VAL_ 530 RstVTDTmprDtctd 1 "Reset" 0 "No Action" ;
VAL_ 530 RstIllDrIdDevDtctd 1 "Reset" 0 "No Action" ;
VAL_ 530 RstDrIdDevLrnd 1 "Reset" 0 "No Action" ;
VAL_ 1239 BattSOXStat 1 "Use SOC,SOH, & SOF" 0 "Don't Use SOC,SOH, & SOF" ;
VAL_ 1239 BattTempV 1 "Invalid" 0 "Valid" ;
VAL_ 1027 GFHBFwVsnRelLaneTrk4 3 "Left Lane" 2 "Right Lane" 1 "Host Lane" 0 "Unknown" ;
VAL_ 1027 GFHBFwVsnCnfdncTrk4 3 "Confident" 2 "Speculative" 1 "Highly Speculative" 0 "Invalid" ;
VAL_ 1027 GFHBFVsnObjTypTrkRev4 12 "Cluster Object" 11 "Child Close to Danger Zone" 10 "Pedestrian Moving Out of Danger Zone" 9 "Pedestrian Moving Into Danger Zone" 8 "Pedestrian Standing Outside Danger Zone" 7 "No Object Present" 6 "Fixed Roadside Object" 5 "Fixed Overhead Object" 4 "Pedestrian" 3 "Motorcycle/ Bicycle" 2 "Large Vehicle (Semi)" 1 "4 Wheel Vehicle (Car)" 0 "Unknown" ;
VAL_ 1027 GFHBObjDirTrk4 1 "Ahead Traffic" 0 "Incoming Traffic" ;
VAL_ 1027 GFHBFwVsnMesStatTrk4 3 "Measured this cycle" 2 "Latent track not detected this cycle" 1 "New Object" 0 "No Object" ;
VAL_ 1026 GFHBFwVsnRelLaneTrk3 3 "Left Lane" 2 "Right Lane" 1 "Host Lane" 0 "Unknown" ;
VAL_ 1026 GFHBFwVsnCnfdncTrk3 3 "Confident" 2 "Speculative" 1 "Highly Speculative" 0 "Invalid" ;
VAL_ 1026 GFHBFVsnObjTypTrkRev3 12 "Cluster Object" 11 "Child Close to Danger Zone" 10 "Pedestrian Moving Out of Danger Zone" 9 "Pedestrian Moving Into Danger Zone" 8 "Pedestrian Standing Outside Danger Zone" 7 "No Object Present" 6 "Fixed Roadside Object" 5 "Fixed Overhead Object" 4 "Pedestrian" 3 "Motorcycle/ Bicycle" 2 "Large Vehicle (Semi)" 1 "4 Wheel Vehicle (Car)" 0 "Unknown" ;
VAL_ 1026 GFHBObjDirTrk3 1 "Ahead Traffic" 0 "Incoming Traffic" ;
VAL_ 1026 GFHBFwVsnMesStatTrk3 3 "Measured this cycle" 2 "Latent track not detected this cycle" 1 "New Object" 0 "No Object" ;
VAL_ 1025 GFHBFwVsnRelLaneTrk2 3 "Left Lane" 2 "Right Lane" 1 "Host Lane" 0 "Unknown" ;
VAL_ 1025 GFHBFwVsnCnfdncTrk2 3 "Confident" 2 "Speculative" 1 "Highly Speculative" 0 "Invalid" ;
VAL_ 1025 GFHBFVsnObjTypTrkRev2 12 "Cluster Object" 11 "Child Close to Danger Zone" 10 "Pedestrian Moving Out of Danger Zone" 9 "Pedestrian Moving Into Danger Zone" 8 "Pedestrian Standing Outside Danger Zone" 7 "No Object Present" 6 "Fixed Roadside Object" 5 "Fixed Overhead Object" 4 "Pedestrian" 3 "Motorcycle/ Bicycle" 2 "Large Vehicle (Semi)" 1 "4 Wheel Vehicle (Car)" 0 "Unknown" ;
VAL_ 1025 GFHBObjDirTrk2 1 "Ahead Traffic" 0 "Incoming Traffic" ;
VAL_ 1025 GFHBFwVsnMesStatTrk2 3 "Measured this cycle" 2 "Latent track not detected this cycle" 1 "New Object" 0 "No Object" ;
VAL_ 1024 GFHBFwVsnRelLaneTrk1 3 "Left Lane" 2 "Right Lane" 1 "Host Lane" 0 "Unknown" ;
VAL_ 1024 GFHBFwVsnCnfdncTrk1 0 "Invalid" 3 "Confident" 2 "Speculative" 1 "Highly Speculative" ;
VAL_ 1024 GFHBFVsnObjTypTrkRev1 12 "Cluster Object" 11 "Child Close to Danger Zone" 10 "Pedestrian Moving Out of Danger Zone" 9 "Pedestrian Moving Into Danger Zone" 8 "Pedestrian Standing Outside Danger Zone" 7 "No Object Present" 6 "Fixed Roadside Object" 5 "Fixed Overhead Object" 4 "Pedestrian" 3 "Motorcycle/ Bicycle" 2 "Large Vehicle (Semi)" 1 "4 Wheel Vehicle (Car" 0 "Unknown" ;
VAL_ 1024 GFHBObjDirTrk1 1 "Ahead Traffic" 0 "Incoming Traffic" ;
VAL_ 1024 GFHBFwVsnMesStatTrk1 3 "Measured this cycle" 2 "Latent track not detected this cycle" 1 "New Object" 0 "No Object" ;
VAL_ 508 CSTBATS_TrqVlV 1 "Invalid" 0 "Valid" ;
VAL_ 422 TrnsAuxPrsDisOvrrdOn 1 "true" 0 "false" ;
VAL_ 422 TransEngShtdwnRqd 1 "true" 0 "false" ;
VAL_ 422 TransCrksftTqLoadV 1 "Invalid" 0 "Valid" ;
VAL_ 422 TrStPTGrdBrkDsMdOvr 3 "Unused and Reserved" 2 "To Grade Braking Disable" 1 "To Not Grade Braking Disable" 0 "No Override" ;
VAL_ 422 TrnsHybEngSrtStpOvrd 2 "Engine Off" 1 "Engine On" 0 "No Override" ;
VAL_ 647 EngDetPndTrnCsRngShfV 1 "Invalid" 0 "Valid" ;
VAL_ 647 EngDetPndTrnCsRngShf 3 "Shift Out of Neutral Range" 2 "Shift Out of Low Range" 1 "Shift Out of High Range" 0 "None" ;
VAL_ 647 CrpCstCrvCmd 7 "Creep Coast Curve 7" 6 "Creep Coast Curve 6" 5 "Creep Coast Curve 5" 4 "Creep Coast Curve 4" 3 "Creep Coast Curve 3" 2 "Creep Coast Curve 2" 1 "Creep Coast Curve 1" 0 "Creep Coast Curve 0" ;
VAL_ 647 DrvMntnMdCmnd 1 "true" 0 "false" ;
VAL_ 647 DrvHldMdCmnd 1 "true" 0 "false" ;
VAL_ 647 DrPTGrdBrkDsbMdCmd 1 "true" 0 "false" ;
VAL_ 647 DrvWntrMdCmd 1 "true" 0 "false" ;
VAL_ 647 DrvTwHaulMdCmd 1 "true" 0 "false" ;
VAL_ 647 DrvSprtMdCmd 1 "true" 0 "false" ;
VAL_ 647 DrvEconMdCmd 1 "true" 0 "false" ;
VAL_ 647 EngCntrlDtrmdTrfCRngV 1 "Invalid" 0 "Valid" ;
VAL_ 647 EngCntrlDtrmdTrfCRng 3 "Neutral" 2 "Unused and Reserved" 1 "Low" 0 "High" ;
VAL_ 647 EngCntrlUtldTrnCsRng 3 "Neutral" 2 "Unused and Reserved" 1 "Low" 0 "High" ;
VAL_ 647 EngCntrlUtldTrnCsRgIn 1 "true" 0 "false" ;
VAL_ 368 EnvIdRspSt5 0 "No info" 1 "Info valid" 2 "Incorrect immo id" 3 "Environment id request" ;
SIG_GROUP_ 565 PsngStPerfMdCustAvl 1 : PSPMCA_PsngStPrfMd6Avl PSPMCA_PsngStPrfMd5Avl PSPMCA_PsngStPrfMd4Avl PSPMCA_PsngStPrfMd3Avl PSPMCA_PsngStPrfMd2Avl PSPMCA_PsngStPrfMd1Avl;
SIG_GROUP_ 565 DrvStyPerfMdCustAvl 1 : DSPMCA_DrvStyPrfMd7Avl DSPMCA_DrvStyPrfMd6Avl DSPMCA_DrvStyPrfMd5Avl DSPMCA_DrvStyPrfMd4Avl DSPMCA_DrvStyPrfMd3Avl DSPMCA_DrvStyPrfMd2Avl DSPMCA_DrvStyPrfMd1Avl;
SIG_GROUP_ 565 DrvrStPerfMdCustAvl 1 : DSPMCA_DrvrStPrfMd6Avl DSPMCA_DrvrStPrfMd5Avl DSPMCA_DrvrStPrfMd4Avl DSPMCA_DrvrStPrfMd3Avl DSPMCA_DrvrStPrfMd2Avl DSPMCA_DrvrStPrfMd1Avl;
SIG_GROUP_ 565 ACCPerfMdCustAvl 1 : ACCPMCA_ACCPrfMd6Avl ACCPMCA_ACCPrfMd5Avl ACCPMCA_ACCPrfMd4Avl ACCPMCA_ACCPrfMd3Avl ACCPMCA_ACCPrfMd2Avl ACCPMCA_ACCPrfMd1Avl;
SIG_GROUP_ 500 DrvSelMdSelnStat 1 : DSMSS_DrvSelMd0Pn DSMSS_DrvSelMd8Pn DSMSS_DrvSelMd7Pn DSMSS_DrvSelMd6Pn DSMSS_DrvSelMd5Pn DSMSS_DrvSelMd4Pn DSMSS_DrvSelMd3Pn DSMSS_DrvSelMd2Pn DSMSS_DrvSelMd1Pn DSMSS_DrvSelMd8Un DSMSS_DrvSelMd7Un DSMSS_DrvSelMd6Un DSMSS_DrvSelMd5Un DSMSS_DrvSelMd4Un DSMSS_DrvSelMd3Un DSMSS_DrvSelMd2Un DSMSS_DrvSelMd1Un;
SIG_GROUP_ 1417 EngTorqCapblty 1 : ETC_MinTorq ETC_MinRunTorq ETC_MaxTorq ETC_RefEngSpd ETC_UnsdRsrvd ETC_FrmCntr ETC_EngOpMd;
SIG_GROUP_ 407 TransEngdPrFlwInfo 1 : TEPI_TrnsEngdPrFlwStV TEPI_TrnsEngdPrFlwSt;
SIG_GROUP_ 1243 ChsSysEmmRelDTC 1 : CSERDTC_CdNum CSERDTC_SysDes;
SIG_GROUP_ 979 PTAutoBrkReq 1 : PTABR_AccReq PTABR_PTBrkRqAct;
SIG_GROUP_ 508 ChsSysTtlBrkAxleTrqSt 1 : CSTBATS_TrqVl CSTBATS_TrqVlV;
